VERSION "HNNBNNNYNNNNNNNNNNNNNNNNNNNNNNNNNNNNNNNNNN/4/%%%/4/'%**4NNN///"

NS_ :

BS_:

BU_: Airbag BAP_Tester ICAS1_Gateway ICAS1_KommunikationsServer LE1 LE2 Motor_BEV Schaltbetaetigung

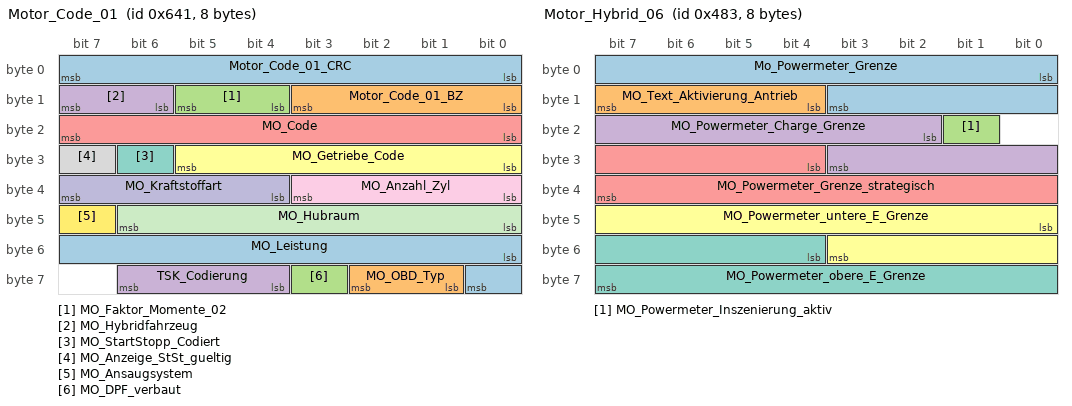
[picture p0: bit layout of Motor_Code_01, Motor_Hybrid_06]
BO_ 1601 Motor_Code_01: 8 Motor_BEV
 SG_ Motor_Code_01_CRC : 0|8@1+ (1,0) [0|255] ""  ICAS1_Gateway
 SG_ Motor_Code_01_BZ : 8|4@1+ (1,0) [0|15] ""  ICAS1_Gateway
 SG_ MO_Faktor_Momente_02 : 12|2@1+ (1,0) [1|3] "Unit_NewtoMeter"  ICAS1_Gateway
 SG_ MO_Hybridfahrzeug : 14|2@1+ (1.0,0.0) [0.0|3] ""  ICAS1_Gateway
 SG_ MO_Code : 16|8@1+ (1,0) [0|255] ""  ICAS1_Gateway
 SG_ MO_Getriebe_Code : 24|6@1+ (1.0,0.0) [0.0|63] ""  ICAS1_Gateway
 SG_ MO_StartStopp_Codiert : 30|1@1+ (1.0,0.0) [0.0|1] ""  ICAS1_Gateway
 SG_ MO_Anzeige_StSt_gueltig : 31|1@1+ (1.0,0.0) [0.0|1] ""  ICAS1_Gateway
 SG_ MO_Anzahl_Zyl : 32|4@1+ (1.0,0.0) [0.0|15] ""  ICAS1_Gateway
 SG_ MO_Kraftstoffart : 36|4@1+ (1.0,0.0) [0.0|15] ""  ICAS1_Gateway,ICAS1_KommunikationsServer
 SG_ MO_Hubraum : 40|7@1+ (0.1,0) [0.0|12.7] "Unit_Liter"  ICAS1_Gateway
 SG_ MO_Ansaugsystem : 47|1@1+ (1.0,0.0) [0.0|1] ""  ICAS1_Gateway
 SG_ MO_Leistung : 48|9@1+ (1,0) [0|511] "Unit_KiloWatt"  ICAS1_Gateway
 SG_ MO_OBD_Typ : 57|2@1+ (1.0,0.0) [0.0|3] ""  ICAS1_Gateway
 SG_ MO_DPF_verbaut : 59|1@1+ (1.0,0.0) [0.0|1] ""  ICAS1_Gateway
 SG_ TSK_Codierung : 60|3@1+ (1.0,0.0) [0.0|7] ""  ICAS1_Gateway

BO_ 1155 Motor_Hybrid_06: 8 Motor_BEV
 SG_ Mo_Powermeter_Grenze : 0|12@1+ (1,0) [0|4092] ""  ICAS1_KommunikationsServer
 SG_ MO_Text_Aktivierung_Antrieb : 12|4@1+ (1.0,0.0) [0.0|15] ""  ICAS1_KommunikationsServer
 SG_ MO_Powermeter_Inszenierung_aktiv : 17|1@1+ (1.0,0.0) [0.0|1] ""  Vector__XXX
 SG_ MO_Powermeter_Charge_Grenze : 18|10@1+ (1,0) [0|1021] "Unit_None"  ICAS1_KommunikationsServer
 SG_ MO_Powermeter_Grenze_strategisch : 28|12@1+ (1,0) [0|4093] "Unit_None"  ICAS1_KommunikationsServer
 SG_ MO_Powermeter_untere_E_Grenze : 40|12@1+ (1,0) [0|4093] "Unit_None"  Vector__XXX
 SG_ MO_Powermeter_obere_E_Grenze : 52|12@1+ (1,0) [0|4093] "Unit_None"  Vector__XXX

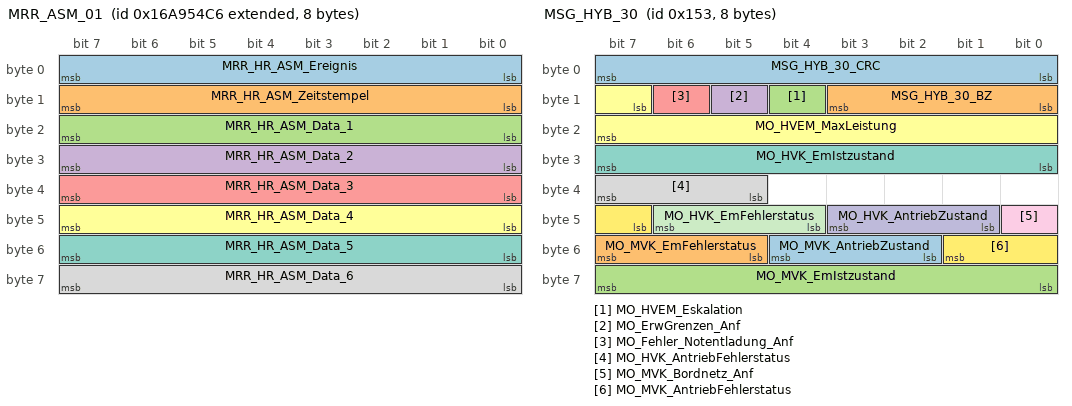
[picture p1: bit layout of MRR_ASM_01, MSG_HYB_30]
BO_ 2527679686 MRR_ASM_01: 8 ICAS1_Gateway
 SG_ MRR_HR_ASM_Ereignis : 0|8@1+ (1,0) [1|254] ""  Airbag
 SG_ MRR_HR_ASM_Zeitstempel : 8|8@1+ (0.08,0) [0.00|20.32] "Unit_Secon"  Airbag
 SG_ MRR_HR_ASM_Data_1 : 16|8@1+ (1,0) [0|255] ""  Airbag
 SG_ MRR_HR_ASM_Data_2 : 24|8@1+ (1,0) [0|255] ""  Airbag
 SG_ MRR_HR_ASM_Data_3 : 32|8@1+ (1,0) [0|255] ""  Airbag
 SG_ MRR_HR_ASM_Data_4 : 40|8@1+ (1,0) [0|255] ""  Airbag
 SG_ MRR_HR_ASM_Data_5 : 48|8@1+ (1,0) [0|255] ""  Airbag
 SG_ MRR_HR_ASM_Data_6 : 56|8@1+ (1,0) [0|255] ""  Airbag

BO_ 22 MSG3_WFS_Anfrage: 8 LE2
 SG_ WFS_MSG3_RND : 0|32@1+ (1.0,0.0) [0.0|4294967295] ""  ICAS1_Gateway
 SG_ WFS_MSG3_CRC : 32|32@1+ (1.0,0.0) [0.0|4294967295] ""  ICAS1_Gateway

BO_ 24 MSG4_WFS_Anfrage: 8 LE1
 SG_ WFS_MSG4_RND : 0|32@1+ (1.0,0.0) [0.0|4294967295] ""  ICAS1_Gateway
 SG_ WFS_MSG4_CRC : 32|32@1+ (1.0,0.0) [0.0|4294967295] ""  ICAS1_Gateway

BO_ 339 MSG_HYB_30: 8 Motor_BEV
 SG_ MSG_HYB_30_CRC : 0|8@1+ (1,0) [0|255] ""  Vector__XXX
 SG_ MSG_HYB_30_BZ : 8|4@1+ (1,0) [0|15] ""  Vector__XXX
 SG_ MO_HVEM_Eskalation : 12|1@1+ (1.0,0.0) [0.0|1] ""  ICAS1_Gateway
 SG_ MO_ErwGrenzen_Anf : 13|1@1+ (1.0,0.0) [0.0|1] ""  LE1,LE2
 SG_ MO_Fehler_Notentladung_Anf : 14|1@1+ (1.0,0.0) [0.0|1] ""  Vector__XXX
 SG_ MO_HVEM_MaxLeistung : 15|9@1+ (50,0) [0|25450] "Unit_Watt"  ICAS1_Gateway
 SG_ MO_HVK_EmIstzustand : 24|8@1+ (1.0,0.0) [0.0|255] ""  Vector__XXX
 SG_ MO_HVK_AntriebFehlerstatus : 37|3@1+ (1.0,0.0) [0.0|7] ""  Vector__XXX
 SG_ MO_MVK_Bordnetz_Anf : 40|1@1+ (1.0,0.0) [0.0|1] ""  Vector__XXX
 SG_ MO_HVK_AntriebZustand : 41|3@1+ (1.0,0.0) [0.0|7] ""  Vector__XXX
 SG_ MO_HVK_EmFehlerstatus : 44|3@1+ (1.0,0.0) [0.0|7] ""  Vector__XXX
 SG_ MO_MVK_AntriebFehlerstatus : 47|3@1+ (1.0,0.0) [0.0|7] ""  Vector__XXX
 SG_ MO_MVK_AntriebZustand : 50|3@1+ (1.0,0.0) [0.0|7] ""  Vector__XXX
 SG_ MO_MVK_EmFehlerstatus : 53|3@1+ (1.0,0.0) [0.0|7] ""  Vector__XXX
 SG_ MO_MVK_EmIstzustand : 56|8@1+ (1.0,0.0) [0.0|255] ""  Vector__XXX

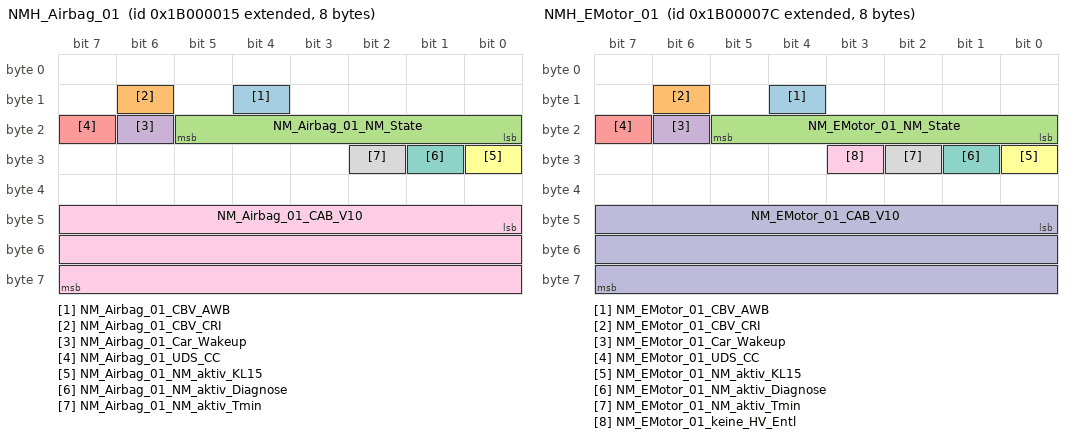
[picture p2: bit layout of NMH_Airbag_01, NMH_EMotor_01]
BO_ 2600468501 NMH_Airbag_01: 8 Airbag
 SG_ NM_Airbag_01_CBV_AWB : 12|1@1+ (1.0,0.0) [0.0|1] ""  ICAS1_Gateway
 SG_ NM_Airbag_01_CBV_CRI : 14|1@1+ (1.0,0.0) [0.0|1] ""  ICAS1_Gateway
 SG_ NM_Airbag_01_NM_State : 16|6@1+ (1.0,0.0) [0.0|63] ""  LE1,LE2,Motor_BEV,Schaltbetaetigung
 SG_ NM_Airbag_01_Car_Wakeup : 22|1@1+ (1.0,0.0) [0.0|1] ""  ICAS1_Gateway
 SG_ NM_Airbag_01_UDS_CC : 23|1@1+ (1.0,0.0) [0.0|1] ""  Vector__XXX
 SG_ NM_Airbag_01_NM_aktiv_KL15 : 24|1@1+ (1.0,0.0) [0.0|1] ""  Vector__XXX
 SG_ NM_Airbag_01_NM_aktiv_Diagnose : 25|1@1+ (1.0,0.0) [0.0|1] ""  Vector__XXX
 SG_ NM_Airbag_01_NM_aktiv_Tmin : 26|1@1+ (1.0,0.0) [0.0|1] ""  Vector__XXX
 SG_ NM_Airbag_01_CAB_V10 : 40|24@1+ (1.0,0.0) [0.0|16777215] ""  ICAS1_Gateway

BO_ 2600468604 NMH_EMotor_01: 8 LE1
 SG_ NM_EMotor_01_CBV_AWB : 12|1@1+ (1.0,0.0) [0.0|1] ""  ICAS1_Gateway
 SG_ NM_EMotor_01_CBV_CRI : 14|1@1+ (1.0,0.0) [0.0|1] ""  ICAS1_Gateway
 SG_ NM_EMotor_01_NM_State : 16|6@1+ (1.0,0.0) [0.0|63] ""  Airbag,LE2,Motor_BEV,Schaltbetaetigung
 SG_ NM_EMotor_01_Car_Wakeup : 22|1@1+ (1.0,0.0) [0.0|1] ""  ICAS1_Gateway
 SG_ NM_EMotor_01_UDS_CC : 23|1@1+ (1.0,0.0) [0.0|1] ""  Vector__XXX
 SG_ NM_EMotor_01_NM_aktiv_KL15 : 24|1@1+ (1.0,0.0) [0.0|1] ""  Vector__XXX
 SG_ NM_EMotor_01_NM_aktiv_Diagnose : 25|1@1+ (1.0,0.0) [0.0|1] ""  Vector__XXX
 SG_ NM_EMotor_01_NM_aktiv_Tmin : 26|1@1+ (1.0,0.0) [0.0|1] ""  Vector__XXX
 SG_ NM_EMotor_01_keine_HV_Entl : 27|1@1+ (1.0,0.0) [0.0|1] ""  Vector__XXX
 SG_ NM_EMotor_01_CAB_V10 : 40|24@1+ (1.0,0.0) [0.0|16777215] ""  ICAS1_Gateway

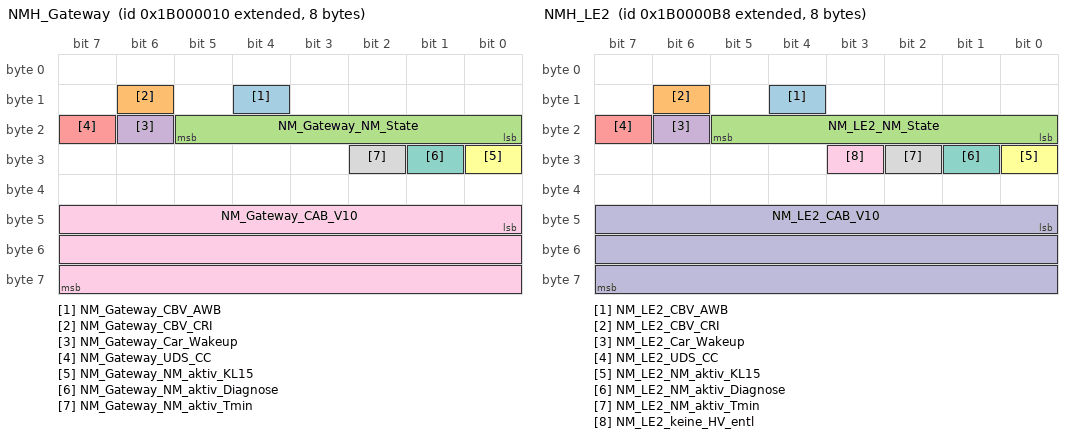
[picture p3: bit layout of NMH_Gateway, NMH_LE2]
BO_ 2600468496 NMH_Gateway: 8 ICAS1_Gateway
 SG_ NM_Gateway_CBV_AWB : 12|1@1+ (1.0,0.0) [0.0|1] ""  Vector__XXX
 SG_ NM_Gateway_CBV_CRI : 14|1@1+ (1.0,0.0) [0.0|1] ""  Vector__XXX
 SG_ NM_Gateway_NM_State : 16|6@1+ (1.0,0.0) [0.0|63] ""  Airbag,LE1,LE2,Motor_BEV,Schaltbetaetigung
 SG_ NM_Gateway_Car_Wakeup : 22|1@1+ (1.0,0.0) [0.0|1] ""  Vector__XXX
 SG_ NM_Gateway_UDS_CC : 23|1@1+ (1.0,0.0) [0.0|1] ""  Vector__XXX
 SG_ NM_Gateway_NM_aktiv_KL15 : 24|1@1+ (1.0,0.0) [0.0|1] ""  Vector__XXX
 SG_ NM_Gateway_NM_aktiv_Diagnose : 25|1@1+ (1.0,0.0) [0.0|1] ""  Vector__XXX
 SG_ NM_Gateway_NM_aktiv_Tmin : 26|1@1+ (1.0,0.0) [0.0|1] ""  Vector__XXX
 SG_ NM_Gateway_CAB_V10 : 40|24@1+ (1.0,0.0) [0.0|16777215] ""  Vector__XXX

BO_ 2600468664 NMH_LE2: 8 LE2
 SG_ NM_LE2_CBV_AWB : 12|1@1+ (1.0,0.0) [0.0|1] ""  ICAS1_Gateway
 SG_ NM_LE2_CBV_CRI : 14|1@1+ (1.0,0.0) [0.0|1] ""  ICAS1_Gateway
 SG_ NM_LE2_NM_State : 16|6@1+ (1.0,0.0) [0.0|63] ""  Airbag,LE1,Motor_BEV,Schaltbetaetigung
 SG_ NM_LE2_Car_Wakeup : 22|1@1+ (1.0,0.0) [0.0|1] ""  ICAS1_Gateway
 SG_ NM_LE2_UDS_CC : 23|1@1+ (1.0,0.0) [0.0|1] ""  Vector__XXX
 SG_ NM_LE2_NM_aktiv_KL15 : 24|1@1+ (1.0,0.0) [0.0|1] ""  Vector__XXX
 SG_ NM_LE2_NM_aktiv_Diagnose : 25|1@1+ (1.0,0.0) [0.0|1] ""  Vector__XXX
 SG_ NM_LE2_NM_aktiv_Tmin : 26|1@1+ (1.0,0.0) [0.0|1] ""  Vector__XXX
 SG_ NM_LE2_keine_HV_entl : 27|1@1+ (1.0,0.0) [0.0|1] ""  Vector__XXX
 SG_ NM_LE2_CAB_V10 : 40|24@1+ (1.0,0.0) [0.0|16777215] ""  ICAS1_Gateway

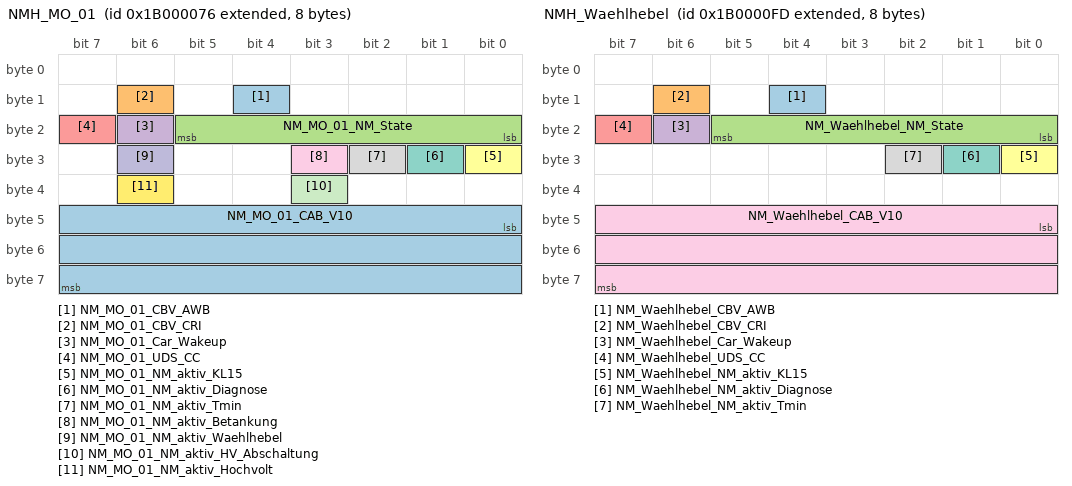
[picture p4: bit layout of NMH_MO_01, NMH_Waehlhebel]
BO_ 2600468598 NMH_MO_01: 8 Motor_BEV
 SG_ NM_MO_01_CBV_AWB : 12|1@1+ (1.0,0.0) [0.0|1] ""  ICAS1_Gateway
 SG_ NM_MO_01_CBV_CRI : 14|1@1+ (1.0,0.0) [0.0|1] ""  ICAS1_Gateway
 SG_ NM_MO_01_NM_State : 16|6@1+ (1.0,0.0) [0.0|63] ""  Airbag,LE1,LE2,Schaltbetaetigung
 SG_ NM_MO_01_Car_Wakeup : 22|1@1+ (1.0,0.0) [0.0|1] ""  ICAS1_Gateway
 SG_ NM_MO_01_UDS_CC : 23|1@1+ (1.0,0.0) [0.0|1] ""  Vector__XXX
 SG_ NM_MO_01_NM_aktiv_KL15 : 24|1@1+ (1.0,0.0) [0.0|1] ""  Vector__XXX
 SG_ NM_MO_01_NM_aktiv_Diagnose : 25|1@1+ (1.0,0.0) [0.0|1] ""  Vector__XXX
 SG_ NM_MO_01_NM_aktiv_Tmin : 26|1@1+ (1.0,0.0) [0.0|1] ""  Vector__XXX
 SG_ NM_MO_01_NM_aktiv_Betankung : 27|1@1+ (1.0,0.0) [0.0|1] ""  Vector__XXX
 SG_ NM_MO_01_NM_aktiv_Waehlhebel : 30|1@1+ (1.0,0.0) [0.0|1] ""  Vector__XXX
 SG_ NM_MO_01_NM_aktiv_HV_Abschaltung : 35|1@1+ (1.0,0.0) [0.0|1] ""  Vector__XXX
 SG_ NM_MO_01_NM_aktiv_Hochvolt : 38|1@1+ (1.0,0.0) [0.0|1] ""  Vector__XXX
 SG_ NM_MO_01_CAB_V10 : 40|24@1+ (1.0,0.0) [0.0|16777215] ""  ICAS1_Gateway

BO_ 2600468733 NMH_Waehlhebel: 8 Schaltbetaetigung
 SG_ NM_Waehlhebel_CBV_AWB : 12|1@1+ (1.0,0.0) [0.0|1] ""  ICAS1_Gateway
 SG_ NM_Waehlhebel_CBV_CRI : 14|1@1+ (1.0,0.0) [0.0|1] ""  ICAS1_Gateway
 SG_ NM_Waehlhebel_NM_State : 16|6@1+ (1.0,0.0) [0.0|63] ""  Airbag,LE1,LE2,Motor_BEV
 SG_ NM_Waehlhebel_Car_Wakeup : 22|1@1+ (1.0,0.0) [0.0|1] ""  ICAS1_Gateway
 SG_ NM_Waehlhebel_UDS_CC : 23|1@1+ (1.0,0.0) [0.0|1] ""  Vector__XXX
 SG_ NM_Waehlhebel_NM_aktiv_KL15 : 24|1@1+ (1.0,0.0) [0.0|1] ""  Vector__XXX
 SG_ NM_Waehlhebel_NM_aktiv_Diagnose : 25|1@1+ (1.0,0.0) [0.0|1] ""  Vector__XXX
 SG_ NM_Waehlhebel_NM_aktiv_Tmin : 26|1@1+ (1.0,0.0) [0.0|1] ""  Vector__XXX
 SG_ NM_Waehlhebel_CAB_V10 : 40|24@1+ (1.0,0.0) [0.0|16777215] ""  ICAS1_Gateway

BO_ 2621440533 OBDC_Airbag_01_Req_FD: 64 ICAS1_Gateway
 SG_ OBDC_Airbag_01_Req_FD_Data : 0|512@1+ (1.0,0.0) [0.0|13407807929942597099574024998205846127479365820592393377723561443721764030073546976801874298166903427690031858186486050853753882811946569946433649006084095] ""  Airbag

BO_ 2621571605 OBDC_Airbag_01_Resp_FD: 64 Airbag
 SG_ OBDC_Airbag_01_Resp_FD_Data : 0|512@1+ (1.0,0.0) [0.0|13407807929942597099574024998205846127479365820592393377723561443721764030073546976801874298166903427690031858186486050853753882811946569946433649006084095] ""  ICAS1_Gateway

BO_ 2621440636 OBDC_EMotor_01_Req_FD: 64 ICAS1_Gateway
 SG_ OBDC_EMotor_01_Req_FD_Data : 0|512@1+ (1.0,0.0) [0.0|13407807929942597099574024998205846127479365820592393377723561443721764030073546976801874298166903427690031858186486050853753882811946569946433649006084095] ""  LE1

BO_ 2621571708 OBDC_EMotor_01_Resp_FD: 64 LE1
 SG_ OBDC_EMotor_01_Resp_FD_Data : 0|512@1+ (1.0,0.0) [0.0|13407807929942597099574024998205846127479365820592393377723561443721764030073546976801874298166903427690031858186486050853753882811946569946433649006084095] ""  ICAS1_Gateway

BO_ 2621440696 OBDC_EMotor_02_Req_FD: 64 ICAS1_Gateway
 SG_ OBDC_EMotor_02_Req_FD_Data : 0|512@1+ (1.0,0.0) [0.0|13407807929942597099574024998205846127479365820592393377723561443721764030073546976801874298166903427690031858186486050853753882811946569946433649006084095] ""  LE2

BO_ 2621571768 OBDC_EMotor_02_Resp_FD: 64 LE2
 SG_ OBDC_EMotor_02_Resp_FD_Data : 0|512@1+ (1.0,0.0) [0.0|13407807929942597099574024998205846127479365820592393377723561443721764030073546976801874298166903427690031858186486050853753882811946569946433649006084095] ""  ICAS1_Gateway

BO_ 2621506048 OBDC_Funktionaler_Req_All_FD: 64 ICAS1_Gateway
 SG_ OBDC_Funktion_Req_All_FD_Data : 0|512@1+ (1.0,0.0) [0.0|13407807929942597099574024998205846127479365820592393377723561443721764030073546976801874298166903427690031858186486050853753882811946569946433649006084095] ""  Airbag,LE1,LE2,Motor_BEV

BO_ 2621440630 OBDC_MO_01_Req_FD: 64 ICAS1_Gateway
 SG_ OBDC_MO_01_Req_FD_Data : 0|512@1+ (1.0,0.0) [0.0|13407807929942597099574024998205846127479365820592393377723561443721764030073546976801874298166903427690031858186486050853753882811946569946433649006084095] ""  Motor_BEV

BO_ 2621571702 OBDC_MO_01_Resp_FD: 64 Motor_BEV
 SG_ OBDC_MO_01_Resp_FD_Data : 0|512@1+ (1.0,0.0) [0.0|13407807929942597099574024998205846127479365820592393377723561443721764030073546976801874298166903427690031858186486050853753882811946569946433649006084095] ""  ICAS1_Gateway

BO_ 2564502513 OBDx_allOBD_Req: 8 ICAS1_Gateway
 SG_ OBDx_allOBD_Req_Data : 0|64@1+ (1.0,0.0) [0.0|18446744073709551615] ""  LE1,LE2,Motor_BEV

BO_ 2564425457 OBDx_LE1_Req: 8 ICAS1_Gateway
 SG_ OBDx_LE1_Req_Data : 0|64@1+ (1.0,0.0) [0.0|18446744073709551615] ""  LE1

BO_ 2564485382 OBDx_LE1_Resp: 8 LE1
 SG_ OBDx_LE1_Resp_Data : 0|64@1+ (1.0,0.0) [0.0|18446744073709551615] ""  ICAS1_Gateway

BO_ 2564425713 OBDx_LE2_Req: 8 ICAS1_Gateway
 SG_ OBDx_LE2_Req_Data : 0|64@1+ (1.0,0.0) [0.0|18446744073709551615] ""  LE2

BO_ 2564485383 OBDx_LE2_Resp: 8 LE2
 SG_ OBDx_LE2_Resp_Data : 0|64@1+ (1.0,0.0) [0.0|18446744073709551615] ""  ICAS1_Gateway

BO_ 2564424177 OBDx_MO_01_Req: 8 ICAS1_Gateway
 SG_ OBDx_MO_01_Req_Data : 0|64@1+ (1.0,0.0) [0.0|18446744073709551615] ""  Motor_BEV

BO_ 2564485377 OBDx_MO_01_Resp: 8 Motor_BEV
 SG_ OBDx_MO_01_Resp_Data : 0|64@1+ (1.0,0.0) [0.0|18446744073709551615] ""  ICAS1_Gateway

BO_ 627 OCC_01: 24 ICAS1_Gateway
 SG_ OCC_01_CRC : 0|8@1+ (1,0) [0|255] ""  Vector__XXX
 SG_ OCC_01_BZ : 8|4@1+ (1,0) [0|15] ""  Vector__XXX
 SG_ OCC_Stecker_Status : 12|2@1+ (1.0,0.0) [0.0|3] ""  Vector__XXX
 SG_ OCC_Status_Spgfreiheit : 14|2@1+ (1.0,0.0) [0.0|3] ""  Motor_BEV
 SG_ OCC_DC_IstStrom : 16|11@1+ (0.1,0) [0.0|204.5] "Unit_Amper"  Vector__XXX
 SG_ OCC_CC_Latchstatus_DC_GBT : 27|3@1+ (1.0,0.0) [0.0|7] ""  Vector__XXX
 SG_ OCC_Status_EoHVL : 30|2@1+ (1.0,0.0) [0.0|3] ""  Motor_BEV
 SG_ OCC_I_istAC_Netz_L1 : 32|9@1+ (0.1,0) [0.0|50.8] "Unit_Amper"  Vector__XXX
 SG_ OCC_PP_Latchstatus_A : 41|3@1+ (1.0,0.0) [0.0|7] ""  Vector__XXX
 SG_ OCC_PP_Latchstatus_B : 44|3@1+ (1.0,0.0) [0.0|7] ""  Vector__XXX
 SG_ OCC_I_istAC_Netz_L2 : 47|9@1+ (0.1,0) [0.0|50.8] "Unit_Amper"  Vector__XXX
 SG_ OCC_I_istAC_Netz_L3 : 56|9@1+ (0.1,0) [0.0|50.8] "Unit_Amper"  Vector__XXX
 SG_ OCC_IstModus : 65|3@1+ (1.0,0.0) [0.0|7] ""  Motor_BEV
 SG_ OCC_CP_Status_A : 68|2@1+ (1.0,0.0) [0.0|3] ""  Vector__XXX
 SG_ OCC_CP_Status_B : 70|2@1+ (1.0,0.0) [0.0|3] ""  Vector__XXX
 SG_ OCC_IstSpannung_HV : 72|10@1+ (1,0) [0|1021] "Unit_Volt"  Vector__XXX
 SG_ OCC_PP_Status_A : 82|2@1+ (1.0,0.0) [0.0|3] ""  Vector__XXX
 SG_ OCC_PP_Status_B : 84|2@1+ (1.0,0.0) [0.0|3] ""  Vector__XXX
 SG_ OCC_CC_Status_DC_GBT : 86|2@1+ (1.0,0.0) [0.0|3] ""  Vector__XXX
 SG_ OCC_CC_Fehlerstatus_DC_GBT : 88|4@1+ (1.0,0.0) [0.0|15] ""  Vector__XXX
 SG_ OCC_Temp_Sensor_Fehlerstatus_DC : 92|4@1+ (1.0,0.0) [0.0|15] ""  Vector__XXX
 SG_ OCC_Temp_Sensor_Fehlerstatus_AC : 96|3@1+ (1.0,0.0) [0.0|7] ""  Vector__XXX
 SG_ OCC_Temp_Sensor_Status : 99|3@1+ (1.0,0.0) [0.0|7] ""  Vector__XXX

BO_ 2463978709 OCC_02: 32 ICAS1_Gateway
 SG_ OCC_CP_Tastgrad_A : 12|10@1+ (0.1,0) [0.0|100.0] "Unit_PerCent"  Vector__XXX
 SG_ OCC_CP_Tastgrad_B : 22|10@1+ (0.1,0) [0.0|100.0] "Unit_PerCent"  Vector__XXX
 SG_ OCC_CP_Frequenz_A : 32|8@1+ (1,880) [880|1132] "Unit_Hertz"  Vector__XXX
 SG_ OCC_CP_Frequenz_B : 40|8@1+ (1,880) [880|1132] "Unit_Hertz"  Vector__XXX
 SG_ OCC_CP_Spannung_A : 48|9@1+ (0.1,-25) [-25.0|25.9] "Unit_Volt"  Vector__XXX
 SG_ OCC_CP_Spannung_B : 57|9@1+ (0.1,-25) [-25.0|25.9] "Unit_Volt"  Vector__XXX
 SG_ OCC_CP_Fehlerstatus_A : 66|3@1+ (1.0,0.0) [0.0|7] ""  Vector__XXX
 SG_ OCC_CP_Fehlerstatus_B : 69|3@1+ (1.0,0.0) [0.0|7] ""  Vector__XXX
 SG_ OCC_Temp_Ladedose_A_AC : 72|8@1+ (1,-40) [-40|213] "Unit_DegreCelsi"  Vector__XXX
 SG_ OCC_Temp_Ladedose_A_DC_minus : 80|8@1+ (1,-40) [-40|213] "Unit_DegreCelsi"  Vector__XXX
 SG_ OCC_Temp_Ladedose_A_DC_plus : 88|8@1+ (1,-40) [-40|213] "Unit_DegreCelsi"  Vector__XXX
 SG_ OCC_U_istAC_Netz_L1 : 96|9@1+ (1,0) [0|509] "Unit_Volt"  Vector__XXX
 SG_ OCC_U_istAC_Netz_L2 : 105|9@1+ (1,0) [0|509] "Unit_Volt"  Vector__XXX
 SG_ OCC_U_istAC_Netz_L3 : 114|9@1+ (1,0) [0|508] "Unit_Volt"  Vector__XXX
 SG_ OCC_StatusVerEntriegelungAktor_A : 123|3@1+ (1.0,0.0) [0.0|7] ""  Vector__XXX
 SG_ OCC_SteckerEntriegelung_Verbot_A : 126|2@1+ (1.0,0.0) [0.0|3] ""  Vector__XXX
 SG_ OCC_StatusVerEntriegelungAktor_B : 128|3@1+ (1.0,0.0) [0.0|7] ""  Vector__XXX
 SG_ OCC_SteckerEntriegelung_Verbot_B : 131|2@1+ (1.0,0.0) [0.0|3] ""  Vector__XXX
 SG_ OCC_Verriegelung_Status_A : 133|3@1+ (1.0,0.0) [0.0|7] ""  Vector__XXX
 SG_ OCC_Verriegelung_Status_B : 136|3@1+ (1.0,0.0) [0.0|7] ""  Vector__XXX
 SG_ OCC_RtmWarnLadeKommunikation : 139|3@1+ (1.0,0.0) [0.0|7] ""  Vector__XXX
 SG_ OCC_Ist_Wirkungsgrad : 145|7@1+ (1,0) [0|100] "Unit_PerCent"  Vector__XXX
 SG_ OCC_PP_Max_Strom_A : 152|4@1+ (1.0,0.0) [0.0|15] ""  Vector__XXX
 SG_ OCC_PP_Max_Strom_B : 156|4@1+ (1.0,0.0) [0.0|15] ""  Vector__XXX
 SG_ OCC_DC_MaxStrom : 160|11@1+ (0.1,0) [0.0|204.5] "Unit_Amper"  Vector__XXX
 SG_ OCC_Derating_Temperatur : 171|1@1+ (1.0,0.0) [0.0|1] ""  Vector__XXX
 SG_ OCC_Fehlerzustand : 172|1@1+ (1.0,0.0) [0.0|1] ""  Vector__XXX
 SG_ OCC_Ladest_Entriegelungs_Verbot : 173|3@1+ (1.0,0.0) [0.0|7] ""  Vector__XXX
 SG_ OCC_Netzfrequenz_EVU : 176|9@1+ (0.1,40) [40.0|80.0] "Unit_Hertz"  Vector__XXX
 SG_ OCC_Warnzustand : 185|1@1+ (1.0,0.0) [0.0|1] ""  Vector__XXX
 SG_ OCC_Kuehltemperatur : 192|8@1+ (1,-40) [-40|213] "Unit_DegreCelsi"  Motor_BEV
 SG_ OCC_PP_Fehlerstatus_A : 200|4@1+ (1.0,0.0) [0.0|15] ""  Vector__XXX
 SG_ OCC_PP_Fehlerstatus_B : 204|4@1+ (1.0,0.0) [0.0|15] ""  Vector__XXX

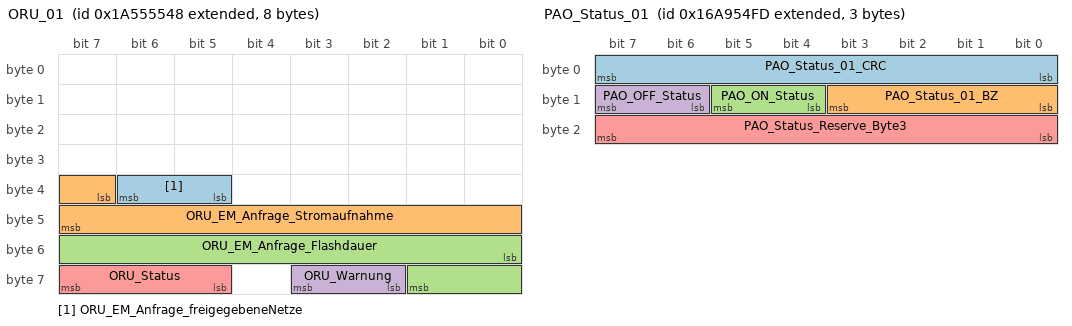
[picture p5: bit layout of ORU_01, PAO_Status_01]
BO_ 2589283656 ORU_01: 8 ICAS1_Gateway
 SG_ ORU_EM_Anfrage_freigegebeneNetze : 37|2@1+ (1.0,0.0) [0.0|3] ""  Vector__XXX
 SG_ ORU_EM_Anfrage_Stromaufnahme : 39|9@1+ (0.1,0) [0.0|51.1] "Unit_Amper"  Vector__XXX
 SG_ ORU_EM_Anfrage_Flashdauer : 48|10@1+ (10,0) [0|10230] "Unit_Secon"  Vector__XXX
 SG_ ORU_Warnung : 58|2@1+ (1.0,0.0) [0.0|3] ""  Vector__XXX
 SG_ ORU_Status : 61|3@1+ (1.0,0.0) [0.0|7] ""  Airbag,LE1,LE2,Motor_BEV

BO_ 2527679741 PAO_Status_01: 3 ICAS1_Gateway
 SG_ PAO_Status_01_CRC : 0|8@1+ (1,0) [0|255] ""  Airbag
 SG_ PAO_Status_01_BZ : 8|4@1+ (1,0) [0|15] ""  Airbag
 SG_ PAO_ON_Status : 12|2@1+ (1.0,0.0) [0.0|3] ""  Airbag
 SG_ PAO_OFF_Status : 14|2@1+ (1.0,0.0) [0.0|3] ""  Airbag
 SG_ PAO_Status_Reserve_Byte3 : 16|8@1+ (1.0,0.0) [0.0|255] ""  Vector__XXX

BO_ 518 Parken_01: 24 ICAS1_Gateway
 SG_ Parken_BKD_Anf : 12|4@1+ (0.1,0) [0.0|1.3] "Unit_Secon"  Vector__XXX
 SG_ Parken_Verz_Anf : 16|7@1+ (0.1,-12.6) [-12.6|-0.1] "Unit_MeterPerSeconSquar"  Vector__XXX
 SG_ Parken_Prefill_Anf : 23|1@1+ (1.0,0.0) [0.0|1] ""  Vector__XXX
 SG_ Parken_Warnruck_Anf : 24|2@1+ (1.0,0.0) [0.0|3] ""  Vector__XXX
 SG_ Parken_Verz_Anf_ASIL : 26|2@1+ (1.0,0.0) [0.0|3] ""  Vector__XXX
 SG_ Parken_Warnruckeln_Anf : 28|2@1+ (1.0,0.0) [0.0|3] ""  Vector__XXX
 SG_ Parken_beibehalten : 30|2@1+ (1.0,0.0) [0.0|3] ""  Vector__XXX
 SG_ Parken_Anforderung_HMS : 32|3@1+ (1.0,0.0) [0.0|7] ""  Vector__XXX
 SG_ Parken_Notstopp_Anf : 40|2@1+ (1.0,0.0) [0.0|3] ""  Vector__XXX
 SG_ Parken_Anhalteweg_Anf : 42|10@1+ (0.01,0) [0.00|10.21] "Unit_Meter"  Vector__XXX
 SG_ Parken_aktives_System : 52|4@1+ (1.0,0.0) [0.0|15] ""  Motor_BEV
 SG_ Parken_max_Beschleunigung : 56|7@1+ (0.1,-6) [-5.9|6.1] "Unit_MeterPerSeconSquar"  Motor_BEV
 SG_ Parken_Blinker_li_Anf : 63|1@1+ (1.0,0.0) [0.0|1] ""  Vector__XXX
 SG_ Parken_QFK_KruemmSoll : 64|15@1+ (0.0000067,0) [0E-7|0.2195389] "Unit_MeterInver"  Vector__XXX
 SG_ Parken_QFK_KruemmSoll_VZ : 79|1@1+ (1.0,0.0) [0.0|1] ""  Vector__XXX
 SG_ Parken_QFK_Spuerb : 80|8@1+ (0.4,0) [0.0|100.0] "Unit_PerCent"  Vector__XXX
 SG_ Parken_QFK_AnfStat : 88|4@1+ (1.0,0.0) [0.0|15] ""  Vector__XXX
 SG_ Parken_QFK_Signal1 : 92|10@1+ (1,0) [0|1023] ""  Vector__XXX
 SG_ Parken_QFK_Art1 : 102|3@1+ (1,0) [0|7] ""  Vector__XXX
 SG_ Parken_QFK_Art2 : 105|3@1+ (1,0) [0|7] ""  Vector__XXX
 SG_ Parken_QFK_Signal2 : 108|10@1+ (1,0) [0|1023] ""  Vector__XXX
 SG_ Parken_Sollbeschleunigung : 118|9@1+ (0.01,-4.11) [-4.10|1.00] "Unit_MeterPerSeconSquar"  Motor_BEV
 SG_ Parken_Blinker_re_Anf : 127|1@1+ (1.0,0.0) [0.0|1] ""  Vector__XXX
 SG_ Parken_Status_IPA_TSK : 128|4@1+ (1.0,0.0) [0.0|15] ""  Motor_BEV
 SG_ Parken_erhoehtes_Moment : 132|4@1+ (1.0,0.0) [0.0|15] ""  Motor_BEV
 SG_ Parken_max_Geschwindigkeit : 136|8@1+ (0.1,0) [0.1|25.0] "Unit_KiloMeterPerHour"  Motor_BEV
 SG_ Parken_Soll_Anhalteweg_Anf : 144|10@1+ (0.01,0) [0.00|10.21] "Unit_Meter"  Vector__XXX
 SG_ Parken_Fahrstufenwunsch : 154|3@1+ (1.0,0.0) [0.0|7] ""  Motor_BEV
 SG_ IPA_TPA_Remote : 157|2@1+ (1.0,0.0) [0.0|3] ""  Vector__XXX
 SG_ IPA_TPA_Remote_Anf : 159|1@1+ (1.0,0.0) [0.0|1] ""  Vector__XXX
 SG_ IPA_TPA_Fehler : 160|4@1+ (1.0,0.0) [0.0|15] ""  Vector__XXX
 SG_ IPA_TPA_Abbruch : 164|4@1+ (1.0,0.0) [0.0|15] ""  Vector__XXX
 SG_ IPA_TPA_Status : 168|4@1+ (1.0,0.0) [0.0|15] ""  Vector__XXX

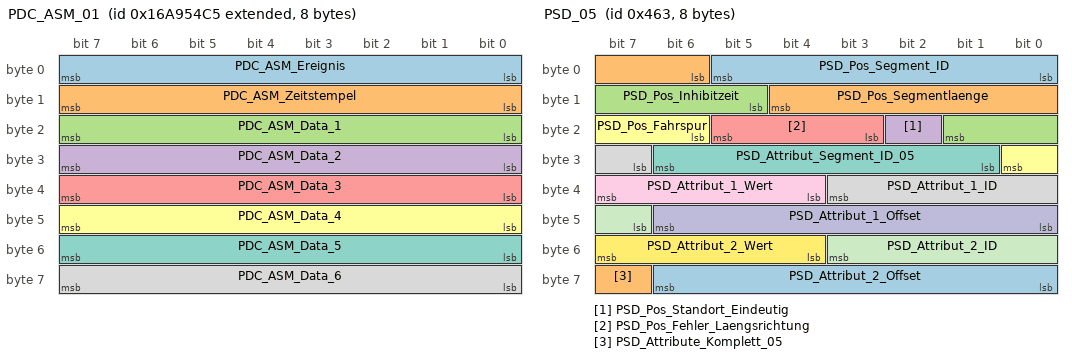
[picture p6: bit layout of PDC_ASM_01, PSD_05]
BO_ 2527679685 PDC_ASM_01: 8 ICAS1_Gateway
 SG_ PDC_ASM_Ereignis : 0|8@1+ (1,0) [1|254] ""  Airbag
 SG_ PDC_ASM_Zeitstempel : 8|8@1+ (0.08,0) [0.00|20.32] "Unit_Secon"  Airbag
 SG_ PDC_ASM_Data_1 : 16|8@1+ (1,0) [0|255] ""  Airbag
 SG_ PDC_ASM_Data_2 : 24|8@1+ (1,0) [0|255] ""  Airbag
 SG_ PDC_ASM_Data_3 : 32|8@1+ (1,0) [0|255] ""  Airbag
 SG_ PDC_ASM_Data_4 : 40|8@1+ (1,0) [0|255] ""  Airbag
 SG_ PDC_ASM_Data_5 : 48|8@1+ (1,0) [0|255] ""  Airbag
 SG_ PDC_ASM_Data_6 : 56|8@1+ (1,0) [0|255] ""  Airbag

BO_ 319 PreCrash_02: 8 Airbag
 SG_ PreCrash_Charisma_FahrPr : 12|4@1+ (1.0,0.0) [0.0|15] ""  ICAS1_Gateway
 SG_ PreCrash_Charisma_Status : 16|2@1+ (1.0,0.0) [0.0|3] ""  ICAS1_Gateway
 SG_ PreCrash_Schiebedach_schliessen : 18|1@1+ (1.0,0.0) [0.0|1] ""  ICAS1_Gateway
 SG_ PreCrash_Fenster_schliessen : 19|1@1+ (1.0,0.0) [0.0|1] ""  ICAS1_Gateway
 SG_ PreCrash_Blinken : 20|3@1+ (1.0,0.0) [0.0|7] ""  ICAS1_Gateway
 SG_ SC_PreSense_FCWP : 23|1@1+ (1.0,0.0) [0.0|1] ""  ICAS1_Gateway
 SG_ PreCrash_Tueren_Verriegeln : 24|1@1+ (1.0,0.0) [0.0|1] ""  ICAS1_Gateway
 SG_ PreCrash_FS_Laengsverstellung : 25|1@1+ (1.0,0.0) [0.0|1] ""  ICAS1_Gateway
 SG_ PreCrash_Anforderung_AFR : 26|3@1+ (1.0,0.0) [0.0|7] ""  ICAS1_Gateway
 SG_ SC_PreCrash_LED : 29|2@1+ (1.0,0.0) [0.0|3] ""  ICAS1_Gateway
 SG_ PreCrash_FS_Pneumatik_ansteuern : 31|1@1+ (1.0,0.0) [0.0|1] ""  ICAS1_Gateway
 SG_ PreCrash_BFS_Pneumatik_ansteuern : 32|1@1+ (1.0,0.0) [0.0|1] ""  ICAS1_Gateway
 SG_ PreCrash_Fo_Pneumatik_ansteuern : 33|1@1+ (1.0,0.0) [0.0|1] ""  ICAS1_Gateway
 SG_ PreCrash_FS_Sitzlehne_verfahren : 34|3@1+ (1.0,0.0) [0.0|7] ""  ICAS1_Gateway
 SG_ PreCrash_BFS_Sitzlehne_verfahren : 37|3@1+ (1.0,0.0) [0.0|7] ""  ICAS1_Gateway
 SG_ PreCrash_Fo_Sitzlehne_verfahren : 40|3@1+ (1.0,0.0) [0.0|7] ""  ICAS1_Gateway
 SG_ PreCrash_FS_KSV_verfahren : 43|4@1+ (1.0,0.0) [0.0|15] ""  ICAS1_Gateway
 SG_ PreCrash_BFS_KSV_verfahren : 47|4@1+ (1.0,0.0) [0.0|15] ""  ICAS1_Gateway
 SG_ PreCrash_Fo_KSV_verfahren : 51|4@1+ (1.0,0.0) [0.0|15] ""  ICAS1_Gateway
 SG_ PreCrash_BFS_Laengsverstellung : 55|1@1+ (1.0,0.0) [0.0|1] ""  ICAS1_Gateway
 SG_ SC_PreCrash_Warnung : 56|4@1+ (1.0,0.0) [0.0|15] ""  ICAS1_Gateway,ICAS1_KommunikationsServer
 SG_ SC_PreCrash_Texte : 60|4@1+ (1.0,0.0) [0.0|15] ""  ICAS1_Gateway,ICAS1_KommunikationsServer

BO_ 1122 PSD_04: 8 ICAS1_Gateway
 SG_ PSD_Segment_ID : 0|6@1+ (1,0) [2|63] ""  Motor_BEV
 SG_ PSD_Vorgaenger_Segment_ID : 6|6@1+ (1,0) [2|63] ""  Motor_BEV
 SG_ PSD_Segmentlaenge : 12|7@1+ (2,0) [0|254] "Unit_Meter"  Motor_BEV
 SG_ PSD_Strassenkategorie : 19|3@1+ (1.0,0.0) [0.0|7] ""  Motor_BEV
 SG_ PSD_Endkruemmung : 22|8@1+ (1,0) [0|254] "Unit_None"  Motor_BEV
 SG_ PSD_Endkruemmung_Vorz : 30|1@1+ (1.0,0.0) [0.0|1] ""  Motor_BEV
 SG_ PSD_Idenditaets_ID : 31|6@1+ (1,0) [2|63] ""  Vector__XXX
 SG_ PSD_ADAS_Qualitaet : 37|1@1+ (1.0,0.0) [0.0|1] ""  Motor_BEV
 SG_ PSD_wahrscheinlichster_Pfad : 38|1@1+ (1.0,0.0) [0.0|1] ""  Motor_BEV
 SG_ PSD_Geradester_Pfad : 39|1@1+ (1.0,0.0) [0.0|1] ""  Motor_BEV
 SG_ PSD_Fahrspuren_Anzahl : 40|3@1+ (1.0,0.0) [0.0|7] ""  Motor_BEV
 SG_ PSD_Bebauung : 43|1@1+ (1.0,0.0) [0.0|1] ""  Motor_BEV
 SG_ PSD_Segment_Komplett : 44|1@1+ (1.0,0.0) [0.0|1] ""  Motor_BEV
 SG_ PSD_Rampe : 45|2@1+ (1.0,0.0) [0.0|3] ""  Motor_BEV
 SG_ PSD_Anfangskruemmung : 47|8@1+ (1,0) [0|254] ""  Motor_BEV
 SG_ PSD_Anfangskruemmung_Vorz : 55|1@1+ (1.0,0.0) [0.0|1] ""  Motor_BEV
 SG_ PSD_Abzweigerichtung : 56|1@1+ (1.0,0.0) [0.0|1] ""  Motor_BEV
 SG_ PSD_Abzweigewinkel : 57|7@1+ (1.417323,0) [0.000000|180.000021] ""  Motor_BEV

BO_ 1123 PSD_05: 8 ICAS1_Gateway
 SG_ PSD_Pos_Segment_ID : 0|6@1+ (1,0) [2|63] ""  Motor_BEV
 SG_ PSD_Pos_Segmentlaenge : 6|7@1+ (2,0) [0|254] "Unit_Meter"  Motor_BEV
 SG_ PSD_Pos_Inhibitzeit : 13|5@1+ (10,0) [0|310] "Unit_MilliSecon"  Motor_BEV
 SG_ PSD_Pos_Standort_Eindeutig : 18|1@1+ (1.0,0.0) [0.0|1] ""  Motor_BEV
 SG_ PSD_Pos_Fehler_Laengsrichtung : 19|3@1+ (1.0,0.0) [0.0|7] ""  Motor_BEV
 SG_ PSD_Pos_Fahrspur : 22|3@1+ (1.0,0.0) [0.0|7] ""  Motor_BEV
 SG_ PSD_Attribut_Segment_ID_05 : 25|6@1+ (1,0) [2|63] ""  Motor_BEV
 SG_ PSD_Attribut_1_ID : 31|5@1+ (1,0) [1|31] ""  Motor_BEV
 SG_ PSD_Attribut_1_Wert : 36|4@1+ (1.0,0.0) [0.0|15] ""  Motor_BEV
 SG_ PSD_Attribut_1_Offset : 40|7@1+ (2,0) [0|254] "Unit_Meter"  Motor_BEV
 SG_ PSD_Attribut_2_ID : 47|5@1+ (1,0) [1|31] ""  Motor_BEV
 SG_ PSD_Attribut_2_Wert : 52|4@1+ (1.0,0.0) [0.0|15] ""  Motor_BEV
 SG_ PSD_Attribut_2_Offset : 56|7@1+ (2,0) [0|254] "Unit_Meter"  Motor_BEV
 SG_ PSD_Attribute_Komplett_05 : 63|1@1+ (1.0,0.0) [0.0|1] ""  Motor_BEV

BO_ 1124 PSD_06: 8 ICAS1_Gateway
 SG_ PSD_06_Mux M  : 0|3@1+ (1.0,0.0) [0.0|7] ""  Motor_BEV
 SG_ PSD_Sys_Segment_ID m0  : 3|6@1+ (1,0) [2|63] ""  Motor_BEV
 SG_ PSD_Attribut_Segment_ID m1  : 3|6@1+ (1,0) [2|63] ""  Motor_BEV
 SG_ PSD_Ges_Segment_ID m2  : 3|6@1+ (1,0) [2|63] ""  Motor_BEV
 SG_ PSD_Baum_Laenge_VZ m3  : 3|1@1+ (1.0,0.0) [0.0|1] ""  Motor_BEV
 SG_ PSD_Steigung_1_Segment_ID m4  : 3|6@1+ (1,0) [2|63] ""  Motor_BEV
 SG_ PSD_Baum_Laenge m3  : 4|25@1+ (0.00001,0) [0.00000|180.00000] "Unit_DegreOfArc"  Motor_BEV
 SG_ PSD_Sys_Laendercode m0  : 9|8@1+ (1.0,0.0) [0.0|255] ""  Motor_BEV
 SG_ PSD_Attribut_3_ID m1  : 9|5@1+ (1,0) [1|31] ""  Motor_BEV
 SG_ PSD_Ges_Offset m2  : 9|7@1+ (2,0) [0|254] "Unit_Meter"  Motor_BEV
 SG_ PSD_Steigung_1_A_Steigung m4  : 9|7@1+ (0.12,0) [0.00|15.00] "Unit_PerCent"  Motor_BEV
 SG_ PSD_Attribut_3_Offset m1  : 14|7@1+ (2,0) [0|254] "Unit_Meter"  Motor_BEV
 SG_ PSD_Ges_Geschwindigkeit m2  : 16|5@1+ (1.0,0.0) [0.0|31] ""  Motor_BEV
 SG_ PSD_Steigung_1_A_Vorz m4  : 16|1@1+ (1.0,0.0) [0.0|1] ""  Motor_BEV
 SG_ PSD_Sys_Geschwindigkeit_Einheit m0  : 17|1@1+ (1.0,0.0) [0.0|1] ""  Motor_BEV
 SG_ PSD_Steigung_1_A_Offset m4  : 17|7@1+ (2,0) [0|254] "Unit_Meter"  Motor_BEV
 SG_ PSD_Sys_Verkehrsrichtung m0  : 18|1@1+ (1.0,0.0) [0.0|1] ""  Motor_BEV
 SG_ PSD_Sys_Geometrieguete m0  : 19|2@1+ (1.0,0.0) [0.0|3] ""  Motor_BEV
 SG_ PSD_Sys_Mapmatchingguete m0  : 21|2@1+ (1.0,0.0) [0.0|3] ""  Motor_BEV
 SG_ PSD_Attribut_3_Wert m1  : 21|4@1+ (1.0,0.0) [0.0|15] ""  Motor_BEV
 SG_ PSD_Ges_Typ m2  : 21|2@1+ (1.0,0.0) [0.0|3] ""  Motor_BEV
 SG_ PSD_Sys_Alter_Karte m0  : 23|3@1+ (1.0,0.0) [0.0|7] ""  Motor_BEV
 SG_ PSD_Ges_Spur_Geschw_Begrenzung m2  : 23|6@1+ (1.0,0.0) [0.0|63] ""  Motor_BEV
 SG_ PSD_Steigung_1_B_Steigung m4  : 24|7@1+ (0.12,0) [0.00|15.00] "Unit_PerCent"  Motor_BEV
 SG_ PSD_Attribut_4_ID m1  : 25|5@1+ (1,0) [1|31] ""  Motor_BEV
 SG_ PSD_Sys_Zielfuehrung m0  : 26|1@1+ (1.0,0.0) [0.0|1] ""  Motor_BEV
 SG_ PSD_Sys_US_State m0  : 27|6@1+ (1.0,0.0) [0.0|63] ""  Motor_BEV
 SG_ PSD_Ges_Geschwindigkeit_Gespann m2  : 29|2@1+ (1.0,0.0) [0.0|3] ""  Motor_BEV
 SG_ PSD_Baum_Breite_VZ m3  : 29|1@1+ (1.0,0.0) [0.0|1] ""  Motor_BEV
 SG_ PSD_Attribut_4_Wert m1  : 30|4@1+ (1,0) [0|15] ""  Motor_BEV
 SG_ PSD_Baum_Breite m3  : 30|24@1+ (0.00001,0) [0.00000|90.00000] "Unit_DegreOfArc"  Motor_BEV
 SG_ PSD_Ges_Geschwindigkeit_Witter m2  : 31|2@1+ (1.0,0.0) [0.0|3] ""  Motor_BEV
 SG_ PSD_Steigung_1_B_Vorz m4  : 31|1@1+ (1.0,0.0) [0.0|1] ""  Motor_BEV
 SG_ PSD_Steigung_1_B_Offset m4  : 32|7@1+ (2,0) [0|254] "Unit_Meter"  Motor_BEV
 SG_ PSD_Sys_Quali_Geometrien m0  : 33|3@1+ (1,0) [0|7] "Unit_None"  Vector__XXX
 SG_ PSD_Ges_Geschwindigkeit_Tag_Anf m2  : 33|3@1+ (1.0,0.0) [0.0|7] ""  Motor_BEV
 SG_ PSD_Attribut_4_Offset m1  : 34|7@1+ (2,0) [0|254] "Unit_Meter"  Motor_BEV
 SG_ PSD_Sys_Quali_Ortsinfo m0  : 36|2@1+ (1,0) [0|3] "Unit_None"  Vector__XXX
 SG_ PSD_Ges_Geschwindigkeit_Tag_Ende m2  : 36|3@1+ (1.0,0.0) [0.0|7] ""  Motor_BEV
 SG_ PSD_Sys_Quali_verfuegbar m0  : 38|1@1+ (1.0,0.0) [0.0|1] ""  Vector__XXX
 SG_ PSD_Sys_Zielfuehrung_geaendert m0  : 39|1@1+ (1.0,0.0) [0.0|1] ""  Motor_BEV
 SG_ PSD_Ges_Geschwindigkeit_Std_Anf m2  : 39|5@1+ (1,0) [0|24] "Unit_Hours"  Motor_BEV
 SG_ PSD_Steigung_1_Attribute_kompl m4  : 39|1@1+ (1.0,0.0) [0.0|1] ""  Motor_BEV
 SG_ PSD_Sys_Geometrieguete_erweitert m0  : 40|8@1+ (1.0,0.0) [0.0|255] ""  Vector__XXX
 SG_ PSD_Steigung_2_Segment_ID m4  : 40|6@1+ (1,0) [2|63] ""  Motor_BEV
 SG_ PSD_Attribut_5_ID m1  : 41|5@1+ (1,0) [1|31] ""  Motor_BEV
 SG_ PSD_Ges_Geschwindigkeit_Std_Ende m2  : 44|5@1+ (1,0) [0|24] "Unit_Hours"  Motor_BEV
 SG_ PSD_Attribut_5_Offset m1  : 46|7@1+ (2,0) [0|254] "Unit_Meter"  Motor_BEV
 SG_ PSD_Steigung_2_Steigung m4  : 46|7@1+ (0.12,0) [0.00|15.00] "Unit_PerCent"  Motor_BEV
 SG_ PSD_Sys_Quali_sonstige_Attribute m0  : 48|3@1+ (1,0) [0|7] "Unit_None"  Vector__XXX
 SG_ PSD_Ges_Ueberholverbot m2  : 49|2@1+ (1.0,0.0) [0.0|3] ""  Vector__XXX
 SG_ PSD_Sys_Quali_Steigungen m0  : 51|3@1+ (1,0) [0|7] ""  Vector__XXX
 SG_ PSD_Ges_Wechselverkehrszeichen m2  : 51|3@1+ (1.0,0.0) [0.0|7] ""  Vector__XXX
 SG_ PSD_Attribut_5_Wert m1  : 53|4@1+ (1,0) [0|15] ""  Motor_BEV
 SG_ PSD_Steigung_2_Vorz m4  : 53|1@1+ (1.0,0.0) [0.0|1] ""  Motor_BEV
 SG_ PSD_Sys_Quali_Strassenkennz m0  : 54|3@1+ (1,0) [0|7] "Unit_None"  Vector__XXX
 SG_ PSD_Wechselverkehrszeichen_Typ m2  : 54|2@1+ (1.0,0.0) [0.0|3] ""  Vector__XXX
 SG_ PSD_Baum_Ausrichtung m3  : 54|10@1+ (0.3515625,0) [0E-7|359.6484375] "Unit_DegreOfArc"  Vector__XXX
 SG_ PSD_Steigung_2_Offset m4  : 54|7@1+ (2,0) [0|254] "Unit_Meter"  Motor_BEV
 SG_ PSD_Ges_Gesetzlich_Kategorie m2  : 56|3@1+ (1.0,0.0) [0.0|7] ""  Motor_BEV
 SG_ PSD_Sys_Quali_Tempolimits m0  : 57|3@1+ (1,0) [0|7] "Unit_None"  Vector__XXX
 SG_ PSD_Attribute_Komplett_06 m1  : 57|1@1+ (1.0,0.0) [0.0|1] ""  Motor_BEV
 SG_ PSD_Ges_Gesetzlich_Zusatz m2  : 59|2@1+ (1.0,0.0) [0.0|3] ""  Motor_BEV
 SG_ PSD_Sys_Quali_Vorfahrtsregelung m0  : 60|3@1+ (1,0) [0|7] "Unit_None"  Vector__XXX
 SG_ PSD_Ges_Verkehrszeichen_Quelle m2  : 61|2@1+ (1.0,0.0) [0.0|3] ""  Motor_BEV
 SG_ PSD_Steigung_2_Attribute_kompl m4  : 61|1@1+ (1.0,0.0) [0.0|1] ""  Motor_BEV
 SG_ PSD_Ges_Attribute_Komplett m2  : 63|1@1+ (1.0,0.0) [0.0|1] ""  Motor_BEV

BO_ 591 RDR1_Objekte_02: 64 ICAS1_Gateway
 SG_ RDR1_relevanter_Fehler : 12|1@1+ (1.0,0.0) [0.0|1] ""  Motor_BEV
 SG_ RDR1_Blindheit_erkannt : 13|1@1+ (1.0,0.0) [0.0|1] ""  Motor_BEV
 SG_ RDR1_relev_Nichtverfuegbarkeit : 14|1@1+ (1.0,0.0) [0.0|1] ""  Motor_BEV
 SG_ RDR1_Obj_01_Nummer : 16|6@1+ (1,0) [0|63] ""  Vector__XXX
 SG_ RDR1_Obj_02_Nummer : 22|6@1+ (1,0) [0|63] ""  Vector__XXX
 SG_ RDR1_Obj_03_Nummer : 28|6@1+ (1,0) [0|63] ""  Vector__XXX
 SG_ RDR1_Obj_04_Nummer : 34|6@1+ (1,0) [0|63] ""  Vector__XXX
 SG_ RDR1_Obj_05_Nummer : 40|6@1+ (1,0) [0|63] ""  Vector__XXX
 SG_ RDR1_Obj_06_Nummer : 46|6@1+ (1,0) [0|63] ""  Vector__XXX
 SG_ RDR1_Verkehrssinn : 52|2@1+ (1.0,0.0) [0.0|3] ""  Vector__XXX
 SG_ RDR1_Objekte_02_Datenalter : 54|10@1+ (0.0009765625,0) [0E-10|0.9980468750] "Unit_Secon"  Vector__XXX
 SG_ RDR1_Obj_01_dx_v : 64|12@1+ (0.0625,0) [0.0000|255.9375] "Unit_Meter"  Motor_BEV
 SG_ RDR1_Obj_01_dy_v : 76|10@1+ (0.0625,-32) [-32.0000|31.9375] "Unit_Meter"  Motor_BEV
 SG_ RDR1_Obj_01_vx_v : 86|10@1+ (0.25,-128) [-128.00|127.75] "Unit_MeterPerSecon"  Motor_BEV
 SG_ RDR1_Obj_02_dx_v : 96|12@1+ (0.0625,0) [0.0000|255.9375] "Unit_Meter"  Vector__XXX
 SG_ RDR1_Obj_02_dy_v : 108|10@1+ (0.0625,-32) [-32.0000|31.9375] "Unit_Meter"  Vector__XXX
 SG_ RDR1_Obj_02_vx_v : 118|10@1+ (0.25,-128) [-128.00|127.75] "Unit_MeterPerSecon"  Vector__XXX
 SG_ RDR1_Obj_03_dx_v : 128|12@1+ (0.0625,0) [0.0000|255.9375] "Unit_Meter"  Vector__XXX
 SG_ RDR1_Obj_03_dy_v : 140|10@1+ (0.0625,-32) [-32.0000|31.9375] "Unit_Meter"  Vector__XXX
 SG_ RDR1_Obj_03_vx_v : 150|10@1+ (0.25,-128) [-128.00|127.75] "Unit_MeterPerSecon"  Vector__XXX
 SG_ RDR1_Obj_04_dx_v : 160|12@1+ (0.0625,0) [0.0000|255.9375] "Unit_Meter"  Motor_BEV
 SG_ RDR1_Obj_04_dy_v : 172|10@1+ (0.0625,-32) [-32.0000|31.9375] "Unit_Meter"  Vector__XXX
 SG_ RDR1_Obj_04_vx_v : 182|10@1+ (0.25,-128) [-128.00|127.75] "Unit_MeterPerSecon"  Motor_BEV
 SG_ RDR1_Obj_05_dx_v : 192|12@1+ (0.0625,0) [0.0000|255.9375] "Unit_Meter"  Vector__XXX
 SG_ RDR1_Obj_05_dy_v : 204|10@1+ (0.0625,-32) [-32.0000|31.9375] "Unit_Meter"  Vector__XXX
 SG_ RDR1_Obj_05_vx_v : 214|10@1+ (0.25,-128) [-128.00|127.75] "Unit_MeterPerSecon"  Vector__XXX
 SG_ RDR1_Obj_06_dx_v : 224|12@1+ (0.0625,0) [0.0000|255.9375] "Unit_Meter"  Vector__XXX
 SG_ RDR1_Obj_06_dy_v : 236|10@1+ (0.0625,-32) [-32.0000|31.9375] "Unit_Meter"  Vector__XXX
 SG_ RDR1_Obj_06_vx_v : 246|10@1+ (0.25,-128) [-128.00|127.75] "Unit_MeterPerSecon"  Vector__XXX
 SG_ RDR1_Obj_01_ax_v : 256|8@1+ (0.125,-16) [-16.000|15.750] "Unit_MeterPerSeconSquar"  Motor_BEV
 SG_ RDR1_Obj_01_ax_StdA : 264|6@1+ (0.125,0) [0.000|7.750] "Unit_MeterPerSeconSquar"  Motor_BEV
 SG_ RDR1_Obj_01_vx_StdA : 270|7@1+ (0.03125,0) [0.00000|3.93750] "Unit_MeterPerSecon"  Motor_BEV
 SG_ RDR1_Obj_01_dx_StdA : 277|7@1+ (0.05,0) [0.00|6.30] "Unit_Meter"  Motor_BEV
 SG_ RDR1_Obj_01_dy_StdA : 284|7@1+ (0.0625,0) [0.0000|7.8750] "Unit_Meter"  Motor_BEV

BO_ 2033 Request_Airbag_Deployment: 8 ICAS1_Gateway
 SG_ Request_Airbag_Deployment : 0|64@1+ (1.0,0.0) [0.0|18446744073709551615] ""  Airbag

BO_ 2041 Response_Airbag_Deployment: 8 Airbag
 SG_ Response_Airbag_Deployment : 0|64@1+ (1.0,0.0) [0.0|18446744073709551615] ""  ICAS1_Gateway

CM_ BO_ 1601 "ab MQB mit CRC-8";
CM_ BO_ 339 "CAN-Botschaft";
CM_ BO_ 2621506048 "VDC funktionaler Request auf CANFD";

CM_ SG_ 1601 MO_Ansaugsystem "Art des Ansaugsystems des Verbrennungsmotors";
CM_ SG_ 1601 MO_Anzahl_Zyl "Zylinderzahl des Verbrennungsmotors";
CM_ SG_ 1601 MO_Anzeige_StSt_gueltig "Zeigt die Gültigkeit der neuen StSt-Anzeigesignale an, MO_Anzeige_StSt_Text und  MO_Anzeige_Symbol. Mo_Text_Motorstart 1..5 sind zu ignorieren.";
CM_ SG_ 1601 MO_Code "Motorcodierinformation Version 13 (Details siehe Anhang)";
CM_ SG_ 1601 MO_DPF_verbaut "Verbauinformation Diesel-Partikel-Filter
";
CM_ SG_ 1601 MO_Faktor_Momente_02 "Dieses Signal schaltet den Wertebereich aller Momente vom Motor, Getriebe, TSK, Bremse ... um! Die Momente besitzen somit einen variablen Wertebereich, weil sich durch den Faktor die Momente sowohl in Auflösung als auch Maximalwerten ändert.

0x0 nicht ";
CM_ SG_ 1601 MO_Getriebe_Code "Getriebecodierung des Motors";
CM_ SG_ 1601 MO_Hubraum "Hubraum des Verbrennungsmotors";
CM_ SG_ 1601 MO_Hybridfahrzeug "Anhand dieses Signals plausibilisiert die Lenkhilfe das Bit Fahrbereitschaft.

Im Projekt Cayenne PHEV (und ggf. auch VW526 PHEV) ist aus Gründen der Abwärtskompatibilität der Wert '2' zu senden.";
CM_ SG_ 1601 MO_Kraftstoffart "Primärkraftstoff zum Antrieb des Fahrzeugs";
CM_ SG_ 1601 MO_Leistung "Nennleistung des Verbrennungsmotors";
CM_ SG_ 1601 MO_OBD_Typ "Abgastyp OBD";
CM_ SG_ 1601 MO_StartStopp_Codiert "Funktion StartStopp im aktuellen Klemmenzyklus verbaut";
CM_ SG_ 1601 Motor_Code_01_CRC "Für MLB:
'Berechnung siehe Lastenheft 'Kommunikationsabsicherung für FlexRay und CAN''

Ab MQB und MLBevo:
'Berechnung siehe Lastenheft 'End-to-End Kommunikationsabsicherung''

Endwerte siehe Begleitdokument 'S-PDU Kennungsfolgen'";
CM_ SG_ 1601 TSK_Codierung "Information über den plausibilisierten Codierungszustand des Triebstrangskoordinators auf ACC oder GRA.";

CM_ SG_ 1155 MO_Powermeter_Charge_Grenze "Zeigt eine Einschränkung der Rekuperationsleistung an
";
CM_ SG_ 1155 Mo_Powermeter_Grenze "Anzeige des verfügbaren Powermeterstands im Kombi. Bei EV Unterscheidung zwischen Boost- und Dauerbereich, bei HEV für die Zustartgrenze nutzber";
CM_ SG_ 1155 MO_Powermeter_Grenze_strategisch "Zeigt eine strategische Leistungsbeschränkung des Antriebs, 
zum Beispiel kein Boost im Efficiency Modus";
CM_ SG_ 1155 MO_Powermeter_Inszenierung_aktiv "Mit Hilfe des Signals kann eine Dynamikabfahrt für den Kunden inszeniert werden. Die Inszenierung wird im Powermeter des Kombi-Instruments verortet.";
CM_ SG_ 1155 MO_Powermeter_obere_E_Grenze "Zeigt die obere Grenze für das elektrische Fahren an";
CM_ SG_ 1155 MO_Powermeter_untere_E_Grenze "Zeigt die untere Grenze für das elektrische Fahren an";
CM_ SG_ 1155 MO_Text_Aktivierung_Antrieb "Fahrerinformation zur Antriebsstrangaktivierung.";

CM_ SG_ 2527679686 MRR_HR_ASM_Data_1 "Dieses Signal wird von MRR_HR befüllt und an den Assistenzsystemmonitor ASM (Host SG: Safety Computer) gesendet.";
CM_ SG_ 2527679686 MRR_HR_ASM_Data_2 "Dieses Signal wird von MRR_HR befüllt und an den Assistenzsystemmonitor ASM (Host SG: Safety Computer) gesendet.";
CM_ SG_ 2527679686 MRR_HR_ASM_Data_3 "Dieses Signal wird von MRR_HR befüllt und an den Assistenzsystemmonitor ASM (Host SG: Safety Computer) gesendet.";
CM_ SG_ 2527679686 MRR_HR_ASM_Data_4 "Dieses Signal wird von MRR_HR befüllt und an den Assistenzsystemmonitor ASM (Host SG: Safety Computer) gesendet.";
CM_ SG_ 2527679686 MRR_HR_ASM_Data_5 "Dieses Signal wird von MRR_HR befüllt und an den Assistenzsystemmonitor ASM (Host SG: Safety Computer) gesendet.";
CM_ SG_ 2527679686 MRR_HR_ASM_Data_6 "Dieses Signal wird von MRR_HR befüllt und an den Assistenzsystemmonitor ASM (Host SG: Safety Computer) gesendet.";
CM_ SG_ 2527679686 MRR_HR_ASM_Ereignis "Dieses Signal definiert, welche Funktion und welche Art von Aktivität das Senden der Botschaft an den Assistenzsystemmonitor ASM veranlasst hat.";
CM_ SG_ 2527679686 MRR_HR_ASM_Zeitstempel "Dieses Signal ermöglicht die zeitliche Zuordnung der von mehreren Funktionen auf dem MRR an den Assistenzsystemmonitor ASM gesendeten Statusbot-schaften.";

CM_ SG_ 339 MO_ErwGrenzen_Anf "temporäre Anforderung erweiterter Leistungsgrenzen
0 = normaler Betrieb angefordert
1 = erweiterte Leistungsgrenzen angefordert
BMS und EMS liefern ggf. erweiterte Leistungsgrenzen, um VKM-Start auch unter schwierigen Bedingungen gewährleisten zu könne";
CM_ SG_ 339 MO_Fehler_Notentladung_Anf "Aufforderung zur schnellstmöglichen Entladeung des HV-Zwischenkreises aufgrund Crash-Erkennung / Abriss Pilotlinie";
CM_ SG_ 339 MO_HVEM_Eskalation "Eskalationsbit, mit diesem zusammen darf MO_HVEM_MaxLeistung < der minimal angeforderten Leistung sein und ist durch das HVEM durch Ergreifung aller Eskalationsmaßnahmen umzusetzen (Bei neg. Ladebilanz z.B. im Leerlauf nötig, um die HVBatt vor Entladung e";
CM_ SG_ 339 MO_HVEM_MaxLeistung "Maximal zulässige Leistung, die das HVEM einzustellen hat. 
Ohne Eskalationsbit ist diese Anforderung >= der Minimal benötigten Leistung des HVEM

Hinweis: Ehemaliger Fehlerwert 0x1FF wird senderseitig nicht unterstützt. Diesen Wert aus Kompatibilitäts";
CM_ SG_ 339 MO_HVK_AntriebFehlerstatus "aktueller Fehlerstatus des Antriebs
0: Komponente IO (keine HVK relevanter Fehler)
1 - 5: reserve
6: Keine Komponentenfunktion (Aus)
7: Init";
CM_ SG_ 339 MO_HVK_AntriebZustand "Aktueller Zustand des Antriebs:
0 : Antrieb_AUS               
1 : Antrieb_Startphase        
2 : E-Fahren                  
3 : Hybrid-Fahren             
4 : reserve                   
5 : reserve                   
6 : Keine_Komponentenfunktion ";
CM_ SG_ 339 MO_HVK_EmFehlerstatus "aktueller Fehlerstatus des elektrischen Antriebes (E-Maschine und PWR)

0: Komponente IO (keine HVK relevanter Fehler)
1: Eingeschränkter Betrieb wg. Teilbetrieb
2: reserve
3: Eingeschr_KompFkt_Interlock
4 - 5: reserve
6: Keine Komponentenfunktion ";
CM_ SG_ 339 MO_HVK_EmIstzustand "Aktueller Istzustand der Elm_State
0 : HvOff              
1 : HvStbyReq          
2 : HvStbyOk         
3 : HvBattOnReq        
4 : HvBattOnOk       
10 : HvOnIdle          
18 : HvOnDrvReq        
19 : HvOnDrvOk       
20 : HvOnDrvRdy          ";
CM_ SG_ 339 MO_MVK_AntriebFehlerstatus "aktueller Fehlerstatus des Antriebs
0: Komponente IO (keine MVK relevanter Fehler)
1 - 5: reserve
6: Keine Komponentenfunktion (Aus)
7: Init";
CM_ SG_ 339 MO_MVK_AntriebZustand "Aktueller Zustand des Antriebs:
0 : Antrieb_AUS               
1 : Antrieb_Startphase        
2 : FreilaufMotorAus                  
3 : reserve             
4 : reserve                   
5 : reserve                   
6 : Keine_Komponentenfunktio";
CM_ SG_ 339 MO_MVK_Bordnetz_Anf "Explizite Anforderung des Motors zur Aktivierung bzw. Aufrechterhaltung des Mittelvolt-Bordnetzes für die Ausführung von Motorfunktionen";
CM_ SG_ 339 MO_MVK_EmFehlerstatus "aktueller Fehlerstatus der elektrischen Maschine (RSG)

0: Komponente IO (keine MVK relevanter Fehler)
1: Eingeschränkter Betrieb wg. Teilbetrieb
2: reserve
3 - 5: reserve
6: Keine Komponentenfunktion (Aus)
7: Init";
CM_ SG_ 339 MO_MVK_EmIstzustand "Aktueller Istzustand der Elm_State
0 : MvOff              
1 : MvStbyReq          
2 : MvStbyOk         
3 : MvBattOnReq        
4 : MvBattOnOk       
10 : MvOnIdle          
18 : MvOnDrvReq        
19 : MvOnDrvOk       
20 : MvOnDrv           
";
CM_ SG_ 339 MSG_HYB_30_BZ "BZ für die Botschaft MSG_HYB_30";
CM_ SG_ 339 MSG_HYB_30_CRC "CRC für die Botschaft MSG_HYB_30";

CM_ SG_ 2600468501 NM_Airbag_01_CAB_V10 "CAB = Clusteraktivbits (V10)";
CM_ SG_ 2600468501 NM_Airbag_01_Car_Wakeup "Car Wakeup (Gateway wertet aus)
MQB: Klemme 15 ist unplausibel (Kl.-15 HW ist ein, Kl.-15 SW aus) und muss dem Fahrer angezeigt werden (dauerhaft)";
CM_ SG_ 2600468501 NM_Airbag_01_CBV_AWB "Das Signal ist zu setzen, wenn das SG aktiv den Bus geweckt hat";
CM_ SG_ 2600468501 NM_Airbag_01_CBV_CRI "Das Signal ist dauerhaft gesetzt, wenn das NM-Layout dem neuen NM-Layout für Teilnetzbetrieb entspricht";
CM_ SG_ 2600468501 NM_Airbag_01_NM_aktiv_Diagnose "Diagnose befindet sich nach VW80124 in einer NonDefaultDiagnostic-Session, z.B. ExtendedDiagnostic-Session";
CM_ SG_ 2600468501 NM_Airbag_01_NM_aktiv_KL15 "Steuergerät hat KL15-EIN erkannt";
CM_ SG_ 2600468501 NM_Airbag_01_NM_aktiv_Tmin "Mindestaktivzeit ist noch nicht abgelaufen (bei jedem Weckereignis wird die Mindestaktivzeit neu gestartet)";
CM_ SG_ 2600468501 NM_Airbag_01_NM_State "1 = Zustand Repeat Message (<-- Bus-Sleep Mode)
2 = Zustand Repeat Message (<-- Prepare Bus-Sleep Mode)
4 = Zustand Normal Operation (<-- Repeat Message)
8 = Zustand Normal Operation (<-- Ready Sleep)";
CM_ SG_ 2600468501 NM_Airbag_01_UDS_CC "Funktionseinschränkung aufgrund aktivem UDS-Communication Control; siehe VW80124";

CM_ SG_ 2600468604 NM_EMotor_01_CAB_V10 "CAB = Clusteraktivbits (V10)";
CM_ SG_ 2600468604 NM_EMotor_01_Car_Wakeup "Car Wakeup (Gateway wertet aus)
";
CM_ SG_ 2600468604 NM_EMotor_01_CBV_AWB "Das Signal ist zu setzen, wenn das SG aktiv den Bus geweckt hat";
CM_ SG_ 2600468604 NM_EMotor_01_CBV_CRI "Das Signal ist dauerhaft gesetzt, wenn das NM-Layout dem neuen NM-Layout für Teilnetzbetrieb entspricht";
CM_ SG_ 2600468604 NM_EMotor_01_keine_HV_Entl "Dieser Bus wird wachgehalten, weil keine HV-Entladung möglich";
CM_ SG_ 2600468604 NM_EMotor_01_NM_aktiv_Diagnose "Diagnose befindet sich nach VW80124 in einer NonDefaultDiagnostic-Session, z.B. ExtendedDiagnostic-Session";
CM_ SG_ 2600468604 NM_EMotor_01_NM_aktiv_KL15 "Steuergerät hat KL15-EIN erkannt";
CM_ SG_ 2600468604 NM_EMotor_01_NM_aktiv_Tmin "Mindestaktivzeit ist noch nicht abgelaufen (bei jedem Weckereignis wird die Mindestaktivzeit neu gestartet)";
CM_ SG_ 2600468604 NM_EMotor_01_NM_State "1 = Zustand Repeat Message (<-- Bus-Sleep Mode)
2 = Zustand Repeat Message (<-- Prepare Bus-Sleep Mode)
4 = Zustand Normal Operation (<-- Repeat Message)
8 = Zustand Normal Operation (<-- Ready Sleep)";
CM_ SG_ 2600468604 NM_EMotor_01_UDS_CC "Funktionseinschränkung aufgrund aktivem UDS-Communication Control; siehe VW80124";

CM_ SG_ 2600468496 NM_Gateway_CAB_V10 "CAB = Clusteraktivbits (V10)";
CM_ SG_ 2600468496 NM_Gateway_Car_Wakeup "Car Wakeup (Subbusmaster wertet aus)

MQB: 
-Diagnose- oder Komponentenschutzmaster-Funktion weckt den schlafenden Subbus (z.B. MOST)

MEB:
- Diagnose aktiv -aktive Diagnosekommunikation am OBD-Stecker";
CM_ SG_ 2600468496 NM_Gateway_CBV_AWB "Das Signal ist zu setzen, wenn das SG aktiv den Bus geweckt hat";
CM_ SG_ 2600468496 NM_Gateway_CBV_CRI "Das Signal ist dauerhaft gesetzt, wenn das NM-Layout dem neuen NM-Layout für Teilnetzbetrieb entspricht";
CM_ SG_ 2600468496 NM_Gateway_NM_aktiv_Diagnose "Diagnose befindet sich nach VW80124 in einer NonDefaultDiagnostic-Session, z.B. ExtendedDiagnostic-Session";
CM_ SG_ 2600468496 NM_Gateway_NM_aktiv_KL15 "Steuergerät hat KL15-EIN erkannt";
CM_ SG_ 2600468496 NM_Gateway_NM_aktiv_Tmin "Mindestaktivzeit ist noch nicht abgelaufen (bei jedem Weckereignis wird die Mindestaktivzeit neu gestartet)";
CM_ SG_ 2600468496 NM_Gateway_NM_State "1 = Zustand Repeat Message (<-- Bus-Sleep Mode)
2 = Zustand Repeat Message (<-- Prepare Bus-Sleep Mode)
4 = Zustand Normal Operation (<-- Repeat Message)
8 = Zustand Normal Operation (<-- Ready Sleep)
16 = Zustand Repeat Message (<-- Ready Sleep)
32 ";
CM_ SG_ 2600468496 NM_Gateway_UDS_CC "Funktionseinschränkung aufgrund aktivem UDS-Communication Control; siehe VW80124";

CM_ SG_ 2600468664 NM_LE2_CAB_V10 "CAB = Clusteraktivbits (V10)";
CM_ SG_ 2600468664 NM_LE2_Car_Wakeup "Car Wakeup (Gateway wertet aus)";
CM_ SG_ 2600468664 NM_LE2_CBV_AWB "Das Signal ist zu setzen, wenn das SG aktiv den Bus geweckt hat";
CM_ SG_ 2600468664 NM_LE2_CBV_CRI "Das Signal ist dauerhaft gesetzt, wenn das NM-Layout dem neuen NM-Layout für Teilnetzbetrieb entspricht";
CM_ SG_ 2600468664 NM_LE2_keine_HV_entl "Dieser Bus wird wachgehalten, weil keine HV-Entladung möglich";
CM_ SG_ 2600468664 NM_LE2_NM_aktiv_Diagnose "Diagnose befindet sich nach VW80124 in einer NonDefaultDiagnostic-Session, z.B. ExtendedDiagnostic-Session";
CM_ SG_ 2600468664 NM_LE2_NM_aktiv_KL15 "Steuergerät hat KL15-EIN erkannt";
CM_ SG_ 2600468664 NM_LE2_NM_aktiv_Tmin "Mindestaktivzeit ist noch nicht abgelaufen (bei jedem Weckereignis wird die Mindestaktivzeit neu gestartet)";
CM_ SG_ 2600468664 NM_LE2_NM_State "1 = Zustand Repeat Message (<-- Bus-Sleep Mode)
2 = Zustand Repeat Message (<-- Prepare Bus-Sleep Mode)
4 = Zustand Normal Operation (<-- Repeat Message)
8 = Zustand Normal Operation (<-- Ready Sleep)
16 = Zustand Repeat Message (<-- Ready Sleep)
32 ";
CM_ SG_ 2600468664 NM_LE2_UDS_CC "Funktionseinschränkung aufgrund aktivem UDS-Communication Control; siehe VW80124";

CM_ SG_ 2600468598 NM_MO_01_CAB_V10 "CAB = Clusteraktivbits (V10)";
CM_ SG_ 2600468598 NM_MO_01_Car_Wakeup "Car Wakeup (Gateway wertet aus)
MQB:
- Betanken (Drucktank): gesetzt nur zum busübergreifenden Wachhalten (des BCM für Hybrid)
- Standklimatisierung (Vorhalt)
- Hybrid-Manager deaktiviert alle Hochvolt-Verbraucher für stromloses Öffnen der Batteriesch";
CM_ SG_ 2600468598 NM_MO_01_CBV_AWB "Das Signal ist zu setzen, wenn das SG aktiv den Bus geweckt hat";
CM_ SG_ 2600468598 NM_MO_01_CBV_CRI "Das Signal ist dauerhaft gesetzt, wenn das NM-Layout dem neuen NM-Layout für Teilnetzbetrieb entspricht";
CM_ SG_ 2600468598 NM_MO_01_NM_aktiv_Betankung "Betankung Drucktank";
CM_ SG_ 2600468598 NM_MO_01_NM_aktiv_Diagnose "Diagnose befindet sich nach VW80124 in einer NonDefaultDiagnostic-Session, z.B. ExtendedDiagnostic-Session";
CM_ SG_ 2600468598 NM_MO_01_NM_aktiv_Hochvolt "Hochvolt aktiv";
CM_ SG_ 2600468598 NM_MO_01_NM_aktiv_HV_Abschaltung "Hybrid-Manager deaktiviert alle Hochvolt-Verbraucher für stromloses Öffnen der Batterieschütze";
CM_ SG_ 2600468598 NM_MO_01_NM_aktiv_KL15 "Steuergerät hat KL15-EIN erkannt";
CM_ SG_ 2600468598 NM_MO_01_NM_aktiv_Tmin "Mindestaktivzeit ist noch nicht abgelaufen (bei jedem Weckereignis wird die Mindestaktivzeit neu gestartet)";
CM_ SG_ 2600468598 NM_MO_01_NM_aktiv_Waehlhebel "Der Waehlhebel MQB setzt wegen Forderung der Funktion 'Verlassenswarnung' NM-High um. Beim E-Fzg. ist der Master des Waehlhebels das Motor-SG.
Daher ist ein neuer Nachlaufgrund des Motors erforderlich, wenn die Wählhebelposition gefordert wird.";
CM_ SG_ 2600468598 NM_MO_01_NM_State "1 = Zustand Repeat Message (<-- Bus-Sleep Mode)
2 = Zustand Repeat Message (<-- Prepare Bus-Sleep Mode)
4 = Zustand Normal Operation (<-- Repeat Message)
8 = Zustand Normal Operation (<-- Ready Sleep)
16 = Zustand Repeat Message (<-- Ready Sleep)
32 ";
CM_ SG_ 2600468598 NM_MO_01_UDS_CC "Funktionseinschränkung aufgrund aktivem UDS-Communication Control; siehe VW80124";

CM_ SG_ 2600468733 NM_Waehlhebel_CAB_V10 "CAB = Clusteraktivbits (V10)";
CM_ SG_ 2600468733 NM_Waehlhebel_Car_Wakeup "Car Wakeup (Gateway wertet aus)

MLBevo: Fahrerwunsch_P";
CM_ SG_ 2600468733 NM_Waehlhebel_CBV_AWB "Das Signal ist zu setzen, wenn das SG aktiv den Bus geweckt hat";
CM_ SG_ 2600468733 NM_Waehlhebel_CBV_CRI "Das Signal ist dauerhaft gesetzt, wenn das NM-Layout dem neuen NM-Layout für Teilnetzbetrieb entspricht";
CM_ SG_ 2600468733 NM_Waehlhebel_NM_aktiv_Diagnose "Diagnose befindet sich nach VW80124 in einer NonDefaultDiagnostic-Session, z.B. ExtendedDiagnostic-Session";
CM_ SG_ 2600468733 NM_Waehlhebel_NM_aktiv_KL15 "Steuergerät hat KL15-EIN erkannt";
CM_ SG_ 2600468733 NM_Waehlhebel_NM_aktiv_Tmin "Mindestaktivzeit ist noch nicht abgelaufen (bei jedem Weckereignis wird die Mindestaktivzeit neu gestartet)";
CM_ SG_ 2600468733 NM_Waehlhebel_NM_State "1 = Zustand Repeat Message (<-- Bus-Sleep Mode)
2 = Zustand Repeat Message (<-- Prepare Bus-Sleep Mode)
4 = Zustand Normal Operation (<-- Repeat Message)
8 = Zustand Normal Operation (<-- Ready Sleep)";
CM_ SG_ 2600468733 NM_Waehlhebel_UDS_CC "Funktionseinschränkung aufgrund aktivem UDS-Communication Control; siehe VW80124";

CM_ SG_ 2621440533 OBDC_Airbag_01_Req_FD_Data "TP-Kanal für den Onboard Datensammler";

CM_ SG_ 2621571605 OBDC_Airbag_01_Resp_FD_Data "TP-Kanal für den Onboard Datensammler";

CM_ SG_ 2621506048 OBDC_Funktion_Req_All_FD_Data "VDC funktionaler Request auf CANFD";

CM_ SG_ 2564502513 OBDx_allOBD_Req_Data "29bit OBD";

CM_ SG_ 2564425457 OBDx_LE1_Req_Data "29bit OBD";

CM_ SG_ 2564485382 OBDx_LE1_Resp_Data "29bit OBD";

CM_ SG_ 2564425713 OBDx_LE2_Req_Data "29bit OBD";

CM_ SG_ 2564485383 OBDx_LE2_Resp_Data "29bit OBD";

CM_ SG_ 2564424177 OBDx_MO_01_Req_Data "29bit OBD Diagnose";

CM_ SG_ 2564485377 OBDx_MO_01_Resp_Data "29bit OBD Diagnose";

CM_ SG_ 627 OCC_01_BZ "4bit Botschaftszähler, wird mit jeder Sendebotschaft inkrementiert";
CM_ SG_ 627 OCC_01_CRC "Für MLB:
Berechnung siehe Lastenheft 'Kommunikationsabsicherung für FlexRay und CAN'
Ab MQB und MLBevo:
Berechnung siehe Lastenheft 'End-to-End Kommunikationsabsicherung'

Endwerte siehe Begleitdokument 'S-PDU Kennungsfolgen'";
CM_ SG_ 627 OCC_CC_Fehlerstatus_DC_GBT "Gibt den Fehlerstatus des DC-Steckers für China aus";
CM_ SG_ 627 OCC_CC_Latchstatus_DC_GBT "Gibt den Latchstatus des DC-Steckers für China aus";
CM_ SG_ 627 OCC_CC_Status_DC_GBT "Gibt den Status des DC-Steckers für China aus";
CM_ SG_ 627 OCC_CP_Status_A "Status A des Control Pilots";
CM_ SG_ 627 OCC_CP_Status_B "Status B des Control Pilots";
CM_ SG_ 627 OCC_DC_IstStrom "aktueller Iststrom des OCC";
CM_ SG_ 627 OCC_I_istAC_Netz_L1 "aktueller AC-Iststrom am Eingangskreis Phase 1 des OCC";
CM_ SG_ 627 OCC_I_istAC_Netz_L2 "aktueller AC-Iststrom am Eingangskreis Phase 2 des OCC";
CM_ SG_ 627 OCC_I_istAC_Netz_L3 "aktueller AC-Iststrom am Eingangskreis Phase 3 des OCC";
CM_ SG_ 627 OCC_IstModus "aktueller Funktionszustand des OCC";
CM_ SG_ 627 OCC_IstSpannung_HV "aktuelle DC-Ausgangsspannung des OCC";
CM_ SG_ 627 OCC_PP_Latchstatus_A "Latchstatus Plug Present A";
CM_ SG_ 627 OCC_PP_Latchstatus_B "Latchstatus Plug Present B";
CM_ SG_ 627 OCC_PP_Status_A "Status Plug Present A";
CM_ SG_ 627 OCC_PP_Status_B "Status Plug Present B";
CM_ SG_ 627 OCC_Status_EoHVL "Erkennung einer offenen HV-Leitung (EoHVL), bewertet anhand einer Spannungsgrenze";
CM_ SG_ 627 OCC_Status_Spgfreiheit "Status der Spannungsfreiheit für den Onboard Charge Client";
CM_ SG_ 627 OCC_Stecker_Status "Stellt den Status des Ladesteckers hinsichtlich Präsenz zur Verfügung";
CM_ SG_ 627 OCC_Temp_Sensor_Fehlerstatus_AC "Fehlerstatus Temperatursensor Ladedose beim AC-Laden";
CM_ SG_ 627 OCC_Temp_Sensor_Fehlerstatus_DC "Fehlerstatus Temperatursensor Ladedose beim DC-Laden";
CM_ SG_ 627 OCC_Temp_Sensor_Status "Temperatur an den Temp-Sensoren Ladedose für das DC-Laden.";

CM_ SG_ 2463978709 OCC_CP_Fehlerstatus_A "Fehlerstatus Control Pilot A";
CM_ SG_ 2463978709 OCC_CP_Fehlerstatus_B "Fehlerstatus Control Pilot B";
CM_ SG_ 2463978709 OCC_CP_Frequenz_A "Frequenz Control Pilot A";
CM_ SG_ 2463978709 OCC_CP_Frequenz_B "Frequenz Control Pilot B";
CM_ SG_ 2463978709 OCC_CP_Spannung_A "Spannung Control Pilot A";
CM_ SG_ 2463978709 OCC_CP_Spannung_B "Spannung Control Pilot B";
CM_ SG_ 2463978709 OCC_CP_Tastgrad_A "Tastgrad Control Pilot A";
CM_ SG_ 2463978709 OCC_CP_Tastgrad_B "Tastgrad Control Pilot B";
CM_ SG_ 2463978709 OCC_DC_MaxStrom "maximaler Strom den das OCC bei der aktuellen Spannungslage und des vorgegebenen AC-Aufnahmenstrom stellen kann";
CM_ SG_ 2463978709 OCC_Derating_Temperatur "Derating-Status aufgrund von Temperaturbegrenzungen des OCC";
CM_ SG_ 2463978709 OCC_Fehlerzustand "zeigt an, ob im OCC ein Fehler anliegt";
CM_ SG_ 2463978709 OCC_Ist_Wirkungsgrad "aktueller Wirkungsgrad des OCC";
CM_ SG_ 2463978709 OCC_Kuehltemperatur "Istwert der OCC-Kühlkanaltemperatur";
CM_ SG_ 2463978709 OCC_Ladest_Entriegelungs_Verbot "Verbot zur Ladestecker Entriegelung";
CM_ SG_ 2463978709 OCC_Netzfrequenz_EVU "aktuelle AC-Netzfrequenz im Eingangskreis des OCC";
CM_ SG_ 2463978709 OCC_PP_Fehlerstatus_A "Fehlerstatus Plug Present A";
CM_ SG_ 2463978709 OCC_PP_Fehlerstatus_B "Fehlerstatus Plug Present B";
CM_ SG_ 2463978709 OCC_PP_Max_Strom_A "Gibt die maximale Belastbarkeit des angeschlossenen Ladekabels an";
CM_ SG_ 2463978709 OCC_PP_Max_Strom_B "Gibt die maximale Belastbarkeit des angeschlossenen Ladekabels an";
CM_ SG_ 2463978709 OCC_RtmWarnLadeKommunikation "RTM Warning of charging communction fault";
CM_ SG_ 2463978709 OCC_StatusVerEntriegelungAktor_A "gibt den Status der Ansteuerung des Verriegelungsaktors im Fahrzeug an";
CM_ SG_ 2463978709 OCC_StatusVerEntriegelungAktor_B "gibt den Status der Ansteuerung des Verriegelungsaktors im Fahrzeug an";
CM_ SG_ 2463978709 OCC_SteckerEntriegelung_Verbot_A "Verbot zur Ladesteckerentriegelung";
CM_ SG_ 2463978709 OCC_SteckerEntriegelung_Verbot_B "Verbot zur Ladesteckerentriegelung";
CM_ SG_ 2463978709 OCC_Temp_Ladedose_A_AC "aktuelle Temperatur der AC-Ladedose";
CM_ SG_ 2463978709 OCC_Temp_Ladedose_A_DC_minus "aktuelle Temperatur des Pins DC (-) der Ladedose A";
CM_ SG_ 2463978709 OCC_Temp_Ladedose_A_DC_plus "aktuelle Temperatur des Pins DC (+) der Ladedose A";
CM_ SG_ 2463978709 OCC_U_istAC_Netz_L1 "aktuelle AC-Istspannung am Eingangskreis Phase 1 des OCC";
CM_ SG_ 2463978709 OCC_U_istAC_Netz_L2 "aktuelle AC-Istspannung am Eingangskreis Phase 2 des OCC";
CM_ SG_ 2463978709 OCC_U_istAC_Netz_L3 "aktuelle AC-Istspannung am Eingangskreis Phase 3 des OCC";
CM_ SG_ 2463978709 OCC_Verriegelung_Status_A "Zeigt den Status des Verriegelungsaktors der Ladedose A an";
CM_ SG_ 2463978709 OCC_Verriegelung_Status_B "Zeigt den Status des Verriegelungsaktors der Ladedose  an B";
CM_ SG_ 2463978709 OCC_Warnzustand "Sammelwarnung OCC";

CM_ SG_ 2589283656 ORU_EM_Anfrage_Flashdauer "Anfrage an das Energiemanagement, ob ein konkretes Online Remote Update durchgeführt werden kann - Flashdauer in 10s.";
CM_ SG_ 2589283656 ORU_EM_Anfrage_freigegebeneNetze "Meldung der während eines konkreten Online Remote Updates freigegebenen Netze (12V, 48V, HV)";
CM_ SG_ 2589283656 ORU_EM_Anfrage_Stromaufnahme "Meldung der voraussichtlichen durchschnittlichen Stromaufnahme eines konkreten Online Remote Updates an das NVEM";
CM_ SG_ 2589283656 ORU_Status "Broadcast des Status der Konzernfunktion Online Remote Update";
CM_ SG_ 2589283656 ORU_Warnung "Wenn durch Störungen der Funktion Online Remote Update nicht sichergestellt ist, dass vor Kunde keine Funktionseinschränkungen auftreten, muss der Benutzer des Fahrzeugs entsprechend gewarnt werden.";

CM_ SG_ 2527679741 PAO_OFF_Status "Istwert für LED 'OFF' in Anzeige Passenger Airbag On/Off";
CM_ SG_ 2527679741 PAO_ON_Status "Istwert für LED 'ON' in Anzeige Passenger Airbag On/Off";
CM_ SG_ 2527679741 PAO_Status_01_BZ "4bit Botschaftszähler, wird mit jeder Sendebotschaft inkrementiert";
CM_ SG_ 2527679741 PAO_Status_01_CRC "Für MLB:
Berechnung siehe Lastenheft 'Kommunikationsabsicherung für FlexRay und CAN'
Ab MQB und MLBevo:
Berechnung siehe Lastenheft 'End-to-End Kommunikationsabsicherung'

Endwerte siehe Begleitdokument 'S-PDU Kennungsfolgen'";
CM_ SG_ 2527679741 PAO_Status_Reserve_Byte3 "Zweck: Befüllen der reservierten Bitpositionen mit 0 (wg. LIN-Teilnehmer)";

CM_ SG_ 518 IPA_TPA_Abbruch "Signalisierung eines durch IPA erkannten Abbruchs mit Angabe des Grundes";
CM_ SG_ 518 IPA_TPA_Fehler "Signalisierung eines durch IPA erkannten Fehlers mit Angabe der Fehlerart";
CM_ SG_ 518 IPA_TPA_Remote "Status hinsichtlich Umschaltung auf fernbedienten Parkvorgang";
CM_ SG_ 518 IPA_TPA_Remote_Anf "Anforderung für fernbedienten Parkvorgang";
CM_ SG_ 518 IPA_TPA_Status "Status der Funktion IPA gegenüber der Funktion TPA";
CM_ SG_ 518 Parken_aktives_System "Das Signal zeigt an, welches der Parksysteme auf dem zFAS gerade aktiv ist.";
CM_ SG_ 518 Parken_Anforderung_HMS "Anforderung der Dienste des HMS durch die Parkplattform";
CM_ SG_ 518 Parken_Anhalteweg_Anf "Zeigt eine Anhalteweg Anforderung an";
CM_ SG_ 518 Parken_beibehalten "Fordert das Parken beim HMS an";
CM_ SG_ 518 Parken_BKD_Anf "Anforderung der Systemtotzeitoptimierung ans VZM";
CM_ SG_ 518 Parken_Blinker_li_Anf "Anforderung seitens Parkens für 'Links blinken'";
CM_ SG_ 518 Parken_Blinker_re_Anf "Anforderung seitens Parken für 'Rechts blinken'";
CM_ SG_ 518 Parken_erhoehtes_Moment "Anforderung einer spezifizierten Motormomenten-Rampe seitens IPA/PiloPa für das Überfahren einer Schwelle oder eines Bordsteins.";
CM_ SG_ 518 Parken_Fahrstufenwunsch "Fahrstufenwunsch von IPAe/RPAe an das Getriebe";
CM_ SG_ 518 Parken_max_Beschleunigung "Maximale zulässige Beschleunigung der Parkfunktion";
CM_ SG_ 518 Parken_max_Geschwindigkeit "Maximale zulässige Geschwindigkeit der Parkfunktion";
CM_ SG_ 518 Parken_Notstopp_Anf "Anforderung Notstopp der Parkplattform";
CM_ SG_ 518 Parken_Prefill_Anf "Anforderung Prefill am VZM";
CM_ SG_ 518 Parken_QFK_AnfStat "Statusinformationen des Anforderers";
CM_ SG_ 518 Parken_QFK_Art1 "Auswahlsignal für Parken_QFK_Signal1";
CM_ SG_ 518 Parken_QFK_Art2 "Auswahlsignal für Parken_QFK_Signal2";
CM_ SG_ 518 Parken_QFK_KruemmSoll "Krümmungsanforderung";
CM_ SG_ 518 Parken_QFK_KruemmSoll_VZ "Vorzeichen für die Krümmungsanforderung";
CM_ SG_ 518 Parken_QFK_Signal1 "Inhalt PLA_QFK_Signal1 wird durch das Signal PLA_QFK_Art1 gesteuert.
Nähere Informationen im LAH Querführungskoordinator.";
CM_ SG_ 518 Parken_QFK_Signal2 "Inhalt Parken_QFK_Signal2 wird durch das Signal Parken_QFK_Art2 gesteuert.
Nähere Informationen im LAH Querführungskoordinator.";
CM_ SG_ 518 Parken_QFK_Spuerb "Spürbarkeitsanforderung. Legt fest, mit welchem Handmoment die angeforderte Krümmung überlenkt werden muss.";
CM_ SG_ 518 Parken_Soll_Anhalteweg_Anf "Anforderung des Soll Anhalteweges der PPF beim VZM";
CM_ SG_ 518 Parken_Sollbeschleunigung "Anforderung einer Parkenfunktion an den TSK, das Fahrzeug zu beschleunigen.";
CM_ SG_ 518 Parken_Status_IPA_TSK "Statusinformation vom IPA für Handshakemechanismus mit TSK";
CM_ SG_ 518 Parken_Verz_Anf "Zeigt die die angeforderte Verzögerung an";
CM_ SG_ 518 Parken_Verz_Anf_ASIL "Angabe des ASIL Levels der aktuell aktiven Funtkion auf der Parkplattform";
CM_ SG_ 518 Parken_Warnruck_Anf "Signal zur Anforderung Warnruck beim VZM";
CM_ SG_ 518 Parken_Warnruckeln_Anf "Anforderung Warnruckeln beim VZM";

CM_ SG_ 2527679685 PDC_ASM_Data_1 "Dieses Signal wird vom PDC SG befüllt und an den Assistenzsystemmonitor ASM gesendet.";
CM_ SG_ 2527679685 PDC_ASM_Data_2 "Dieses Signal wird vom PDC SG befüllt und an den Assistenzsystemmonitor ASM gesendet.";
CM_ SG_ 2527679685 PDC_ASM_Data_3 "Dieses Signal wird vom PDC SG befüllt und an den Assistenzsystemmonitor ASM gesendet.";
CM_ SG_ 2527679685 PDC_ASM_Data_4 "Dieses Signal wird vom PDC SG befüllt und an den Assistenzsystemmonitor ASM gesendet.";
CM_ SG_ 2527679685 PDC_ASM_Data_5 "Dieses Signal wird vom PDC SG befüllt und an den Assistenzsystemmonitor ASM gesendet.";
CM_ SG_ 2527679685 PDC_ASM_Data_6 "Dieses Signal wird vom PDC SG befüllt und an den Assistenzsystemmonitor ASM gesendet.";
CM_ SG_ 2527679685 PDC_ASM_Ereignis "Dieses Signal definiert, welche Funktion und welche Art von Aktivität das Senden der Botschaft an den Assistenzsystemmonitor ASM veranlasst hat.";
CM_ SG_ 2527679685 PDC_ASM_Zeitstempel "Dieses Signal ermöglicht die zeitliche Zuordnung der von PDC an den Assistenzsystemmonitor ASM gesendeten Statusbotschaften.";

CM_ SG_ 319 PreCrash_Anforderung_AFR "Anforderungen der Funktion PrecrashSeite an Fahrwerksregelung";
CM_ SG_ 319 PreCrash_BFS_KSV_verfahren "Ansteuerung der Kopfstuetze Beifahrerseite durch die Funktion PreCrash

Signalwert 0x09 für vereinfachte Ansteuerung mit Logik im Sitz-SG (MQB37W)";
CM_ SG_ 319 PreCrash_BFS_Laengsverstellung "Ansteuerung der Laengsverstellung des Beifahrersitzes durch die PreCrash-Funktionen";
CM_ SG_ 319 PreCrash_BFS_Pneumatik_ansteuern "Ansteuerung des Beifahrersitzes durch die PreCrash-Funktionen";
CM_ SG_ 319 PreCrash_BFS_Sitzlehne_verfahren "Ansteuerung des Beifahrersitzes durch die PreCrash-Funktionen

Wert 0x06 und 0x07 für vereinfachte Ansteuerung Sitzlehne";
CM_ SG_ 319 PreCrash_Blinken "Safety Computer übermittelt Blinkverhalten bei einer PreCrash-Auslösung an den BCM2";
CM_ SG_ 319 PreCrash_Charisma_FahrPr "Aktuell eingestelltes Fahrprogramm der Funktion PreCrash";
CM_ SG_ 319 PreCrash_Charisma_Status "Verfügbarkeit der Funktion PreCrash für die Ansteuerung durch den Charisma_Koordinator";
CM_ SG_ 319 PreCrash_Fenster_schliessen "Anforderung Seitenscheiben schließen durch die Funktion PreCrash";
CM_ SG_ 319 PreCrash_Fo_KSV_verfahren "Ansteuerung der Kopfstuetzen im Fond durch die PreCrash-Funktionen";
CM_ SG_ 319 PreCrash_Fo_Pneumatik_ansteuern "Ansteuerung der Fondsitze durch die PreCrash-Funktionen";
CM_ SG_ 319 PreCrash_Fo_Sitzlehne_verfahren "Ansteuerung des Fondsitzes durch die PreCrash-Funktionen";
CM_ SG_ 319 PreCrash_FS_KSV_verfahren "Ansteuerung der Kopfstuetze Fahrerseite durch die PreCrash-Funktionen

Signalwert 0x09 für vereinfachte Ansteuerung mit Logik im Sitz-SG (MQB37W)";
CM_ SG_ 319 PreCrash_FS_Laengsverstellung "Ansteuerung der Laengsverstellung des Fahrersitzes durch die PreCrash-Funktionen";
CM_ SG_ 319 PreCrash_FS_Pneumatik_ansteuern "Ansteuerung des Fahrersitzes durch die PreCrash-Funktionen";
CM_ SG_ 319 PreCrash_FS_Sitzlehne_verfahren "Ansteuerung des Fahrersitzes durch die PreCrash-Funktionen

Wert 0x06 und 0x07 für vereinfachte Ansteuerung Sitzlehne";
CM_ SG_ 319 PreCrash_Schiebedach_schliessen "Anforderung Schiebedach schließen durch die Funktion PreCrash";
CM_ SG_ 319 PreCrash_Tueren_Verriegeln "Anforderung Türen Verriegeln durch die Funktion PreCrash";
CM_ SG_ 319 SC_PreCrash_LED "Ansteuerung LED-Leiste im Kombi durch SC";
CM_ SG_ 319 SC_PreCrash_Texte "Safety Computer übermittelt Systemstatus der PreCrash Funktionen an Kombi";
CM_ SG_ 319 SC_PreCrash_Warnung "Safety Computer übermittelt Warnung der PreCrash Funktionen an Kombi";
CM_ SG_ 319 SC_PreSense_FCWP "Mitteilung an das NightVision, auf welche Art von Objekt eine Warnung angefordert wird";

CM_ SG_ 1122 PSD_Abzweigerichtung "Richtung, in der die Abzweigung von der Hauptroute abzweigt
";
CM_ SG_ 1122 PSD_Abzweigewinkel "Winkel, unter dem die Abzweigung von der Hauptroute abzweigt.
";
CM_ SG_ 1122 PSD_ADAS_Qualitaet "ADAS Qualtität des Streckensegments.";
CM_ SG_ 1122 PSD_Anfangskruemmung "Startkrümmung der Klothoide des übermittelten abzweigenden Streckensegments. 
1/(1+0.155 * x^2) {1/m}'
";
CM_ SG_ 1122 PSD_Anfangskruemmung_Vorz "Vorzeichen für die Startkrümmung bei Abzweigungen
";
CM_ SG_ 1122 PSD_Bebauung "Segement befindet sich innerhalb bebauten Gebietes";
CM_ SG_ 1122 PSD_Endkruemmung "'Endkrümmung der Klotoide des übermittelten Streckensegments. Die Anfangskrümmung des folgenden Streckensegments entspricht der Endkrümmung dieses Segments. Krümmung = 1/(1+0.155 * x²) [1/m]

";
CM_ SG_ 1122 PSD_Fahrspuren_Anzahl "Anzahl der Fahrspuren in Fahrtrichtung
";
CM_ SG_ 1122 PSD_Geradester_Pfad "Segment ist Teil des geradesten Pfades";
CM_ SG_ 1122 PSD_Idenditaets_ID "Identifier auf ein Streckensegment, dass mit dem aktuell übertragenen geometrisch identisch ist.";
CM_ SG_ 1122 PSD_Segment_ID "Identifier des prädiktiven Streckensegments
";
CM_ SG_ 1122 PSD_Segment_Komplett "Zeigt, ob alle Attribute für das Segment übertragen worden sind
";
CM_ SG_ 1122 PSD_Segmentlaenge "Gesamtlänge des prädiktiven Streckensegments";
CM_ SG_ 1122 PSD_Strassenkategorie "Klassifizierung der Straße des beschriebenen Segments
";
CM_ SG_ 1122 PSD_Vorgaenger_Segment_ID "An dem Streckensegment mit diesem Identifier schließt sich das neue Segment mit der ID 'PSD_01_Segment_ID' an.
";
CM_ SG_ 1122 PSD_wahrscheinlichster_Pfad "Identifiziert den vom Navigationssystem berechneten wahrscheinlichsten Pfad des Fahrzeuges. ";

CM_ SG_ 1123 PSD_Attribut_1_ID "Identifier des ersten Attributes";
CM_ SG_ 1123 PSD_Attribut_1_Offset "Positionsoffset im Segment für die Position des Attributs";
CM_ SG_ 1123 PSD_Attribut_1_Wert "Wert des ersten Attributes";
CM_ SG_ 1123 PSD_Attribut_2_ID "Identifier des zweiten Attributes";
CM_ SG_ 1123 PSD_Attribut_2_Offset "Positionsoffset im Segment für die Position des Attributs";
CM_ SG_ 1123 PSD_Attribut_2_Wert "Wert des zweiten Attributes";
CM_ SG_ 1123 PSD_Attribut_Segment_ID_05 "Identifier des Streckensegments, für das die weiteren Attribute in der Botschaft gültig sind";
CM_ SG_ 1123 PSD_Attribute_Komplett_05 "Zeigt, ob alle Attribute für das Segment übertragen worden sind";
CM_ SG_ 1123 PSD_Pos_Fahrspur "Spur, auf der sich das Fahrzeug aktuell befindet";
CM_ SG_ 1123 PSD_Pos_Fehler_Laengsrichtung "Laengsfehler der Positionierung";
CM_ SG_ 1123 PSD_Pos_Inhibitzeit "Zeitspanne zwischen Generierung der PSD Daten im Navigationssystem und Versand der Daten auf den Most
";
CM_ SG_ 1123 PSD_Pos_Segment_ID "Identifier des Streckensegments, auf dem sich das Fahrzeug aktuell befindet
";
CM_ SG_ 1123 PSD_Pos_Segmentlaenge "Verbleibende Länge des Streckensegments, auf dem sich das Fahrzeug aktuell befindet
";
CM_ SG_ 1123 PSD_Pos_Standort_Eindeutig "Ist die Position des Fahrzeugs eindeutig dem aktuelle Segment zugeordnet, oder gibt es fahrbare alternative Segmente, die bei akteller GPS-Position ebenfalls als aktuelles Segment möglich wären.";

CM_ SG_ 1124 PSD_06_Mux "Multiplex Zähler für die PSD_06-Botschaft.
Die unterschiedlichen Muxe folgen keiner festen Reihenfolge. Je nach Inhalt des PSD-Protokolls an der aktuellen Position werden jeweils die notwendigen PSD6-Botschaften gesendet.";
CM_ SG_ 1124 PSD_Attribut_3_ID "Identifier des dritten Attributes";
CM_ SG_ 1124 PSD_Attribut_3_Offset "Positionsoffset im Segment für die Position des Attributs";
CM_ SG_ 1124 PSD_Attribut_3_Wert "Wert des dritten Attributes";
CM_ SG_ 1124 PSD_Attribut_4_ID "Typ von Attribut 4";
CM_ SG_ 1124 PSD_Attribut_4_Offset "Offset von Attribut 4";
CM_ SG_ 1124 PSD_Attribut_4_Wert "Wert von Attribut 4";
CM_ SG_ 1124 PSD_Attribut_5_ID "Typ von Attribut 5";
CM_ SG_ 1124 PSD_Attribut_5_Offset "Offset von Attribut 5";
CM_ SG_ 1124 PSD_Attribut_5_Wert "Wert von Attribut 5";
CM_ SG_ 1124 PSD_Attribut_Segment_ID "Identifier des Streckensegments,für das die weiteren Attribute in der Botschaft gültig sind";
CM_ SG_ 1124 PSD_Attribute_Komplett_06 "Zeigt, ob alle Attribute für das Segment übertragen worden sind
";
CM_ SG_ 1124 PSD_Baum_Ausrichtung "Ausrichtung des Fahrzeugsegments zu Nord";
CM_ SG_ 1124 PSD_Baum_Breite "WGS84 Breite des Fahrzeugsegments";
CM_ SG_ 1124 PSD_Baum_Breite_VZ "Vorzeichen WGS84 Breite des Fahrzeugsegments";
CM_ SG_ 1124 PSD_Baum_Laenge "WGS84 Laenge des Fahrzeugsegments";
CM_ SG_ 1124 PSD_Baum_Laenge_VZ "Vorzeichen WGS84 Laenge des Fahrzeugsegments";
CM_ SG_ 1124 PSD_Ges_Attribute_Komplett "Zeigt, ob alle Attribute für das Segment übertragen worden sind";
CM_ SG_ 1124 PSD_Ges_Geschwindigkeit_Gespann "Gilt diese Einschränkung der Geschwindigkeit für alle Fahrzeuge oder ausschließlich für PKW mit Gespann oder für LKW, Buss, etc.";
CM_ SG_ 1124 PSD_Ges_Geschwindigkeit_Std_Anf "Stunde, zu der die stündliche Geschwindigkeitsbegrenzung beginnt
0h.. 24h";
CM_ SG_ 1124 PSD_Ges_Geschwindigkeit_Std_Ende "Stunde, an der die stündliche Geschwindigkeitsbegrenzung endet
0h.. 24h";
CM_ SG_ 1124 PSD_Ges_Geschwindigkeit_Tag_Anf "Wochentag, an dem die tägliche Geschwindigkeitsbegrenzung beginnt";
CM_ SG_ 1124 PSD_Ges_Geschwindigkeit_Tag_Ende "Wochentag, an dem die tägliche Geschwindigkeitsbegrenzung endet";
CM_ SG_ 1124 PSD_Ges_Geschwindigkeit_Witter "Witterungsabhängigkeit der Geschwindigkeitsbegrenzung";
CM_ SG_ 1124 PSD_Ges_Gesetzlich_Kategorie "Kategorie für das legale Gebot";
CM_ SG_ 1124 PSD_Ges_Gesetzlich_Zusatz "Zusatz für das legale Gebot";
CM_ SG_ 1124 PSD_Ges_Offset "Positionsoffset im Segment für die Position des Attributs";
CM_ SG_ 1124 PSD_Ges_Segment_ID "Identifier des prädiktiven Streckensegments ab dem die Geschwindigkeitsbegrenzungen und mögliche Einschränkungen gelten.
";
CM_ SG_ 1124 PSD_Ges_Spur_Geschw_Begrenzung "Definition der Spuren, für die das übertragene Gebot gilt";
CM_ SG_ 1124 PSD_Ges_Typ "Typ der Geschwindigkeitsbegrenzung
";
CM_ SG_ 1124 PSD_Ges_Verkehrszeichen_Quelle "Quelle der Verkehrszeicheninformation";
CM_ SG_ 1124 PSD_Ges_Wechselverkehrszeichen "Am Beginn des Segments ist ein Wechselverkehrszeichen angebracht.";
CM_ SG_ 1124 PSD_Steigung_1_A_Offset "Positionsoffset im Segment für die Position der Steigung 1 A";
CM_ SG_ 1124 PSD_Steigung_1_A_Steigung "Steigung des Segments ab Offset 1A";
CM_ SG_ 1124 PSD_Steigung_1_A_Vorz "Vorzeichen für Steigung 1 A";
CM_ SG_ 1124 PSD_Steigung_1_Attribute_kompl "Alle Steigungsdaten für dieses Segment gesendet";
CM_ SG_ 1124 PSD_Steigung_1_B_Offset "Positionsoffset im Segment für die Position der Steigung 1 B";
CM_ SG_ 1124 PSD_Steigung_1_B_Steigung "Steigung des Segments ab Offset 1B";
CM_ SG_ 1124 PSD_Steigung_1_B_Vorz "Vorzeichen für Steigung 1 B";
CM_ SG_ 1124 PSD_Steigung_1_Segment_ID "Identifier des prädiktiven Streckensegments, zu dem die  ersten beiden Steigungswerte dieser Botschaft gehören";
CM_ SG_ 1124 PSD_Steigung_2_Attribute_kompl "Alle Steigungsdaten für dieses Segment gesendet";
CM_ SG_ 1124 PSD_Steigung_2_Offset "Positionsoffset im Segment für die Position der Steigung 2";
CM_ SG_ 1124 PSD_Steigung_2_Segment_ID "Identifier des prädiktiven Streckensegments, zu dem der dritte Steigungswert dieser Botschaft gehört";
CM_ SG_ 1124 PSD_Steigung_2_Steigung "Steigung des Segments ab Offset 2";
CM_ SG_ 1124 PSD_Steigung_2_Vorz "Vorzeichen für Steigung 2";
CM_ SG_ 1124 PSD_Sys_Alter_Karte "Alter der Karte";
CM_ SG_ 1124 PSD_Sys_Geometrieguete "Maß für die Güte der Klothoidengeometrie.";
CM_ SG_ 1124 PSD_Sys_Geometrieguete_erweitert "Güte der Kurvenrepräsentation der Klothoiden";
CM_ SG_ 1124 PSD_Sys_Geschwindigkeit_Einheit "Unterscheidung zwischen km/h und miles/h";
CM_ SG_ 1124 PSD_Sys_Laendercode "Ländercode
";
CM_ SG_ 1124 PSD_Sys_Mapmatchingguete "Güte des Mapmatchings";
CM_ SG_ 1124 PSD_Sys_Quali_Geometrien "Qualität der Geometrien in dieser Region";
CM_ SG_ 1124 PSD_Sys_Quali_Ortsinfo "Qualität Ortsinformationen (Bebauung, Ortsschild) dieser Region";
CM_ SG_ 1124 PSD_Sys_Quali_sonstige_Attribute "Qualität sonstiger Attribute dieser Region";
CM_ SG_ 1124 PSD_Sys_Quali_Steigungen "Qualität der Steigungen dieser Region";
CM_ SG_ 1124 PSD_Sys_Quali_Strassenkennz "Qualität Straßenkennzeichnungen dieser Region";
CM_ SG_ 1124 PSD_Sys_Quali_Tempolimits "Qualität Tempolimits dieser Region";
CM_ SG_ 1124 PSD_Sys_Quali_verfuegbar "Karte enthält gültige Qualitätskriterien";
CM_ SG_ 1124 PSD_Sys_Quali_Vorfahrtsregelung "Qualität Vorfahrtsregelungen dieser Region";
CM_ SG_ 1124 PSD_Sys_Segment_ID "Identifier des prädiktiven Streckensegments ab dem die Systeminformationen gültig sind.
";
CM_ SG_ 1124 PSD_Sys_US_State "Name des USA-State";
CM_ SG_ 1124 PSD_Sys_Verkehrsrichtung "Unterscheidung zwischen Linksverkehr und Rechtsverkehr";
CM_ SG_ 1124 PSD_Sys_Zielfuehrung "Zielfuehrung im Navigationssystem. Damit lässt sich der wahrscheinlichste Pfad des Fahrzeuges zuverlässig angeben.";
CM_ SG_ 1124 PSD_Sys_Zielfuehrung_geaendert "Die Zielführung (Route) hat sich geändert hat ohne dass der Fahrer eine neue Zielführung gestartet hat";
CM_ SG_ 1124 PSD_Wechselverkehrszeichen_Typ "Typ des Wechselverkehrszeichen";

CM_ SG_ 591 RDR1_Blindheit_erkannt "Blindheitserkennung";
CM_ SG_ 591 RDR1_Obj_01_ax_StdA "Standardabweichung der Relativbeschleunigung in x-Richtung des bezüglich des Ego-Fzg. Momentankurses detektierten Objektes";
CM_ SG_ 591 RDR1_Obj_01_ax_v "Relativbeschleunigung in x-Richtung des bezüglich des Ego-Fzg. Momentankurses detektierten Objektes";
CM_ SG_ 591 RDR1_Obj_01_dx_StdA "Standardabweichung des x-Abstands des bezüglich des Ego-Fzg.-Momentankurses detektierten Objektdatenblocks";
CM_ SG_ 591 RDR1_Obj_01_dx_v "x-Abstand des bezüglich des Ego-Fzg.-Momentankurses detektierten Objektdatenblocks";
CM_ SG_ 591 RDR1_Obj_01_dy_StdA "Standardabweichung des y-Abstands des bezüglich des Ego-Fzg.-Momentankurses detektierten Objektdatenblocks";
CM_ SG_ 591 RDR1_Obj_01_dy_v "y-Abstand des bezüglich des Ego-Fzg.-Momentankurses detektierten Objektdatenblocks";
CM_ SG_ 591 RDR1_Obj_01_Nummer "Interne Objektnummer (Track)";
CM_ SG_ 591 RDR1_Obj_01_vx_StdA "Standardabweichung der Relativgeschwindigkeit in x-Richtung des bezüglich des Ego-Fzg. Momentankurses detektierten Objektes";
CM_ SG_ 591 RDR1_Obj_01_vx_v "Relativgeschwindigkeit in x-Richtung des bezüglich des Ego-Fzg. Momentankurses detektierten Objektes";
CM_ SG_ 591 RDR1_Obj_02_dx_v "x-Abstand des bezüglich des Ego-Fzg.-Momentankurses detektierten Objektdatenblocks";
CM_ SG_ 591 RDR1_Obj_02_dy_v "y-Abstand des bezüglich des Ego-Fzg.-Momentankurses detektierten Objektdatenblocks";
CM_ SG_ 591 RDR1_Obj_02_Nummer "Interne Objektnummer (Track)";
CM_ SG_ 591 RDR1_Obj_02_vx_v "Relativgeschwindigkeit in x-Richtung des bezüglich des Ego-Fzg. Momentankurses detektierten Objektes";
CM_ SG_ 591 RDR1_Obj_03_dx_v "x-Abstand des bezüglich des Ego-Fzg.-Momentankurses detektierten Objektdatenblocks";
CM_ SG_ 591 RDR1_Obj_03_dy_v "y-Abstand des bezüglich des Ego-Fzg.-Momentankurses detektierten Objektdatenblocks";
CM_ SG_ 591 RDR1_Obj_03_Nummer "Interne Objektnummer (Track)";
CM_ SG_ 591 RDR1_Obj_03_vx_v "Relativgeschwindigkeit in x-Richtung des bezüglich des Ego-Fzg. Momentankurses detektierten Objektes";
CM_ SG_ 591 RDR1_Obj_04_dx_v "x-Abstand des bezüglich des Ego-Fzg.-Momentankurses detektierten Objektdatenblocks";
CM_ SG_ 591 RDR1_Obj_04_dy_v "y-Abstand des bezüglich des Ego-Fzg.-Momentankurses detektierten Objektdatenblocks";
CM_ SG_ 591 RDR1_Obj_04_Nummer "Interne Objektnummer (Track)";
CM_ SG_ 591 RDR1_Obj_04_vx_v "Relativgeschwindigkeit in x-Richtung des bezüglich des Ego-Fzg. Momentankurses detektierten Objektes";
CM_ SG_ 591 RDR1_Obj_05_dx_v "x-Abstand des bezüglich des Ego-Fzg.-Momentankurses detektierten Objektdatenblocks";
CM_ SG_ 591 RDR1_Obj_05_dy_v "y-Abstand des bezüglich des Ego-Fzg.-Momentankurses detektierten Objektdatenblocks";
CM_ SG_ 591 RDR1_Obj_05_Nummer "Interne Objektnummer (Track)";
CM_ SG_ 591 RDR1_Obj_05_vx_v "Relativgeschwindigkeit in x-Richtung des bezüglich des Ego-Fzg. Momentankurses detektierten Objektes";
CM_ SG_ 591 RDR1_Obj_06_dx_v "x-Abstand des bezüglich des Ego-Fzg.-Momentankurses detektierten Objektdatenblocks";
CM_ SG_ 591 RDR1_Obj_06_dy_v "y-Abstand des bezüglich des Ego-Fzg.-Momentankurses detektierten Objektdatenblocks";
CM_ SG_ 591 RDR1_Obj_06_Nummer "Interne Objektnummer (Track)";
CM_ SG_ 591 RDR1_Obj_06_vx_v "Relativgeschwindigkeit in x-Richtung des bezüglich des Ego-Fzg. Momentankurses detektierten Objektes";
CM_ SG_ 591 RDR1_Objekte_02_Datenalter "Datenalter der Objekte aus Botschaft RDR1_Objekte_02";
CM_ SG_ 591 RDR1_relev_Nichtverfuegbarkeit "RDR1-SG erkennt eine temporäre Nichtverfügbarkeit, ohne FSP-Eintrag";
CM_ SG_ 591 RDR1_relevanter_Fehler "RDR1-SG erkennt einen Fehler, mit FSP-Eintrag.";
CM_ SG_ 591 RDR1_Verkehrssinn "vom Radar erkannter Verkehrssinn";

CM_ SG_ 2033 Request_Airbag_Deployment "Request für die Disposal Diagnose (ISO26021)";

CM_ SG_ 2041 Response_Airbag_Deployment "Response für die Disposal Diagnose (ISO26021)";
BA_DEF_REL_ BU_SG_REL_  "GenSigTimeoutTime" INT 0 65535;
BA_DEF_ BO_  "DiagRequest" ENUM "No", "Yes";
BA_DEF_ BO_  "DiagResponse" ENUM "No", "Yes";
BA_DEF_ BO_  "DiagState" ENUM "No", "Yes";
BA_DEF_ BO_  "GenMsgChkConstant" HEX 0 4095;
BA_DEF_ BO_  "GenMsgCycleTime" INT 0 65535;
BA_DEF_ BO_  "GenMsgCycleTimeFast" INT 0 65535;
BA_DEF_ BO_  "GenMsgDelayTime" INT 0 100000;
BA_DEF_ BO_  "GenMsgILSupport" ENUM "No", "Yes";
BA_DEF_ BO_  "GenMsgNrOfRepetition" INT 0 100;
BA_DEF_ BO_  "GenMsgPDUConstants" STRING;
BA_DEF_ BO_  "GenMsgSendType" ENUM "Cyclic", "not_used", "not_used", "not_used", "not_used", "not_used", "not_used", "IfActive", "NoMsgSendType";
BA_DEF_ BO_  "GenMsgStartDelayTime" INT 0 100000;
BA_DEF_ BO_  "NmMessage" ENUM "No", "Yes";
BA_DEF_ BO_  "NmhMessage" ENUM "No", "Yes";
BA_DEF_ BO_  "MsgType" ENUM "Application", "NM ", "NMH", "TP2.0", "ISO-TP ", "BAP", "EID", "KS";
BA_DEF_ BO_  "VAGTP20_API" HEX 0 255;
BA_DEF_ BO_  "VAGTP20_DynConnection" ENUM "No", "Yes";
BA_DEF_ BO_  "VAGTP20_DynSetup" ENUM "No", "Yes";
BA_DEF_ BO_  "VAGTP20_StatConnection" ENUM "No", "Yes";
BA_DEF_ BO_  "CANFD_BRS" ENUM "0", "1";
BA_DEF_ BO_  "VFrameFormat" ENUM "StandardCAN", "ExtendedCAN", "reserved", "reserved", "reserved", "reserved", "reserved", "reserved", "reserved", "reserved", "reserved", "reserved", "reserved", "reserved", "StandardCAN_FD", "ExtendedCAN_FD";
BA_DEF_ SG_  "GenSigActiveRepetitions" INT -2147483648 2147483647;
BA_DEF_ SG_  "GenSigInactiveValue" INT -2147483648 2147483647;
BA_DEF_ SG_  "GenSigSendType" ENUM "Cyclic", "OnWrite", "OnWriteWithRepetition", "OnChange", "OnChangeWithRepetition", "IfActive", "IfActiveWithRepetition", "NoSigSendType", "OnChangeAndIfActive", "OnChangeAndIfActiveWithRepetition";
BA_DEF_ SG_  "GenSigStartValue" INT -2147483648 2147483647;
BA_DEF_ SG_  "NWM-WakeupAllowed" ENUM "No", "Yes";
BA_DEF_ SG_  "GenSigFuncType" ENUM "NoFunction", "MsgCounter", "CRC-8", "XOR", "XOR-2", "DatedBit", "SW-Kl15", "CHK", "Constant", "Protocol", "CRC-8-SAE_J1850";
BA_DEF_ SG_  "GenSigSwitchedByIgnition" ENUM "No", "Yes";
BA_DEF_ SG_  "Fehlerwert" HEX 0 2147483647;
BA_DEF_ SG_  "GenSigMissingSourceValue" HEX 0 2147483647;
BA_DEF_DEF_REL_  "GenSigTimeoutTime" 0;
BA_DEF_DEF_  "DiagRequest" "No";
BA_DEF_DEF_  "DiagResponse" "No";
BA_DEF_DEF_  "DiagState" "No";
BA_DEF_DEF_  "GenMsgChkConstant" 0;
BA_DEF_DEF_  "GenMsgCycleTime" 0;
BA_DEF_DEF_  "GenMsgCycleTimeFast" 0;
BA_DEF_DEF_  "GenMsgDelayTime" 0;
BA_DEF_DEF_  "GenMsgILSupport" "No";
BA_DEF_DEF_  "GenMsgNrOfRepetition" 0;
BA_DEF_DEF_  "GenMsgPDUConstants" "";
BA_DEF_DEF_  "GenMsgSendType" "NoMsgSendType";
BA_DEF_DEF_  "GenMsgStartDelayTime" 0;
BA_DEF_DEF_  "NmMessage" "No";
BA_DEF_DEF_  "NmhMessage" "No";
BA_DEF_DEF_  "MsgType" "Application";
BA_DEF_DEF_  "VAGTP20_API" 0;
BA_DEF_DEF_  "VAGTP20_DynConnection" "No";
BA_DEF_DEF_  "VAGTP20_DynSetup" "No";
BA_DEF_DEF_  "VAGTP20_StatConnection" "No";
BA_DEF_DEF_  "CANFD_BRS" "1";
BA_DEF_DEF_  "VFrameFormat" "StandardCAN";
BA_DEF_DEF_  "GenSigActiveRepetitions" 0;
BA_DEF_DEF_  "GenSigInactiveValue" 0;
BA_DEF_DEF_  "GenSigSendType" "NoSigSendType";
BA_DEF_DEF_  "GenSigStartValue" 0;
BA_DEF_DEF_  "NWM-WakeupAllowed" "No";
BA_DEF_DEF_  "GenSigFuncType" "NoFunction";
BA_DEF_DEF_  "GenSigSwitchedByIgnition" "Yes";
BA_DEF_DEF_  "Fehlerwert" 0;
BA_DEF_DEF_  "GenSigMissingSourceValue" 0;
BA_ "GenMsgChkConstant" BO_ 1601 71;
BA_ "GenMsgCycleTime" BO_ 1601 1000;
BA_ "GenMsgILSupport" BO_ 1601 1;
BA_ "GenMsgPDUConstants" BO_ 1601 "0x47,0x47,0x47,0x47,0x47,0x47,0x47,0x47,0x47,0x47,0x47,0x47,0x47,0x47,0x47,0x47";
BA_ "GenMsgSendType" BO_ 1601 0;
BA_ "VFrameFormat" BO_ 1601 14;
BA_ "GenMsgCycleTime" BO_ 1155 500;
BA_ "GenMsgDelayTime" BO_ 1155 50;
BA_ "GenMsgILSupport" BO_ 1155 1;
BA_ "GenMsgSendType" BO_ 1155 0;
BA_ "VFrameFormat" BO_ 1155 14;
BA_ "GenMsgCycleTime" BO_ 2527679686 2000;
BA_ "GenMsgDelayTime" BO_ 2527679686 100;
BA_ "GenMsgILSupport" BO_ 2527679686 1;
BA_ "GenMsgSendType" BO_ 2527679686 0;
BA_ "VFrameFormat" BO_ 2527679686 15;
BA_ "GenMsgILSupport" BO_ 22 1;
BA_ "VFrameFormat" BO_ 22 14;
BA_ "GenMsgILSupport" BO_ 24 1;
BA_ "VFrameFormat" BO_ 24 14;
BA_ "GenMsgCycleTime" BO_ 339 200;
BA_ "GenMsgDelayTime" BO_ 339 10;
BA_ "GenMsgILSupport" BO_ 339 1;
BA_ "GenMsgPDUConstants" BO_ 339 "0x03,0x13,0x23,0x7a,0x40,0x51,0x68,0xba,0xa8,0xbe,0x55,0x02,0x11,0x31,0x76,0xec";
BA_ "GenMsgSendType" BO_ 339 0;
BA_ "VFrameFormat" BO_ 339 14;
BA_ "GenMsgCycleTime" BO_ 2600468501 200;
BA_ "GenMsgCycleTimeFast" BO_ 2600468501 10;
BA_ "NmhMessage" BO_ 2600468501 1;
BA_ "MsgType" BO_ 2600468501 2;
BA_ "CANFD_BRS" BO_ 2600468501 0;
BA_ "VFrameFormat" BO_ 2600468501 1;
BA_ "GenMsgCycleTime" BO_ 2600468604 200;
BA_ "GenMsgCycleTimeFast" BO_ 2600468604 10;
BA_ "NmhMessage" BO_ 2600468604 1;
BA_ "MsgType" BO_ 2600468604 2;
BA_ "CANFD_BRS" BO_ 2600468604 0;
BA_ "VFrameFormat" BO_ 2600468604 1;
BA_ "GenMsgCycleTime" BO_ 2600468496 200;
BA_ "GenMsgCycleTimeFast" BO_ 2600468496 10;
BA_ "NmhMessage" BO_ 2600468496 1;
BA_ "MsgType" BO_ 2600468496 2;
BA_ "CANFD_BRS" BO_ 2600468496 0;
BA_ "VFrameFormat" BO_ 2600468496 1;
BA_ "GenMsgCycleTime" BO_ 2600468664 200;
BA_ "GenMsgCycleTimeFast" BO_ 2600468664 10;
BA_ "NmhMessage" BO_ 2600468664 1;
BA_ "MsgType" BO_ 2600468664 2;
BA_ "CANFD_BRS" BO_ 2600468664 0;
BA_ "VFrameFormat" BO_ 2600468664 1;
BA_ "GenMsgCycleTime" BO_ 2600468598 200;
BA_ "GenMsgCycleTimeFast" BO_ 2600468598 10;
BA_ "NmhMessage" BO_ 2600468598 1;
BA_ "MsgType" BO_ 2600468598 2;
BA_ "CANFD_BRS" BO_ 2600468598 0;
BA_ "VFrameFormat" BO_ 2600468598 1;
BA_ "GenMsgCycleTime" BO_ 2600468733 200;
BA_ "GenMsgCycleTimeFast" BO_ 2600468733 10;
BA_ "NmhMessage" BO_ 2600468733 1;
BA_ "MsgType" BO_ 2600468733 2;
BA_ "CANFD_BRS" BO_ 2600468733 0;
BA_ "VFrameFormat" BO_ 2600468733 1;
BA_ "DiagRequest" BO_ 2621440533 1;
BA_ "MsgType" BO_ 2621440533 4;
BA_ "VFrameFormat" BO_ 2621440533 15;
BA_ "DiagResponse" BO_ 2621571605 1;
BA_ "MsgType" BO_ 2621571605 4;
BA_ "VFrameFormat" BO_ 2621571605 15;
BA_ "DiagRequest" BO_ 2621440636 1;
BA_ "MsgType" BO_ 2621440636 4;
BA_ "VFrameFormat" BO_ 2621440636 15;
BA_ "DiagResponse" BO_ 2621571708 1;
BA_ "MsgType" BO_ 2621571708 4;
BA_ "VFrameFormat" BO_ 2621571708 15;
BA_ "DiagRequest" BO_ 2621440696 1;
BA_ "MsgType" BO_ 2621440696 4;
BA_ "VFrameFormat" BO_ 2621440696 15;
BA_ "DiagResponse" BO_ 2621571768 1;
BA_ "MsgType" BO_ 2621571768 4;
BA_ "VFrameFormat" BO_ 2621571768 15;
BA_ "DiagState" BO_ 2621506048 1;
BA_ "MsgType" BO_ 2621506048 4;
BA_ "VFrameFormat" BO_ 2621506048 15;
BA_ "DiagRequest" BO_ 2621440630 1;
BA_ "MsgType" BO_ 2621440630 4;
BA_ "VFrameFormat" BO_ 2621440630 15;
BA_ "DiagResponse" BO_ 2621571702 1;
BA_ "MsgType" BO_ 2621571702 4;
BA_ "VFrameFormat" BO_ 2621571702 15;
BA_ "DiagState" BO_ 2564502513 1;
BA_ "MsgType" BO_ 2564502513 4;
BA_ "VFrameFormat" BO_ 2564502513 15;
BA_ "DiagRequest" BO_ 2564425457 1;
BA_ "MsgType" BO_ 2564425457 4;
BA_ "VFrameFormat" BO_ 2564425457 15;
BA_ "DiagResponse" BO_ 2564485382 1;
BA_ "MsgType" BO_ 2564485382 4;
BA_ "VFrameFormat" BO_ 2564485382 15;
BA_ "DiagRequest" BO_ 2564425713 1;
BA_ "MsgType" BO_ 2564425713 4;
BA_ "VFrameFormat" BO_ 2564425713 15;
BA_ "DiagResponse" BO_ 2564485383 1;
BA_ "MsgType" BO_ 2564485383 4;
BA_ "VFrameFormat" BO_ 2564485383 15;
BA_ "DiagRequest" BO_ 2564424177 1;
BA_ "MsgType" BO_ 2564424177 4;
BA_ "VFrameFormat" BO_ 2564424177 15;
BA_ "DiagResponse" BO_ 2564485377 1;
BA_ "MsgType" BO_ 2564485377 4;
BA_ "VFrameFormat" BO_ 2564485377 15;
BA_ "GenMsgCycleTime" BO_ 627 100;
BA_ "GenMsgDelayTime" BO_ 627 10;
BA_ "GenMsgILSupport" BO_ 627 1;
BA_ "GenMsgPDUConstants" BO_ 627 "0xc6,0x40,0x32,0xbe,0xc7,0x76,0x16,0x17,0x05,0xd8,0xab,0x52,0x45,0x35,0xf1,0x1d";
BA_ "GenMsgSendType" BO_ 627 0;
BA_ "VFrameFormat" BO_ 627 14;
BA_ "GenMsgCycleTime" BO_ 2463978709 500;
BA_ "GenMsgDelayTime" BO_ 2463978709 50;
BA_ "GenMsgILSupport" BO_ 2463978709 1;
BA_ "GenMsgSendType" BO_ 2463978709 0;
BA_ "VFrameFormat" BO_ 2463978709 15;
BA_ "GenMsgCycleTime" BO_ 2589283656 500;
BA_ "GenMsgDelayTime" BO_ 2589283656 100;
BA_ "GenMsgILSupport" BO_ 2589283656 1;
BA_ "GenMsgSendType" BO_ 2589283656 0;
BA_ "VFrameFormat" BO_ 2589283656 15;
BA_ "GenMsgCycleTime" BO_ 2527679741 240;
BA_ "GenMsgILSupport" BO_ 2527679741 1;
BA_ "GenMsgPDUConstants" BO_ 2527679741 "0x9d,0xe8,0x36,0xa1,0xca,0x3b,0x1d,0x33,0xe0,0xd5,0xbb,0x5f,0xae,0x3c,0x31,0x9f";
BA_ "GenMsgSendType" BO_ 2527679741 0;
BA_ "VFrameFormat" BO_ 2527679741 15;
BA_ "GenMsgCycleTime" BO_ 518 20;
BA_ "GenMsgILSupport" BO_ 518 1;
BA_ "GenMsgSendType" BO_ 518 0;
BA_ "VFrameFormat" BO_ 518 14;
BA_ "GenMsgCycleTime" BO_ 2527679685 2000;
BA_ "GenMsgDelayTime" BO_ 2527679685 100;
BA_ "GenMsgILSupport" BO_ 2527679685 1;
BA_ "GenMsgSendType" BO_ 2527679685 0;
BA_ "VFrameFormat" BO_ 2527679685 15;
BA_ "GenMsgCycleTime" BO_ 319 200;
BA_ "GenMsgDelayTime" BO_ 319 20;
BA_ "GenMsgILSupport" BO_ 319 1;
BA_ "GenMsgSendType" BO_ 319 0;
BA_ "CANFD_BRS" BO_ 319 0;
BA_ "GenMsgCycleTime" BO_ 1122 150;
BA_ "GenMsgILSupport" BO_ 1122 1;
BA_ "GenMsgSendType" BO_ 1122 0;
BA_ "VFrameFormat" BO_ 1122 14;
BA_ "GenMsgCycleTime" BO_ 1123 150;
BA_ "GenMsgILSupport" BO_ 1123 1;
BA_ "GenMsgSendType" BO_ 1123 0;
BA_ "VFrameFormat" BO_ 1123 14;
BA_ "GenMsgCycleTime" BO_ 1124 150;
BA_ "GenMsgILSupport" BO_ 1124 1;
BA_ "GenMsgSendType" BO_ 1124 0;
BA_ "VFrameFormat" BO_ 1124 14;
BA_ "GenMsgCycleTime" BO_ 591 40;
BA_ "GenMsgILSupport" BO_ 591 1;
BA_ "GenMsgSendType" BO_ 591 0;
BA_ "VFrameFormat" BO_ 591 14;
BA_ "DiagRequest" BO_ 2033 1;
BA_ "MsgType" BO_ 2033 4;
BA_ "CANFD_BRS" BO_ 2033 0;
BA_ "DiagResponse" BO_ 2041 1;
BA_ "MsgType" BO_ 2041 4;
BA_ "CANFD_BRS" BO_ 2041 0;
BA_ "GenSigSendType" SG_ 1601 MO_Ansaugsystem 0;
BA_ "GenSigFuncType" SG_ 1601 MO_Ansaugsystem 8;
BA_ "GenSigSwitchedByIgnition" SG_ 1601 MO_Ansaugsystem 0;
BA_ "GenSigSendType" SG_ 1601 MO_Anzahl_Zyl 0;
BA_ "GenSigFuncType" SG_ 1601 MO_Anzahl_Zyl 8;
BA_ "GenSigSwitchedByIgnition" SG_ 1601 MO_Anzahl_Zyl 0;
BA_ "GenSigSendType" SG_ 1601 MO_Anzeige_StSt_gueltig 0;
BA_ "GenSigSwitchedByIgnition" SG_ 1601 MO_Anzeige_StSt_gueltig 0;
BA_ "GenSigSendType" SG_ 1601 MO_Code 0;
BA_ "GenSigSwitchedByIgnition" SG_ 1601 MO_Code 0;
BA_ "GenSigSendType" SG_ 1601 MO_DPF_verbaut 0;
BA_ "GenSigFuncType" SG_ 1601 MO_DPF_verbaut 8;
BA_ "GenSigSwitchedByIgnition" SG_ 1601 MO_DPF_verbaut 0;
BA_ "GenSigSendType" SG_ 1601 MO_Faktor_Momente_02 0;
BA_ "GenSigFuncType" SG_ 1601 MO_Faktor_Momente_02 8;
BA_ "GenSigSwitchedByIgnition" SG_ 1601 MO_Faktor_Momente_02 0;
BA_ "GenSigSendType" SG_ 1601 MO_Getriebe_Code 0;
BA_ "GenSigSwitchedByIgnition" SG_ 1601 MO_Getriebe_Code 0;
BA_ "GenSigSendType" SG_ 1601 MO_Hubraum 0;
BA_ "GenSigFuncType" SG_ 1601 MO_Hubraum 8;
BA_ "GenSigSwitchedByIgnition" SG_ 1601 MO_Hubraum 0;
BA_ "GenSigSendType" SG_ 1601 MO_Hybridfahrzeug 0;
BA_ "GenSigFuncType" SG_ 1601 MO_Hybridfahrzeug 8;
BA_ "GenSigSwitchedByIgnition" SG_ 1601 MO_Hybridfahrzeug 0;
BA_ "GenSigSendType" SG_ 1601 MO_Kraftstoffart 0;
BA_ "GenSigFuncType" SG_ 1601 MO_Kraftstoffart 8;
BA_ "GenSigSwitchedByIgnition" SG_ 1601 MO_Kraftstoffart 0;
BA_ "GenSigSendType" SG_ 1601 MO_Leistung 0;
BA_ "GenSigFuncType" SG_ 1601 MO_Leistung 8;
BA_ "GenSigSwitchedByIgnition" SG_ 1601 MO_Leistung 0;
BA_ "GenSigSendType" SG_ 1601 MO_OBD_Typ 0;
BA_ "GenSigFuncType" SG_ 1601 MO_OBD_Typ 8;
BA_ "GenSigSwitchedByIgnition" SG_ 1601 MO_OBD_Typ 0;
BA_ "GenSigSendType" SG_ 1601 MO_StartStopp_Codiert 0;
BA_ "GenSigFuncType" SG_ 1601 MO_StartStopp_Codiert 8;
BA_ "GenSigSwitchedByIgnition" SG_ 1601 MO_StartStopp_Codiert 0;
BA_ "GenSigSendType" SG_ 1601 Motor_Code_01_BZ 0;
BA_ "GenSigFuncType" SG_ 1601 Motor_Code_01_BZ 1;
BA_ "GenSigSwitchedByIgnition" SG_ 1601 Motor_Code_01_BZ 0;
BA_ "GenSigSendType" SG_ 1601 Motor_Code_01_CRC 0;
BA_ "GenSigFuncType" SG_ 1601 Motor_Code_01_CRC 2;
BA_ "GenSigSwitchedByIgnition" SG_ 1601 Motor_Code_01_CRC 0;
BA_ "GenSigSendType" SG_ 1601 TSK_Codierung 0;
BA_ "GenSigStartValue" SG_ 1601 TSK_Codierung 7;
BA_ "GenSigSwitchedByIgnition" SG_ 1601 TSK_Codierung 0;
BA_ "GenSigSendType" SG_ 1155 MO_Powermeter_Charge_Grenze 3;
BA_ "GenSigStartValue" SG_ 1155 MO_Powermeter_Charge_Grenze 1022;
BA_ "GenSigSwitchedByIgnition" SG_ 1155 MO_Powermeter_Charge_Grenze 0;
BA_ "Fehlerwert" SG_ 1155 MO_Powermeter_Charge_Grenze 1023;
BA_ "GenSigSendType" SG_ 1155 Mo_Powermeter_Grenze 3;
BA_ "GenSigStartValue" SG_ 1155 Mo_Powermeter_Grenze 4093;
BA_ "GenSigSwitchedByIgnition" SG_ 1155 Mo_Powermeter_Grenze 0;
BA_ "GenSigSendType" SG_ 1155 MO_Powermeter_Grenze_strategisch 3;
BA_ "GenSigStartValue" SG_ 1155 MO_Powermeter_Grenze_strategisch 4094;
BA_ "GenSigSwitchedByIgnition" SG_ 1155 MO_Powermeter_Grenze_strategisch 0;
BA_ "Fehlerwert" SG_ 1155 MO_Powermeter_Grenze_strategisch 4095;
BA_ "GenSigSendType" SG_ 1155 MO_Powermeter_Inszenierung_aktiv 3;
BA_ "GenSigSwitchedByIgnition" SG_ 1155 MO_Powermeter_Inszenierung_aktiv 0;
BA_ "GenSigSendType" SG_ 1155 MO_Powermeter_obere_E_Grenze 3;
BA_ "GenSigStartValue" SG_ 1155 MO_Powermeter_obere_E_Grenze 4094;
BA_ "GenSigSwitchedByIgnition" SG_ 1155 MO_Powermeter_obere_E_Grenze 0;
BA_ "Fehlerwert" SG_ 1155 MO_Powermeter_obere_E_Grenze 4095;
BA_ "GenSigSendType" SG_ 1155 MO_Powermeter_untere_E_Grenze 3;
BA_ "GenSigStartValue" SG_ 1155 MO_Powermeter_untere_E_Grenze 4094;
BA_ "GenSigSwitchedByIgnition" SG_ 1155 MO_Powermeter_untere_E_Grenze 0;
BA_ "Fehlerwert" SG_ 1155 MO_Powermeter_untere_E_Grenze 4095;
BA_ "GenSigSendType" SG_ 1155 MO_Text_Aktivierung_Antrieb 3;
BA_ "GenSigStartValue" SG_ 1155 MO_Text_Aktivierung_Antrieb 15;
BA_ "GenSigSwitchedByIgnition" SG_ 1155 MO_Text_Aktivierung_Antrieb 0;
BA_ "GenSigSendType" SG_ 2527679686 MRR_HR_ASM_Data_1 0;
BA_ "GenSigSendType" SG_ 2527679686 MRR_HR_ASM_Data_2 0;
BA_ "GenSigSendType" SG_ 2527679686 MRR_HR_ASM_Data_3 0;
BA_ "GenSigSendType" SG_ 2527679686 MRR_HR_ASM_Data_4 0;
BA_ "GenSigSendType" SG_ 2527679686 MRR_HR_ASM_Data_5 0;
BA_ "GenSigSendType" SG_ 2527679686 MRR_HR_ASM_Data_6 0;
BA_ "GenSigSendType" SG_ 2527679686 MRR_HR_ASM_Ereignis 3;
BA_ "GenSigSendType" SG_ 2527679686 MRR_HR_ASM_Zeitstempel 3;
BA_ "GenSigStartValue" SG_ 2527679686 MRR_HR_ASM_Zeitstempel 255;
BA_ "GenSigSwitchedByIgnition" SG_ 22 WFS_MSG3_CRC 0;
BA_ "GenSigSendType" SG_ 22 WFS_MSG3_RND 1;
BA_ "GenSigSwitchedByIgnition" SG_ 22 WFS_MSG3_RND 0;
BA_ "GenSigSwitchedByIgnition" SG_ 24 WFS_MSG4_CRC 0;
BA_ "GenSigSendType" SG_ 24 WFS_MSG4_RND 1;
BA_ "GenSigSwitchedByIgnition" SG_ 24 WFS_MSG4_RND 0;
BA_ "GenSigSendType" SG_ 339 MO_ErwGrenzen_Anf 3;
BA_ "GenSigSwitchedByIgnition" SG_ 339 MO_ErwGrenzen_Anf 0;
BA_ "GenSigSendType" SG_ 339 MO_Fehler_Notentladung_Anf 3;
BA_ "GenSigSwitchedByIgnition" SG_ 339 MO_Fehler_Notentladung_Anf 0;
BA_ "GenSigSendType" SG_ 339 MO_HVEM_Eskalation 3;
BA_ "GenSigSwitchedByIgnition" SG_ 339 MO_HVEM_Eskalation 0;
BA_ "GenSigSendType" SG_ 339 MO_HVEM_MaxLeistung 0;
BA_ "GenSigStartValue" SG_ 339 MO_HVEM_MaxLeistung 510;
BA_ "GenSigSwitchedByIgnition" SG_ 339 MO_HVEM_MaxLeistung 0;
BA_ "GenSigSendType" SG_ 339 MO_HVK_AntriebFehlerstatus 3;
BA_ "GenSigStartValue" SG_ 339 MO_HVK_AntriebFehlerstatus 7;
BA_ "GenSigSwitchedByIgnition" SG_ 339 MO_HVK_AntriebFehlerstatus 0;
BA_ "GenSigSendType" SG_ 339 MO_HVK_AntriebZustand 3;
BA_ "GenSigStartValue" SG_ 339 MO_HVK_AntriebZustand 7;
BA_ "GenSigSwitchedByIgnition" SG_ 339 MO_HVK_AntriebZustand 0;
BA_ "GenSigSendType" SG_ 339 MO_HVK_EmFehlerstatus 3;
BA_ "GenSigStartValue" SG_ 339 MO_HVK_EmFehlerstatus 7;
BA_ "GenSigSwitchedByIgnition" SG_ 339 MO_HVK_EmFehlerstatus 0;
BA_ "GenSigSendType" SG_ 339 MO_HVK_EmIstzustand 3;
BA_ "GenSigStartValue" SG_ 339 MO_HVK_EmIstzustand 255;
BA_ "GenSigSwitchedByIgnition" SG_ 339 MO_HVK_EmIstzustand 0;
BA_ "GenSigSendType" SG_ 339 MO_MVK_AntriebFehlerstatus 3;
BA_ "GenSigStartValue" SG_ 339 MO_MVK_AntriebFehlerstatus 7;
BA_ "GenSigSwitchedByIgnition" SG_ 339 MO_MVK_AntriebFehlerstatus 0;
BA_ "GenSigSendType" SG_ 339 MO_MVK_AntriebZustand 3;
BA_ "GenSigStartValue" SG_ 339 MO_MVK_AntriebZustand 7;
BA_ "GenSigSwitchedByIgnition" SG_ 339 MO_MVK_AntriebZustand 0;
BA_ "GenSigSendType" SG_ 339 MO_MVK_Bordnetz_Anf 3;
BA_ "GenSigSwitchedByIgnition" SG_ 339 MO_MVK_Bordnetz_Anf 0;
BA_ "GenSigSendType" SG_ 339 MO_MVK_EmFehlerstatus 3;
BA_ "GenSigStartValue" SG_ 339 MO_MVK_EmFehlerstatus 7;
BA_ "GenSigSwitchedByIgnition" SG_ 339 MO_MVK_EmFehlerstatus 0;
BA_ "GenSigSendType" SG_ 339 MO_MVK_EmIstzustand 3;
BA_ "GenSigStartValue" SG_ 339 MO_MVK_EmIstzustand 255;
BA_ "GenSigSwitchedByIgnition" SG_ 339 MO_MVK_EmIstzustand 0;
BA_ "GenSigSendType" SG_ 339 MSG_HYB_30_BZ 0;
BA_ "GenSigFuncType" SG_ 339 MSG_HYB_30_BZ 1;
BA_ "GenSigSwitchedByIgnition" SG_ 339 MSG_HYB_30_BZ 0;
BA_ "GenSigSendType" SG_ 339 MSG_HYB_30_CRC 0;
BA_ "GenSigFuncType" SG_ 339 MSG_HYB_30_CRC 2;
BA_ "GenSigSwitchedByIgnition" SG_ 339 MSG_HYB_30_CRC 0;
BA_ "GenSigSwitchedByIgnition" SG_ 2600468501 NM_Airbag_01_CAB_V10 0;
BA_ "GenSigSwitchedByIgnition" SG_ 2600468501 NM_Airbag_01_Car_Wakeup 0;
BA_ "GenSigSwitchedByIgnition" SG_ 2600468501 NM_Airbag_01_CBV_AWB 0;
BA_ "GenSigSwitchedByIgnition" SG_ 2600468501 NM_Airbag_01_CBV_CRI 0;
BA_ "GenSigSwitchedByIgnition" SG_ 2600468501 NM_Airbag_01_NM_aktiv_Diagnose 0;
BA_ "GenSigSwitchedByIgnition" SG_ 2600468501 NM_Airbag_01_NM_aktiv_KL15 0;
BA_ "GenSigSwitchedByIgnition" SG_ 2600468501 NM_Airbag_01_NM_aktiv_Tmin 0;
BA_ "GenSigSwitchedByIgnition" SG_ 2600468501 NM_Airbag_01_NM_State 0;
BA_ "GenSigSwitchedByIgnition" SG_ 2600468501 NM_Airbag_01_UDS_CC 0;
BA_ "GenSigSwitchedByIgnition" SG_ 2600468604 NM_EMotor_01_CAB_V10 0;
BA_ "GenSigSwitchedByIgnition" SG_ 2600468604 NM_EMotor_01_Car_Wakeup 0;
BA_ "GenSigSwitchedByIgnition" SG_ 2600468604 NM_EMotor_01_CBV_AWB 0;
BA_ "GenSigSwitchedByIgnition" SG_ 2600468604 NM_EMotor_01_CBV_CRI 0;
BA_ "GenSigSwitchedByIgnition" SG_ 2600468604 NM_EMotor_01_keine_HV_Entl 0;
BA_ "GenSigSwitchedByIgnition" SG_ 2600468604 NM_EMotor_01_NM_aktiv_Diagnose 0;
BA_ "GenSigSwitchedByIgnition" SG_ 2600468604 NM_EMotor_01_NM_aktiv_KL15 0;
BA_ "GenSigSwitchedByIgnition" SG_ 2600468604 NM_EMotor_01_NM_aktiv_Tmin 0;
BA_ "GenSigSwitchedByIgnition" SG_ 2600468604 NM_EMotor_01_NM_State 0;
BA_ "GenSigSwitchedByIgnition" SG_ 2600468604 NM_EMotor_01_UDS_CC 0;
BA_ "GenSigSwitchedByIgnition" SG_ 2600468496 NM_Gateway_CAB_V10 0;
BA_ "GenSigSwitchedByIgnition" SG_ 2600468496 NM_Gateway_Car_Wakeup 0;
BA_ "GenSigSwitchedByIgnition" SG_ 2600468496 NM_Gateway_CBV_AWB 0;
BA_ "GenSigFuncType" SG_ 2600468496 NM_Gateway_CBV_CRI 8;
BA_ "GenSigSwitchedByIgnition" SG_ 2600468496 NM_Gateway_CBV_CRI 0;
BA_ "GenSigSwitchedByIgnition" SG_ 2600468496 NM_Gateway_NM_aktiv_Diagnose 0;
BA_ "GenSigSwitchedByIgnition" SG_ 2600468496 NM_Gateway_NM_aktiv_KL15 0;
BA_ "GenSigSwitchedByIgnition" SG_ 2600468496 NM_Gateway_NM_aktiv_Tmin 0;
BA_ "GenSigSwitchedByIgnition" SG_ 2600468496 NM_Gateway_NM_State 0;
BA_ "GenSigSwitchedByIgnition" SG_ 2600468496 NM_Gateway_UDS_CC 0;
BA_ "GenSigSwitchedByIgnition" SG_ 2600468664 NM_LE2_CAB_V10 0;
BA_ "GenSigSwitchedByIgnition" SG_ 2600468664 NM_LE2_Car_Wakeup 0;
BA_ "GenSigSwitchedByIgnition" SG_ 2600468664 NM_LE2_CBV_AWB 0;
BA_ "GenSigFuncType" SG_ 2600468664 NM_LE2_CBV_CRI 8;
BA_ "GenSigSwitchedByIgnition" SG_ 2600468664 NM_LE2_CBV_CRI 0;
BA_ "GenSigSwitchedByIgnition" SG_ 2600468664 NM_LE2_keine_HV_entl 0;
BA_ "GenSigSwitchedByIgnition" SG_ 2600468664 NM_LE2_NM_aktiv_Diagnose 0;
BA_ "GenSigSwitchedByIgnition" SG_ 2600468664 NM_LE2_NM_aktiv_KL15 0;
BA_ "GenSigSwitchedByIgnition" SG_ 2600468664 NM_LE2_NM_aktiv_Tmin 0;
BA_ "GenSigSwitchedByIgnition" SG_ 2600468664 NM_LE2_NM_State 0;
BA_ "GenSigSwitchedByIgnition" SG_ 2600468664 NM_LE2_UDS_CC 0;
BA_ "GenSigSwitchedByIgnition" SG_ 2600468598 NM_MO_01_CAB_V10 0;
BA_ "GenSigSwitchedByIgnition" SG_ 2600468598 NM_MO_01_Car_Wakeup 0;
BA_ "GenSigSwitchedByIgnition" SG_ 2600468598 NM_MO_01_CBV_AWB 0;
BA_ "GenSigFuncType" SG_ 2600468598 NM_MO_01_CBV_CRI 8;
BA_ "GenSigSwitchedByIgnition" SG_ 2600468598 NM_MO_01_CBV_CRI 0;
BA_ "GenSigSwitchedByIgnition" SG_ 2600468598 NM_MO_01_NM_aktiv_Betankung 0;
BA_ "GenSigSwitchedByIgnition" SG_ 2600468598 NM_MO_01_NM_aktiv_Diagnose 0;
BA_ "GenSigSwitchedByIgnition" SG_ 2600468598 NM_MO_01_NM_aktiv_Hochvolt 0;
BA_ "GenSigSwitchedByIgnition" SG_ 2600468598 NM_MO_01_NM_aktiv_HV_Abschaltung 0;
BA_ "GenSigSwitchedByIgnition" SG_ 2600468598 NM_MO_01_NM_aktiv_KL15 0;
BA_ "GenSigSwitchedByIgnition" SG_ 2600468598 NM_MO_01_NM_aktiv_Tmin 0;
BA_ "GenSigSwitchedByIgnition" SG_ 2600468598 NM_MO_01_NM_aktiv_Waehlhebel 0;
BA_ "GenSigSwitchedByIgnition" SG_ 2600468598 NM_MO_01_NM_State 0;
BA_ "GenSigSwitchedByIgnition" SG_ 2600468598 NM_MO_01_UDS_CC 0;
BA_ "GenSigSwitchedByIgnition" SG_ 2600468733 NM_Waehlhebel_CAB_V10 0;
BA_ "GenSigSwitchedByIgnition" SG_ 2600468733 NM_Waehlhebel_Car_Wakeup 0;
BA_ "GenSigSwitchedByIgnition" SG_ 2600468733 NM_Waehlhebel_CBV_AWB 0;
BA_ "GenSigFuncType" SG_ 2600468733 NM_Waehlhebel_CBV_CRI 8;
BA_ "GenSigSwitchedByIgnition" SG_ 2600468733 NM_Waehlhebel_CBV_CRI 0;
BA_ "GenSigSwitchedByIgnition" SG_ 2600468733 NM_Waehlhebel_NM_aktiv_Diagnose 0;
BA_ "GenSigSwitchedByIgnition" SG_ 2600468733 NM_Waehlhebel_NM_aktiv_KL15 0;
BA_ "GenSigSwitchedByIgnition" SG_ 2600468733 NM_Waehlhebel_NM_aktiv_Tmin 0;
BA_ "GenSigSwitchedByIgnition" SG_ 2600468733 NM_Waehlhebel_NM_State 0;
BA_ "GenSigSwitchedByIgnition" SG_ 2600468733 NM_Waehlhebel_UDS_CC 0;
BA_ "GenSigSendType" SG_ 2621440533 OBDC_Airbag_01_Req_FD_Data 3;
BA_ "GenSigSwitchedByIgnition" SG_ 2621440533 OBDC_Airbag_01_Req_FD_Data 0;
BA_ "GenSigSendType" SG_ 2621571605 OBDC_Airbag_01_Resp_FD_Data 3;
BA_ "GenSigSwitchedByIgnition" SG_ 2621571605 OBDC_Airbag_01_Resp_FD_Data 0;
BA_ "GenSigSendType" SG_ 2621440636 OBDC_EMotor_01_Req_FD_Data 3;
BA_ "GenSigFuncType" SG_ 2621440636 OBDC_EMotor_01_Req_FD_Data 9;
BA_ "GenSigSwitchedByIgnition" SG_ 2621440636 OBDC_EMotor_01_Req_FD_Data 0;
BA_ "GenSigSendType" SG_ 2621571708 OBDC_EMotor_01_Resp_FD_Data 3;
BA_ "GenSigFuncType" SG_ 2621571708 OBDC_EMotor_01_Resp_FD_Data 9;
BA_ "GenSigSwitchedByIgnition" SG_ 2621571708 OBDC_EMotor_01_Resp_FD_Data 0;
BA_ "GenSigSendType" SG_ 2621440696 OBDC_EMotor_02_Req_FD_Data 3;
BA_ "GenSigFuncType" SG_ 2621440696 OBDC_EMotor_02_Req_FD_Data 9;
BA_ "GenSigSwitchedByIgnition" SG_ 2621440696 OBDC_EMotor_02_Req_FD_Data 0;
BA_ "GenSigSendType" SG_ 2621571768 OBDC_EMotor_02_Resp_FD_Data 3;
BA_ "GenSigFuncType" SG_ 2621571768 OBDC_EMotor_02_Resp_FD_Data 9;
BA_ "GenSigSwitchedByIgnition" SG_ 2621571768 OBDC_EMotor_02_Resp_FD_Data 0;
BA_ "GenSigSendType" SG_ 2621506048 OBDC_Funktion_Req_All_FD_Data 3;
BA_ "GenSigFuncType" SG_ 2621506048 OBDC_Funktion_Req_All_FD_Data 9;
BA_ "GenSigSwitchedByIgnition" SG_ 2621506048 OBDC_Funktion_Req_All_FD_Data 0;
BA_ "GenSigSendType" SG_ 2621440630 OBDC_MO_01_Req_FD_Data 3;
BA_ "GenSigFuncType" SG_ 2621440630 OBDC_MO_01_Req_FD_Data 9;
BA_ "GenSigSwitchedByIgnition" SG_ 2621440630 OBDC_MO_01_Req_FD_Data 0;
BA_ "GenSigSendType" SG_ 2621571702 OBDC_MO_01_Resp_FD_Data 3;
BA_ "GenSigFuncType" SG_ 2621571702 OBDC_MO_01_Resp_FD_Data 9;
BA_ "GenSigSwitchedByIgnition" SG_ 2621571702 OBDC_MO_01_Resp_FD_Data 0;
BA_ "GenSigSendType" SG_ 2564502513 OBDx_allOBD_Req_Data 3;
BA_ "GenSigFuncType" SG_ 2564502513 OBDx_allOBD_Req_Data 9;
BA_ "GenSigSwitchedByIgnition" SG_ 2564502513 OBDx_allOBD_Req_Data 0;
BA_ "GenSigSendType" SG_ 2564425457 OBDx_LE1_Req_Data 3;
BA_ "GenSigFuncType" SG_ 2564425457 OBDx_LE1_Req_Data 9;
BA_ "GenSigSwitchedByIgnition" SG_ 2564425457 OBDx_LE1_Req_Data 0;
BA_ "GenSigSendType" SG_ 2564485382 OBDx_LE1_Resp_Data 3;
BA_ "GenSigFuncType" SG_ 2564485382 OBDx_LE1_Resp_Data 9;
BA_ "GenSigSwitchedByIgnition" SG_ 2564485382 OBDx_LE1_Resp_Data 0;
BA_ "GenSigSendType" SG_ 2564425713 OBDx_LE2_Req_Data 3;
BA_ "GenSigFuncType" SG_ 2564425713 OBDx_LE2_Req_Data 9;
BA_ "GenSigSwitchedByIgnition" SG_ 2564425713 OBDx_LE2_Req_Data 0;
BA_ "GenSigSendType" SG_ 2564485383 OBDx_LE2_Resp_Data 3;
BA_ "GenSigFuncType" SG_ 2564485383 OBDx_LE2_Resp_Data 9;
BA_ "GenSigSwitchedByIgnition" SG_ 2564485383 OBDx_LE2_Resp_Data 0;
BA_ "GenSigSendType" SG_ 2564424177 OBDx_MO_01_Req_Data 3;
BA_ "GenSigSwitchedByIgnition" SG_ 2564424177 OBDx_MO_01_Req_Data 0;
BA_ "GenSigSendType" SG_ 2564485377 OBDx_MO_01_Resp_Data 3;
BA_ "GenSigSwitchedByIgnition" SG_ 2564485377 OBDx_MO_01_Resp_Data 0;
BA_ "GenSigSendType" SG_ 627 OCC_01_BZ 0;
BA_ "GenSigFuncType" SG_ 627 OCC_01_BZ 1;
BA_ "GenSigSwitchedByIgnition" SG_ 627 OCC_01_BZ 0;
BA_ "GenSigSendType" SG_ 627 OCC_01_CRC 0;
BA_ "GenSigFuncType" SG_ 627 OCC_01_CRC 2;
BA_ "GenSigSwitchedByIgnition" SG_ 627 OCC_01_CRC 0;
BA_ "GenSigSendType" SG_ 627 OCC_CC_Fehlerstatus_DC_GBT 0;
BA_ "GenSigSwitchedByIgnition" SG_ 627 OCC_CC_Fehlerstatus_DC_GBT 0;
BA_ "GenSigSendType" SG_ 627 OCC_CC_Latchstatus_DC_GBT 3;
BA_ "GenSigStartValue" SG_ 627 OCC_CC_Latchstatus_DC_GBT 6;
BA_ "GenSigSwitchedByIgnition" SG_ 627 OCC_CC_Latchstatus_DC_GBT 0;
BA_ "Fehlerwert" SG_ 627 OCC_CC_Latchstatus_DC_GBT 7;
BA_ "GenSigSendType" SG_ 627 OCC_CC_Status_DC_GBT 3;
BA_ "GenSigStartValue" SG_ 627 OCC_CC_Status_DC_GBT 2;
BA_ "GenSigSwitchedByIgnition" SG_ 627 OCC_CC_Status_DC_GBT 0;
BA_ "Fehlerwert" SG_ 627 OCC_CC_Status_DC_GBT 3;
BA_ "GenSigSendType" SG_ 627 OCC_CP_Status_A 3;
BA_ "GenSigStartValue" SG_ 627 OCC_CP_Status_A 2;
BA_ "GenSigSwitchedByIgnition" SG_ 627 OCC_CP_Status_A 0;
BA_ "Fehlerwert" SG_ 627 OCC_CP_Status_A 3;
BA_ "GenSigSendType" SG_ 627 OCC_CP_Status_B 3;
BA_ "GenSigStartValue" SG_ 627 OCC_CP_Status_B 2;
BA_ "GenSigSwitchedByIgnition" SG_ 627 OCC_CP_Status_B 0;
BA_ "Fehlerwert" SG_ 627 OCC_CP_Status_B 3;
BA_ "GenSigSendType" SG_ 627 OCC_DC_IstStrom 0;
BA_ "GenSigStartValue" SG_ 627 OCC_DC_IstStrom 2046;
BA_ "GenSigSwitchedByIgnition" SG_ 627 OCC_DC_IstStrom 0;
BA_ "Fehlerwert" SG_ 627 OCC_DC_IstStrom 2047;
BA_ "GenSigSendType" SG_ 627 OCC_I_istAC_Netz_L1 0;
BA_ "GenSigStartValue" SG_ 627 OCC_I_istAC_Netz_L1 510;
BA_ "GenSigSwitchedByIgnition" SG_ 627 OCC_I_istAC_Netz_L1 0;
BA_ "Fehlerwert" SG_ 627 OCC_I_istAC_Netz_L1 511;
BA_ "GenSigSendType" SG_ 627 OCC_I_istAC_Netz_L2 0;
BA_ "GenSigStartValue" SG_ 627 OCC_I_istAC_Netz_L2 510;
BA_ "GenSigSwitchedByIgnition" SG_ 627 OCC_I_istAC_Netz_L2 0;
BA_ "Fehlerwert" SG_ 627 OCC_I_istAC_Netz_L2 511;
BA_ "GenSigSendType" SG_ 627 OCC_I_istAC_Netz_L3 0;
BA_ "GenSigStartValue" SG_ 627 OCC_I_istAC_Netz_L3 510;
BA_ "GenSigSwitchedByIgnition" SG_ 627 OCC_I_istAC_Netz_L3 0;
BA_ "Fehlerwert" SG_ 627 OCC_I_istAC_Netz_L3 511;
BA_ "GenSigSendType" SG_ 627 OCC_IstModus 0;
BA_ "GenSigStartValue" SG_ 627 OCC_IstModus 6;
BA_ "GenSigSwitchedByIgnition" SG_ 627 OCC_IstModus 0;
BA_ "Fehlerwert" SG_ 627 OCC_IstModus 7;
BA_ "GenSigSendType" SG_ 627 OCC_IstSpannung_HV 0;
BA_ "GenSigStartValue" SG_ 627 OCC_IstSpannung_HV 1022;
BA_ "GenSigSwitchedByIgnition" SG_ 627 OCC_IstSpannung_HV 0;
BA_ "Fehlerwert" SG_ 627 OCC_IstSpannung_HV 1023;
BA_ "GenSigSendType" SG_ 627 OCC_PP_Latchstatus_A 3;
BA_ "GenSigStartValue" SG_ 627 OCC_PP_Latchstatus_A 6;
BA_ "GenSigSwitchedByIgnition" SG_ 627 OCC_PP_Latchstatus_A 0;
BA_ "Fehlerwert" SG_ 627 OCC_PP_Latchstatus_A 7;
BA_ "GenSigSendType" SG_ 627 OCC_PP_Latchstatus_B 3;
BA_ "GenSigStartValue" SG_ 627 OCC_PP_Latchstatus_B 6;
BA_ "GenSigSwitchedByIgnition" SG_ 627 OCC_PP_Latchstatus_B 0;
BA_ "Fehlerwert" SG_ 627 OCC_PP_Latchstatus_B 7;
BA_ "GenSigSendType" SG_ 627 OCC_PP_Status_A 3;
BA_ "GenSigStartValue" SG_ 627 OCC_PP_Status_A 2;
BA_ "GenSigSwitchedByIgnition" SG_ 627 OCC_PP_Status_A 0;
BA_ "Fehlerwert" SG_ 627 OCC_PP_Status_A 3;
BA_ "GenSigSendType" SG_ 627 OCC_PP_Status_B 3;
BA_ "GenSigStartValue" SG_ 627 OCC_PP_Status_B 2;
BA_ "GenSigSwitchedByIgnition" SG_ 627 OCC_PP_Status_B 0;
BA_ "Fehlerwert" SG_ 627 OCC_PP_Status_B 3;
BA_ "GenSigSendType" SG_ 627 OCC_Status_EoHVL 0;
BA_ "GenSigSwitchedByIgnition" SG_ 627 OCC_Status_EoHVL 0;
BA_ "Fehlerwert" SG_ 627 OCC_Status_EoHVL 3;
BA_ "GenSigSendType" SG_ 627 OCC_Status_Spgfreiheit 0;
BA_ "GenSigSwitchedByIgnition" SG_ 627 OCC_Status_Spgfreiheit 0;
BA_ "Fehlerwert" SG_ 627 OCC_Status_Spgfreiheit 3;
BA_ "GenSigSendType" SG_ 627 OCC_Stecker_Status 0;
BA_ "GenSigSwitchedByIgnition" SG_ 627 OCC_Stecker_Status 0;
BA_ "Fehlerwert" SG_ 627 OCC_Stecker_Status 3;
BA_ "GenSigSendType" SG_ 627 OCC_Temp_Sensor_Fehlerstatus_AC 3;
BA_ "GenSigSwitchedByIgnition" SG_ 627 OCC_Temp_Sensor_Fehlerstatus_AC 0;
BA_ "GenSigSendType" SG_ 627 OCC_Temp_Sensor_Fehlerstatus_DC 3;
BA_ "GenSigSwitchedByIgnition" SG_ 627 OCC_Temp_Sensor_Fehlerstatus_DC 0;
BA_ "GenSigSendType" SG_ 627 OCC_Temp_Sensor_Status 0;
BA_ "GenSigSwitchedByIgnition" SG_ 627 OCC_Temp_Sensor_Status 0;
BA_ "GenSigSendType" SG_ 2463978709 OCC_CP_Fehlerstatus_A 3;
BA_ "GenSigStartValue" SG_ 2463978709 OCC_CP_Fehlerstatus_A 4;
BA_ "GenSigSwitchedByIgnition" SG_ 2463978709 OCC_CP_Fehlerstatus_A 0;
BA_ "GenSigSendType" SG_ 2463978709 OCC_CP_Fehlerstatus_B 3;
BA_ "GenSigStartValue" SG_ 2463978709 OCC_CP_Fehlerstatus_B 4;
BA_ "GenSigSwitchedByIgnition" SG_ 2463978709 OCC_CP_Fehlerstatus_B 0;
BA_ "GenSigSendType" SG_ 2463978709 OCC_CP_Frequenz_A 3;
BA_ "GenSigStartValue" SG_ 2463978709 OCC_CP_Frequenz_A 254;
BA_ "GenSigSwitchedByIgnition" SG_ 2463978709 OCC_CP_Frequenz_A 0;
BA_ "Fehlerwert" SG_ 2463978709 OCC_CP_Frequenz_A 255;
BA_ "GenSigSendType" SG_ 2463978709 OCC_CP_Frequenz_B 3;
BA_ "GenSigStartValue" SG_ 2463978709 OCC_CP_Frequenz_B 254;
BA_ "GenSigSwitchedByIgnition" SG_ 2463978709 OCC_CP_Frequenz_B 0;
BA_ "Fehlerwert" SG_ 2463978709 OCC_CP_Frequenz_B 255;
BA_ "GenSigSendType" SG_ 2463978709 OCC_CP_Spannung_A 3;
BA_ "GenSigStartValue" SG_ 2463978709 OCC_CP_Spannung_A 510;
BA_ "GenSigSwitchedByIgnition" SG_ 2463978709 OCC_CP_Spannung_A 0;
BA_ "Fehlerwert" SG_ 2463978709 OCC_CP_Spannung_A 511;
BA_ "GenSigSendType" SG_ 2463978709 OCC_CP_Spannung_B 3;
BA_ "GenSigStartValue" SG_ 2463978709 OCC_CP_Spannung_B 510;
BA_ "GenSigSwitchedByIgnition" SG_ 2463978709 OCC_CP_Spannung_B 0;
BA_ "Fehlerwert" SG_ 2463978709 OCC_CP_Spannung_B 511;
BA_ "GenSigSendType" SG_ 2463978709 OCC_CP_Tastgrad_A 3;
BA_ "GenSigStartValue" SG_ 2463978709 OCC_CP_Tastgrad_A 1022;
BA_ "GenSigSwitchedByIgnition" SG_ 2463978709 OCC_CP_Tastgrad_A 0;
BA_ "Fehlerwert" SG_ 2463978709 OCC_CP_Tastgrad_A 1023;
BA_ "GenSigSendType" SG_ 2463978709 OCC_CP_Tastgrad_B 3;
BA_ "GenSigStartValue" SG_ 2463978709 OCC_CP_Tastgrad_B 1022;
BA_ "GenSigSwitchedByIgnition" SG_ 2463978709 OCC_CP_Tastgrad_B 0;
BA_ "Fehlerwert" SG_ 2463978709 OCC_CP_Tastgrad_B 1023;
BA_ "GenSigSendType" SG_ 2463978709 OCC_DC_MaxStrom 3;
BA_ "GenSigStartValue" SG_ 2463978709 OCC_DC_MaxStrom 2046;
BA_ "GenSigSwitchedByIgnition" SG_ 2463978709 OCC_DC_MaxStrom 0;
BA_ "Fehlerwert" SG_ 2463978709 OCC_DC_MaxStrom 2047;
BA_ "GenSigSendType" SG_ 2463978709 OCC_Derating_Temperatur 0;
BA_ "GenSigSwitchedByIgnition" SG_ 2463978709 OCC_Derating_Temperatur 0;
BA_ "GenSigSendType" SG_ 2463978709 OCC_Fehlerzustand 0;
BA_ "GenSigSwitchedByIgnition" SG_ 2463978709 OCC_Fehlerzustand 0;
BA_ "GenSigSendType" SG_ 2463978709 OCC_Ist_Wirkungsgrad 0;
BA_ "GenSigStartValue" SG_ 2463978709 OCC_Ist_Wirkungsgrad 126;
BA_ "GenSigSwitchedByIgnition" SG_ 2463978709 OCC_Ist_Wirkungsgrad 0;
BA_ "Fehlerwert" SG_ 2463978709 OCC_Ist_Wirkungsgrad 127;
BA_ "GenSigSendType" SG_ 2463978709 OCC_Kuehltemperatur 0;
BA_ "GenSigStartValue" SG_ 2463978709 OCC_Kuehltemperatur 254;
BA_ "GenSigSwitchedByIgnition" SG_ 2463978709 OCC_Kuehltemperatur 0;
BA_ "Fehlerwert" SG_ 2463978709 OCC_Kuehltemperatur 255;
BA_ "GenSigSendType" SG_ 2463978709 OCC_Ladest_Entriegelungs_Verbot 3;
BA_ "GenSigStartValue" SG_ 2463978709 OCC_Ladest_Entriegelungs_Verbot 6;
BA_ "GenSigSwitchedByIgnition" SG_ 2463978709 OCC_Ladest_Entriegelungs_Verbot 0;
BA_ "Fehlerwert" SG_ 2463978709 OCC_Ladest_Entriegelungs_Verbot 7;
BA_ "GenSigSendType" SG_ 2463978709 OCC_Netzfrequenz_EVU 0;
BA_ "GenSigStartValue" SG_ 2463978709 OCC_Netzfrequenz_EVU 510;
BA_ "GenSigSwitchedByIgnition" SG_ 2463978709 OCC_Netzfrequenz_EVU 0;
BA_ "Fehlerwert" SG_ 2463978709 OCC_Netzfrequenz_EVU 511;
BA_ "GenSigSendType" SG_ 2463978709 OCC_PP_Fehlerstatus_A 3;
BA_ "GenSigStartValue" SG_ 2463978709 OCC_PP_Fehlerstatus_A 8;
BA_ "GenSigSwitchedByIgnition" SG_ 2463978709 OCC_PP_Fehlerstatus_A 0;
BA_ "GenSigSendType" SG_ 2463978709 OCC_PP_Fehlerstatus_B 3;
BA_ "GenSigStartValue" SG_ 2463978709 OCC_PP_Fehlerstatus_B 8;
BA_ "GenSigSwitchedByIgnition" SG_ 2463978709 OCC_PP_Fehlerstatus_B 0;
BA_ "GenSigSendType" SG_ 2463978709 OCC_PP_Max_Strom_A 3;
BA_ "GenSigStartValue" SG_ 2463978709 OCC_PP_Max_Strom_A 8;
BA_ "GenSigSwitchedByIgnition" SG_ 2463978709 OCC_PP_Max_Strom_A 0;
BA_ "Fehlerwert" SG_ 2463978709 OCC_PP_Max_Strom_A 9;
BA_ "GenSigSendType" SG_ 2463978709 OCC_PP_Max_Strom_B 3;
BA_ "GenSigStartValue" SG_ 2463978709 OCC_PP_Max_Strom_B 8;
BA_ "GenSigSwitchedByIgnition" SG_ 2463978709 OCC_PP_Max_Strom_B 0;
BA_ "Fehlerwert" SG_ 2463978709 OCC_PP_Max_Strom_B 9;
BA_ "GenSigSendType" SG_ 2463978709 OCC_RtmWarnLadeKommunikation 0;
BA_ "GenSigSwitchedByIgnition" SG_ 2463978709 OCC_RtmWarnLadeKommunikation 0;
BA_ "GenSigSendType" SG_ 2463978709 OCC_StatusVerEntriegelungAktor_A 3;
BA_ "GenSigStartValue" SG_ 2463978709 OCC_StatusVerEntriegelungAktor_A 6;
BA_ "GenSigSwitchedByIgnition" SG_ 2463978709 OCC_StatusVerEntriegelungAktor_A 0;
BA_ "Fehlerwert" SG_ 2463978709 OCC_StatusVerEntriegelungAktor_A 7;
BA_ "GenSigSendType" SG_ 2463978709 OCC_StatusVerEntriegelungAktor_B 3;
BA_ "GenSigStartValue" SG_ 2463978709 OCC_StatusVerEntriegelungAktor_B 6;
BA_ "GenSigSwitchedByIgnition" SG_ 2463978709 OCC_StatusVerEntriegelungAktor_B 0;
BA_ "Fehlerwert" SG_ 2463978709 OCC_StatusVerEntriegelungAktor_B 7;
BA_ "GenSigSendType" SG_ 2463978709 OCC_SteckerEntriegelung_Verbot_A 3;
BA_ "GenSigStartValue" SG_ 2463978709 OCC_SteckerEntriegelung_Verbot_A 3;
BA_ "GenSigSwitchedByIgnition" SG_ 2463978709 OCC_SteckerEntriegelung_Verbot_A 0;
BA_ "GenSigSendType" SG_ 2463978709 OCC_SteckerEntriegelung_Verbot_B 3;
BA_ "GenSigStartValue" SG_ 2463978709 OCC_SteckerEntriegelung_Verbot_B 3;
BA_ "GenSigSwitchedByIgnition" SG_ 2463978709 OCC_SteckerEntriegelung_Verbot_B 0;
BA_ "GenSigSendType" SG_ 2463978709 OCC_Temp_Ladedose_A_AC 0;
BA_ "GenSigStartValue" SG_ 2463978709 OCC_Temp_Ladedose_A_AC 254;
BA_ "GenSigSwitchedByIgnition" SG_ 2463978709 OCC_Temp_Ladedose_A_AC 0;
BA_ "Fehlerwert" SG_ 2463978709 OCC_Temp_Ladedose_A_AC 255;
BA_ "GenSigSendType" SG_ 2463978709 OCC_Temp_Ladedose_A_DC_minus 0;
BA_ "GenSigStartValue" SG_ 2463978709 OCC_Temp_Ladedose_A_DC_minus 254;
BA_ "GenSigSwitchedByIgnition" SG_ 2463978709 OCC_Temp_Ladedose_A_DC_minus 0;
BA_ "Fehlerwert" SG_ 2463978709 OCC_Temp_Ladedose_A_DC_minus 255;
BA_ "GenSigSendType" SG_ 2463978709 OCC_Temp_Ladedose_A_DC_plus 0;
BA_ "GenSigStartValue" SG_ 2463978709 OCC_Temp_Ladedose_A_DC_plus 254;
BA_ "GenSigSwitchedByIgnition" SG_ 2463978709 OCC_Temp_Ladedose_A_DC_plus 0;
BA_ "Fehlerwert" SG_ 2463978709 OCC_Temp_Ladedose_A_DC_plus 255;
BA_ "GenSigSendType" SG_ 2463978709 OCC_U_istAC_Netz_L1 0;
BA_ "GenSigStartValue" SG_ 2463978709 OCC_U_istAC_Netz_L1 510;
BA_ "GenSigSwitchedByIgnition" SG_ 2463978709 OCC_U_istAC_Netz_L1 0;
BA_ "Fehlerwert" SG_ 2463978709 OCC_U_istAC_Netz_L1 511;
BA_ "GenSigSendType" SG_ 2463978709 OCC_U_istAC_Netz_L2 0;
BA_ "GenSigStartValue" SG_ 2463978709 OCC_U_istAC_Netz_L2 510;
BA_ "GenSigSwitchedByIgnition" SG_ 2463978709 OCC_U_istAC_Netz_L2 0;
BA_ "Fehlerwert" SG_ 2463978709 OCC_U_istAC_Netz_L2 511;
BA_ "GenSigSendType" SG_ 2463978709 OCC_U_istAC_Netz_L3 0;
BA_ "GenSigStartValue" SG_ 2463978709 OCC_U_istAC_Netz_L3 510;
BA_ "GenSigSwitchedByIgnition" SG_ 2463978709 OCC_U_istAC_Netz_L3 0;
BA_ "Fehlerwert" SG_ 2463978709 OCC_U_istAC_Netz_L3 511;
BA_ "GenSigSendType" SG_ 2463978709 OCC_Verriegelung_Status_A 3;
BA_ "GenSigStartValue" SG_ 2463978709 OCC_Verriegelung_Status_A 6;
BA_ "GenSigSwitchedByIgnition" SG_ 2463978709 OCC_Verriegelung_Status_A 0;
BA_ "Fehlerwert" SG_ 2463978709 OCC_Verriegelung_Status_A 7;
BA_ "GenSigSendType" SG_ 2463978709 OCC_Verriegelung_Status_B 3;
BA_ "GenSigStartValue" SG_ 2463978709 OCC_Verriegelung_Status_B 6;
BA_ "GenSigSwitchedByIgnition" SG_ 2463978709 OCC_Verriegelung_Status_B 0;
BA_ "Fehlerwert" SG_ 2463978709 OCC_Verriegelung_Status_B 7;
BA_ "GenSigSendType" SG_ 2463978709 OCC_Warnzustand 0;
BA_ "GenSigSwitchedByIgnition" SG_ 2463978709 OCC_Warnzustand 0;
BA_ "GenSigSendType" SG_ 2589283656 ORU_EM_Anfrage_Flashdauer 3;
BA_ "GenSigSwitchedByIgnition" SG_ 2589283656 ORU_EM_Anfrage_Flashdauer 0;
BA_ "GenSigSendType" SG_ 2589283656 ORU_EM_Anfrage_freigegebeneNetze 3;
BA_ "GenSigSwitchedByIgnition" SG_ 2589283656 ORU_EM_Anfrage_freigegebeneNetze 0;
BA_ "GenSigSendType" SG_ 2589283656 ORU_EM_Anfrage_Stromaufnahme 3;
BA_ "GenSigSwitchedByIgnition" SG_ 2589283656 ORU_EM_Anfrage_Stromaufnahme 0;
BA_ "GenSigSendType" SG_ 2589283656 ORU_Status 3;
BA_ "GenSigSwitchedByIgnition" SG_ 2589283656 ORU_Status 0;
BA_ "GenSigSendType" SG_ 2589283656 ORU_Warnung 3;
BA_ "GenSigSwitchedByIgnition" SG_ 2589283656 ORU_Warnung 0;
BA_ "GenSigSendType" SG_ 2527679741 PAO_OFF_Status 0;
BA_ "GenSigSwitchedByIgnition" SG_ 2527679741 PAO_OFF_Status 0;
BA_ "GenSigSendType" SG_ 2527679741 PAO_ON_Status 0;
BA_ "GenSigSwitchedByIgnition" SG_ 2527679741 PAO_ON_Status 0;
BA_ "GenSigSendType" SG_ 2527679741 PAO_Status_01_BZ 0;
BA_ "GenSigFuncType" SG_ 2527679741 PAO_Status_01_BZ 1;
BA_ "GenSigSwitchedByIgnition" SG_ 2527679741 PAO_Status_01_BZ 0;
BA_ "GenSigSendType" SG_ 2527679741 PAO_Status_01_CRC 0;
BA_ "GenSigFuncType" SG_ 2527679741 PAO_Status_01_CRC 2;
BA_ "GenSigSwitchedByIgnition" SG_ 2527679741 PAO_Status_01_CRC 0;
BA_ "GenSigSendType" SG_ 2527679741 PAO_Status_Reserve_Byte3 0;
BA_ "GenSigSwitchedByIgnition" SG_ 2527679741 PAO_Status_Reserve_Byte3 0;
BA_ "GenSigSendType" SG_ 518 IPA_TPA_Abbruch 0;
BA_ "GenSigSwitchedByIgnition" SG_ 518 IPA_TPA_Abbruch 0;
BA_ "GenSigSendType" SG_ 518 IPA_TPA_Fehler 0;
BA_ "GenSigSwitchedByIgnition" SG_ 518 IPA_TPA_Fehler 0;
BA_ "GenSigSendType" SG_ 518 IPA_TPA_Remote 0;
BA_ "GenSigSwitchedByIgnition" SG_ 518 IPA_TPA_Remote 0;
BA_ "GenSigSendType" SG_ 518 IPA_TPA_Remote_Anf 0;
BA_ "GenSigSwitchedByIgnition" SG_ 518 IPA_TPA_Remote_Anf 0;
BA_ "GenSigSendType" SG_ 518 IPA_TPA_Status 0;
BA_ "GenSigStartValue" SG_ 518 IPA_TPA_Status 1;
BA_ "GenSigSwitchedByIgnition" SG_ 518 IPA_TPA_Status 0;
BA_ "GenSigSendType" SG_ 518 Parken_aktives_System 0;
BA_ "GenSigSendType" SG_ 518 Parken_Anforderung_HMS 0;
BA_ "GenSigSwitchedByIgnition" SG_ 518 Parken_Anforderung_HMS 0;
BA_ "GenSigSendType" SG_ 518 Parken_Anhalteweg_Anf 0;
BA_ "GenSigStartValue" SG_ 518 Parken_Anhalteweg_Anf 1022;
BA_ "GenSigSwitchedByIgnition" SG_ 518 Parken_Anhalteweg_Anf 0;
BA_ "Fehlerwert" SG_ 518 Parken_Anhalteweg_Anf 1023;
BA_ "GenSigSendType" SG_ 518 Parken_beibehalten 0;
BA_ "GenSigStartValue" SG_ 518 Parken_beibehalten 2;
BA_ "GenSigSwitchedByIgnition" SG_ 518 Parken_beibehalten 0;
BA_ "Fehlerwert" SG_ 518 Parken_beibehalten 3;
BA_ "GenSigSendType" SG_ 518 Parken_BKD_Anf 0;
BA_ "GenSigStartValue" SG_ 518 Parken_BKD_Anf 14;
BA_ "GenSigSwitchedByIgnition" SG_ 518 Parken_BKD_Anf 0;
BA_ "Fehlerwert" SG_ 518 Parken_BKD_Anf 15;
BA_ "GenSigSendType" SG_ 518 Parken_Blinker_li_Anf 0;
BA_ "GenSigSwitchedByIgnition" SG_ 518 Parken_Blinker_li_Anf 0;
BA_ "GenSigSendType" SG_ 518 Parken_Blinker_re_Anf 0;
BA_ "GenSigSwitchedByIgnition" SG_ 518 Parken_Blinker_re_Anf 0;
BA_ "GenSigSendType" SG_ 518 Parken_erhoehtes_Moment 0;
BA_ "GenSigSwitchedByIgnition" SG_ 518 Parken_erhoehtes_Moment 0;
BA_ "GenSigSendType" SG_ 518 Parken_Fahrstufenwunsch 0;
BA_ "GenSigSendType" SG_ 518 Parken_max_Beschleunigung 0;
BA_ "GenSigStartValue" SG_ 518 Parken_max_Beschleunigung 122;
BA_ "GenSigSwitchedByIgnition" SG_ 518 Parken_max_Beschleunigung 0;
BA_ "Fehlerwert" SG_ 518 Parken_max_Beschleunigung 127;
BA_ "GenSigSendType" SG_ 518 Parken_max_Geschwindigkeit 0;
BA_ "GenSigStartValue" SG_ 518 Parken_max_Geschwindigkeit 251;
BA_ "GenSigSwitchedByIgnition" SG_ 518 Parken_max_Geschwindigkeit 0;
BA_ "Fehlerwert" SG_ 518 Parken_max_Geschwindigkeit 255;
BA_ "GenSigSendType" SG_ 518 Parken_Notstopp_Anf 0;
BA_ "GenSigSwitchedByIgnition" SG_ 518 Parken_Notstopp_Anf 0;
BA_ "GenSigSendType" SG_ 518 Parken_Prefill_Anf 0;
BA_ "GenSigSwitchedByIgnition" SG_ 518 Parken_Prefill_Anf 0;
BA_ "GenSigSendType" SG_ 518 Parken_QFK_AnfStat 0;
BA_ "GenSigStartValue" SG_ 518 Parken_QFK_AnfStat 1;
BA_ "GenSigSendType" SG_ 518 Parken_QFK_Art1 0;
BA_ "GenSigSendType" SG_ 518 Parken_QFK_Art2 0;
BA_ "GenSigSendType" SG_ 518 Parken_QFK_KruemmSoll 0;
BA_ "GenSigSendType" SG_ 518 Parken_QFK_KruemmSoll_VZ 0;
BA_ "GenSigSendType" SG_ 518 Parken_QFK_Signal1 0;
BA_ "GenSigSendType" SG_ 518 Parken_QFK_Signal2 0;
BA_ "GenSigSendType" SG_ 518 Parken_QFK_Spuerb 0;
BA_ "GenSigSendType" SG_ 518 Parken_Soll_Anhalteweg_Anf 0;
BA_ "GenSigStartValue" SG_ 518 Parken_Soll_Anhalteweg_Anf 1022;
BA_ "GenSigSwitchedByIgnition" SG_ 518 Parken_Soll_Anhalteweg_Anf 0;
BA_ "Fehlerwert" SG_ 518 Parken_Soll_Anhalteweg_Anf 1023;
BA_ "GenSigSendType" SG_ 518 Parken_Sollbeschleunigung 0;
BA_ "GenSigSendType" SG_ 518 Parken_Status_IPA_TSK 0;
BA_ "GenSigStartValue" SG_ 518 Parken_Status_IPA_TSK 1;
BA_ "GenSigSwitchedByIgnition" SG_ 518 Parken_Status_IPA_TSK 0;
BA_ "GenSigSendType" SG_ 518 Parken_Verz_Anf 0;
BA_ "GenSigStartValue" SG_ 518 Parken_Verz_Anf 126;
BA_ "GenSigSwitchedByIgnition" SG_ 518 Parken_Verz_Anf 0;
BA_ "GenSigSendType" SG_ 518 Parken_Verz_Anf_ASIL 0;
BA_ "GenSigSwitchedByIgnition" SG_ 518 Parken_Verz_Anf_ASIL 0;
BA_ "GenSigSendType" SG_ 518 Parken_Warnruck_Anf 0;
BA_ "GenSigSwitchedByIgnition" SG_ 518 Parken_Warnruck_Anf 0;
BA_ "GenSigSendType" SG_ 518 Parken_Warnruckeln_Anf 0;
BA_ "GenSigSwitchedByIgnition" SG_ 518 Parken_Warnruckeln_Anf 0;
BA_ "GenSigSendType" SG_ 2527679685 PDC_ASM_Data_1 0;
BA_ "GenSigSendType" SG_ 2527679685 PDC_ASM_Data_2 0;
BA_ "GenSigSendType" SG_ 2527679685 PDC_ASM_Data_3 0;
BA_ "GenSigSendType" SG_ 2527679685 PDC_ASM_Data_4 0;
BA_ "GenSigSendType" SG_ 2527679685 PDC_ASM_Data_5 0;
BA_ "GenSigSendType" SG_ 2527679685 PDC_ASM_Data_6 0;
BA_ "GenSigSendType" SG_ 2527679685 PDC_ASM_Ereignis 3;
BA_ "GenSigSendType" SG_ 2527679685 PDC_ASM_Zeitstempel 3;
BA_ "GenSigStartValue" SG_ 2527679685 PDC_ASM_Zeitstempel 255;
BA_ "GenSigSendType" SG_ 319 PreCrash_Anforderung_AFR 3;
BA_ "GenSigStartValue" SG_ 319 PreCrash_Anforderung_AFR 7;
BA_ "GenSigSwitchedByIgnition" SG_ 319 PreCrash_Anforderung_AFR 0;
BA_ "GenSigSendType" SG_ 319 PreCrash_BFS_KSV_verfahren 3;
BA_ "GenSigSwitchedByIgnition" SG_ 319 PreCrash_BFS_KSV_verfahren 0;
BA_ "GenSigSendType" SG_ 319 PreCrash_BFS_Laengsverstellung 3;
BA_ "GenSigSwitchedByIgnition" SG_ 319 PreCrash_BFS_Laengsverstellung 0;
BA_ "GenSigSendType" SG_ 319 PreCrash_BFS_Pneumatik_ansteuern 3;
BA_ "GenSigSwitchedByIgnition" SG_ 319 PreCrash_BFS_Pneumatik_ansteuern 0;
BA_ "GenSigSendType" SG_ 319 PreCrash_BFS_Sitzlehne_verfahren 3;
BA_ "GenSigSwitchedByIgnition" SG_ 319 PreCrash_BFS_Sitzlehne_verfahren 0;
BA_ "GenSigSendType" SG_ 319 PreCrash_Blinken 3;
BA_ "GenSigSendType" SG_ 319 PreCrash_Charisma_FahrPr 0;
BA_ "GenSigSendType" SG_ 319 PreCrash_Charisma_Status 0;
BA_ "GenSigSendType" SG_ 319 PreCrash_Fenster_schliessen 3;
BA_ "GenSigSendType" SG_ 319 PreCrash_Fo_KSV_verfahren 3;
BA_ "GenSigSwitchedByIgnition" SG_ 319 PreCrash_Fo_KSV_verfahren 0;
BA_ "GenSigSendType" SG_ 319 PreCrash_Fo_Pneumatik_ansteuern 3;
BA_ "GenSigSwitchedByIgnition" SG_ 319 PreCrash_Fo_Pneumatik_ansteuern 0;
BA_ "GenSigSendType" SG_ 319 PreCrash_Fo_Sitzlehne_verfahren 3;
BA_ "GenSigSwitchedByIgnition" SG_ 319 PreCrash_Fo_Sitzlehne_verfahren 0;
BA_ "GenSigSendType" SG_ 319 PreCrash_FS_KSV_verfahren 3;
BA_ "GenSigSwitchedByIgnition" SG_ 319 PreCrash_FS_KSV_verfahren 0;
BA_ "GenSigSendType" SG_ 319 PreCrash_FS_Laengsverstellung 3;
BA_ "GenSigSwitchedByIgnition" SG_ 319 PreCrash_FS_Laengsverstellung 0;
BA_ "GenSigSendType" SG_ 319 PreCrash_FS_Pneumatik_ansteuern 3;
BA_ "GenSigSwitchedByIgnition" SG_ 319 PreCrash_FS_Pneumatik_ansteuern 0;
BA_ "GenSigSendType" SG_ 319 PreCrash_FS_Sitzlehne_verfahren 3;
BA_ "GenSigSwitchedByIgnition" SG_ 319 PreCrash_FS_Sitzlehne_verfahren 0;
BA_ "GenSigSendType" SG_ 319 PreCrash_Schiebedach_schliessen 3;
BA_ "GenSigSendType" SG_ 319 PreCrash_Tueren_Verriegeln 3;
BA_ "GenSigSwitchedByIgnition" SG_ 319 PreCrash_Tueren_Verriegeln 0;
BA_ "GenSigSendType" SG_ 319 SC_PreCrash_LED 3;
BA_ "GenSigSwitchedByIgnition" SG_ 319 SC_PreCrash_LED 0;
BA_ "GenSigSendType" SG_ 319 SC_PreCrash_Texte 3;
BA_ "GenSigSwitchedByIgnition" SG_ 319 SC_PreCrash_Texte 0;
BA_ "GenSigSendType" SG_ 319 SC_PreCrash_Warnung 3;
BA_ "GenSigSwitchedByIgnition" SG_ 319 SC_PreCrash_Warnung 0;
BA_ "GenSigSendType" SG_ 319 SC_PreSense_FCWP 3;
BA_ "GenSigSwitchedByIgnition" SG_ 319 SC_PreSense_FCWP 0;
BA_ "GenSigSendType" SG_ 1122 PSD_Abzweigerichtung 0;
BA_ "GenSigSwitchedByIgnition" SG_ 1122 PSD_Abzweigerichtung 0;
BA_ "GenSigSendType" SG_ 1122 PSD_Abzweigewinkel 0;
BA_ "GenSigSwitchedByIgnition" SG_ 1122 PSD_Abzweigewinkel 0;
BA_ "GenSigSendType" SG_ 1122 PSD_ADAS_Qualitaet 0;
BA_ "GenSigSendType" SG_ 1122 PSD_Anfangskruemmung 0;
BA_ "GenSigSwitchedByIgnition" SG_ 1122 PSD_Anfangskruemmung 0;
BA_ "GenSigSendType" SG_ 1122 PSD_Anfangskruemmung_Vorz 0;
BA_ "GenSigSwitchedByIgnition" SG_ 1122 PSD_Anfangskruemmung_Vorz 0;
BA_ "GenSigSendType" SG_ 1122 PSD_Bebauung 0;
BA_ "GenSigSendType" SG_ 1122 PSD_Endkruemmung 0;
BA_ "GenSigSendType" SG_ 1122 PSD_Endkruemmung_Vorz 0;
BA_ "GenSigSendType" SG_ 1122 PSD_Fahrspuren_Anzahl 0;
BA_ "GenSigStartValue" SG_ 1122 PSD_Fahrspuren_Anzahl 1;
BA_ "GenSigSwitchedByIgnition" SG_ 1122 PSD_Fahrspuren_Anzahl 0;
BA_ "GenSigSendType" SG_ 1122 PSD_Geradester_Pfad 0;
BA_ "GenSigSendType" SG_ 1122 PSD_Idenditaets_ID 0;
BA_ "Fehlerwert" SG_ 1122 PSD_Idenditaets_ID 1;
BA_ "GenSigSendType" SG_ 1122 PSD_Rampe 0;
BA_ "GenSigSendType" SG_ 1122 PSD_Segment_ID 0;
BA_ "GenSigSendType" SG_ 1122 PSD_Segment_Komplett 0;
BA_ "GenSigSwitchedByIgnition" SG_ 1122 PSD_Segment_Komplett 0;
BA_ "GenSigSendType" SG_ 1122 PSD_Segmentlaenge 0;
BA_ "GenSigSendType" SG_ 1122 PSD_Strassenkategorie 0;
BA_ "GenSigStartValue" SG_ 1122 PSD_Strassenkategorie 7;
BA_ "GenSigSwitchedByIgnition" SG_ 1122 PSD_Strassenkategorie 0;
BA_ "GenSigSendType" SG_ 1122 PSD_Vorgaenger_Segment_ID 0;
BA_ "GenSigSendType" SG_ 1122 PSD_wahrscheinlichster_Pfad 0;
BA_ "GenSigSendType" SG_ 1123 PSD_Attribut_1_ID 0;
BA_ "GenSigSendType" SG_ 1123 PSD_Attribut_1_Offset 0;
BA_ "GenSigSendType" SG_ 1123 PSD_Attribut_1_Wert 0;
BA_ "GenSigSendType" SG_ 1123 PSD_Attribut_2_ID 0;
BA_ "GenSigSendType" SG_ 1123 PSD_Attribut_2_Offset 0;
BA_ "GenSigSendType" SG_ 1123 PSD_Attribut_2_Wert 0;
BA_ "GenSigSendType" SG_ 1123 PSD_Attribut_Segment_ID_05 0;
BA_ "Fehlerwert" SG_ 1123 PSD_Attribut_Segment_ID_05 1;
BA_ "GenSigSendType" SG_ 1123 PSD_Attribute_Komplett_05 0;
BA_ "GenSigSendType" SG_ 1123 PSD_Pos_Fahrspur 0;
BA_ "GenSigSendType" SG_ 1123 PSD_Pos_Fehler_Laengsrichtung 0;
BA_ "GenSigSendType" SG_ 1123 PSD_Pos_Inhibitzeit 0;
BA_ "GenSigSendType" SG_ 1123 PSD_Pos_Segment_ID 0;
BA_ "GenSigSendType" SG_ 1123 PSD_Pos_Segmentlaenge 0;
BA_ "GenSigSendType" SG_ 1123 PSD_Pos_Standort_Eindeutig 0;
BA_ "GenSigSwitchedByIgnition" SG_ 1123 PSD_Pos_Standort_Eindeutig 0;
BA_ "GenSigSendType" SG_ 1124 PSD_06_Mux 0;
BA_ "NWM-WakeupAllowed" SG_ 1124 PSD_06_Mux 1;
BA_ "GenSigSwitchedByIgnition" SG_ 1124 PSD_06_Mux 0;
BA_ "Fehlerwert" SG_ 1124 PSD_Attribut_Segment_ID 1;
BA_ "GenSigSwitchedByIgnition" SG_ 1124 PSD_Attribute_Komplett_06 0;
BA_ "GenSigStartValue" SG_ 1124 PSD_Ges_Typ 3;
BA_ "GenSigSwitchedByIgnition" SG_ 1124 PSD_Ges_Typ 0;
BA_ "GenSigSwitchedByIgnition" SG_ 1124 PSD_Steigung_1_Attribute_kompl 0;
BA_ "Fehlerwert" SG_ 1124 PSD_Steigung_1_Segment_ID 1;
BA_ "GenSigSwitchedByIgnition" SG_ 1124 PSD_Steigung_2_Attribute_kompl 0;
BA_ "Fehlerwert" SG_ 1124 PSD_Steigung_2_Segment_ID 1;
BA_ "GenSigSendType" SG_ 591 RDR1_Blindheit_erkannt 0;
BA_ "GenSigSendType" SG_ 591 RDR1_Obj_01_ax_StdA 0;
BA_ "GenSigStartValue" SG_ 591 RDR1_Obj_01_ax_StdA 63;
BA_ "GenSigSwitchedByIgnition" SG_ 591 RDR1_Obj_01_ax_StdA 0;
BA_ "GenSigSendType" SG_ 591 RDR1_Obj_01_ax_v 0;
BA_ "GenSigStartValue" SG_ 591 RDR1_Obj_01_ax_v 255;
BA_ "GenSigSwitchedByIgnition" SG_ 591 RDR1_Obj_01_ax_v 0;
BA_ "GenSigSendType" SG_ 591 RDR1_Obj_01_dx_StdA 0;
BA_ "GenSigStartValue" SG_ 591 RDR1_Obj_01_dx_StdA 127;
BA_ "GenSigSwitchedByIgnition" SG_ 591 RDR1_Obj_01_dx_StdA 0;
BA_ "GenSigSendType" SG_ 591 RDR1_Obj_01_dx_v 0;
BA_ "GenSigSendType" SG_ 591 RDR1_Obj_01_dy_StdA 0;
BA_ "GenSigStartValue" SG_ 591 RDR1_Obj_01_dy_StdA 127;
BA_ "GenSigSendType" SG_ 591 RDR1_Obj_01_dy_v 0;
BA_ "GenSigStartValue" SG_ 591 RDR1_Obj_01_dy_v 512;
BA_ "GenSigSendType" SG_ 591 RDR1_Obj_01_Nummer 0;
BA_ "GenSigSendType" SG_ 591 RDR1_Obj_01_vx_StdA 0;
BA_ "GenSigStartValue" SG_ 591 RDR1_Obj_01_vx_StdA 127;
BA_ "GenSigSwitchedByIgnition" SG_ 591 RDR1_Obj_01_vx_StdA 0;
BA_ "GenSigSendType" SG_ 591 RDR1_Obj_01_vx_v 0;
BA_ "GenSigStartValue" SG_ 591 RDR1_Obj_01_vx_v 512;
BA_ "GenSigSendType" SG_ 591 RDR1_Obj_02_dx_v 0;
BA_ "GenSigSendType" SG_ 591 RDR1_Obj_02_dy_v 0;
BA_ "GenSigStartValue" SG_ 591 RDR1_Obj_02_dy_v 512;
BA_ "GenSigSendType" SG_ 591 RDR1_Obj_02_Nummer 0;
BA_ "GenSigSendType" SG_ 591 RDR1_Obj_02_vx_v 0;
BA_ "GenSigStartValue" SG_ 591 RDR1_Obj_02_vx_v 512;
BA_ "GenSigSendType" SG_ 591 RDR1_Obj_03_dx_v 0;
BA_ "GenSigSendType" SG_ 591 RDR1_Obj_03_dy_v 0;
BA_ "GenSigStartValue" SG_ 591 RDR1_Obj_03_dy_v 512;
BA_ "GenSigSendType" SG_ 591 RDR1_Obj_03_Nummer 0;
BA_ "GenSigSendType" SG_ 591 RDR1_Obj_03_vx_v 0;
BA_ "GenSigStartValue" SG_ 591 RDR1_Obj_03_vx_v 512;
BA_ "GenSigSendType" SG_ 591 RDR1_Obj_04_dx_v 0;
BA_ "GenSigSendType" SG_ 591 RDR1_Obj_04_dy_v 0;
BA_ "GenSigStartValue" SG_ 591 RDR1_Obj_04_dy_v 512;
BA_ "GenSigSendType" SG_ 591 RDR1_Obj_04_Nummer 0;
BA_ "GenSigSendType" SG_ 591 RDR1_Obj_04_vx_v 0;
BA_ "GenSigStartValue" SG_ 591 RDR1_Obj_04_vx_v 512;
BA_ "GenSigSendType" SG_ 591 RDR1_Obj_05_dx_v 0;
BA_ "GenSigSendType" SG_ 591 RDR1_Obj_05_dy_v 0;
BA_ "GenSigStartValue" SG_ 591 RDR1_Obj_05_dy_v 512;
BA_ "GenSigSendType" SG_ 591 RDR1_Obj_05_Nummer 0;
BA_ "GenSigSendType" SG_ 591 RDR1_Obj_05_vx_v 0;
BA_ "GenSigStartValue" SG_ 591 RDR1_Obj_05_vx_v 512;
BA_ "GenSigSendType" SG_ 591 RDR1_Obj_06_dx_v 0;
BA_ "GenSigSendType" SG_ 591 RDR1_Obj_06_dy_v 0;
BA_ "GenSigStartValue" SG_ 591 RDR1_Obj_06_dy_v 512;
BA_ "GenSigSendType" SG_ 591 RDR1_Obj_06_Nummer 0;
BA_ "GenSigSendType" SG_ 591 RDR1_Obj_06_vx_v 0;
BA_ "GenSigStartValue" SG_ 591 RDR1_Obj_06_vx_v 512;
BA_ "GenSigSendType" SG_ 591 RDR1_Objekte_02_Datenalter 0;
BA_ "GenSigSendType" SG_ 591 RDR1_relev_Nichtverfuegbarkeit 0;
BA_ "GenSigSendType" SG_ 591 RDR1_relevanter_Fehler 0;
BA_ "GenSigSendType" SG_ 591 RDR1_Verkehrssinn 0;
BA_REL_ "GenSigTimeoutTime" BU_SG_REL_ Airbag SG_ 2527679686 MRR_HR_ASM_Ereignis 5000;
BA_REL_ "GenSigTimeoutTime" BU_SG_REL_ Airbag SG_ 2527679686 MRR_HR_ASM_Zeitstempel 5000;
BA_REL_ "GenSigTimeoutTime" BU_SG_REL_ Airbag SG_ 2527679686 MRR_HR_ASM_Data_1 5000;
BA_REL_ "GenSigTimeoutTime" BU_SG_REL_ Airbag SG_ 2527679686 MRR_HR_ASM_Data_2 5000;
BA_REL_ "GenSigTimeoutTime" BU_SG_REL_ Airbag SG_ 2527679686 MRR_HR_ASM_Data_3 5000;
BA_REL_ "GenSigTimeoutTime" BU_SG_REL_ Airbag SG_ 2527679686 MRR_HR_ASM_Data_4 5000;
BA_REL_ "GenSigTimeoutTime" BU_SG_REL_ Airbag SG_ 2527679686 MRR_HR_ASM_Data_5 5000;
BA_REL_ "GenSigTimeoutTime" BU_SG_REL_ Airbag SG_ 2527679686 MRR_HR_ASM_Data_6 5000;
BA_REL_ "GenSigTimeoutTime" BU_SG_REL_ Airbag SG_ 2600468604 NM_EMotor_01_NM_State 2000;
BA_REL_ "GenSigTimeoutTime" BU_SG_REL_ Airbag SG_ 2600468496 NM_Gateway_NM_State 2000;
BA_REL_ "GenSigTimeoutTime" BU_SG_REL_ Airbag SG_ 2600468664 NM_LE2_NM_State 2000;
BA_REL_ "GenSigTimeoutTime" BU_SG_REL_ Airbag SG_ 2600468598 NM_MO_01_NM_State 2000;
BA_REL_ "GenSigTimeoutTime" BU_SG_REL_ Airbag SG_ 2600468733 NM_Waehlhebel_NM_State 2000;
BA_REL_ "GenSigTimeoutTime" BU_SG_REL_ Airbag SG_ 2589283656 ORU_Status 5000;
BA_REL_ "GenSigTimeoutTime" BU_SG_REL_ Airbag SG_ 2527679741 PAO_Status_01_CRC 2400;
BA_REL_ "GenSigTimeoutTime" BU_SG_REL_ Airbag SG_ 2527679741 PAO_Status_01_BZ 2400;
BA_REL_ "GenSigTimeoutTime" BU_SG_REL_ Airbag SG_ 2527679741 PAO_ON_Status 2400;
BA_REL_ "GenSigTimeoutTime" BU_SG_REL_ Airbag SG_ 2527679741 PAO_OFF_Status 2400;
BA_REL_ "GenSigTimeoutTime" BU_SG_REL_ Airbag SG_ 2527679685 PDC_ASM_Ereignis 5000;
BA_REL_ "GenSigTimeoutTime" BU_SG_REL_ Airbag SG_ 2527679685 PDC_ASM_Zeitstempel 5000;
BA_REL_ "GenSigTimeoutTime" BU_SG_REL_ Airbag SG_ 2527679685 PDC_ASM_Data_1 5000;
BA_REL_ "GenSigTimeoutTime" BU_SG_REL_ Airbag SG_ 2527679685 PDC_ASM_Data_2 5000;
BA_REL_ "GenSigTimeoutTime" BU_SG_REL_ Airbag SG_ 2527679685 PDC_ASM_Data_3 5000;
BA_REL_ "GenSigTimeoutTime" BU_SG_REL_ Airbag SG_ 2527679685 PDC_ASM_Data_4 5000;
BA_REL_ "GenSigTimeoutTime" BU_SG_REL_ Airbag SG_ 2527679685 PDC_ASM_Data_5 5000;
BA_REL_ "GenSigTimeoutTime" BU_SG_REL_ Airbag SG_ 2527679685 PDC_ASM_Data_6 5000;
BA_REL_ "GenSigTimeoutTime" BU_SG_REL_ ICAS1_Gateway SG_ 1601 MO_Faktor_Momente_02 5000;
BA_REL_ "GenSigTimeoutTime" BU_SG_REL_ ICAS1_Gateway SG_ 1601 MO_Hybridfahrzeug 5000;
BA_REL_ "GenSigTimeoutTime" BU_SG_REL_ ICAS1_Gateway SG_ 1601 MO_Kraftstoffart 5000;
BA_REL_ "GenSigTimeoutTime" BU_SG_REL_ ICAS1_Gateway SG_ 339 MO_HVEM_Eskalation 2000;
BA_REL_ "GenSigTimeoutTime" BU_SG_REL_ ICAS1_Gateway SG_ 339 MO_HVEM_MaxLeistung 2000;
BA_REL_ "GenSigTimeoutTime" BU_SG_REL_ ICAS1_Gateway SG_ 2600468501 NM_Airbag_01_CBV_AWB 2000;
BA_REL_ "GenSigTimeoutTime" BU_SG_REL_ ICAS1_Gateway SG_ 2600468501 NM_Airbag_01_CBV_CRI 2000;
BA_REL_ "GenSigTimeoutTime" BU_SG_REL_ ICAS1_Gateway SG_ 2600468501 NM_Airbag_01_Car_Wakeup 2000;
BA_REL_ "GenSigTimeoutTime" BU_SG_REL_ ICAS1_Gateway SG_ 2600468501 NM_Airbag_01_CAB_V10 2000;
BA_REL_ "GenSigTimeoutTime" BU_SG_REL_ ICAS1_Gateway SG_ 2600468604 NM_EMotor_01_CBV_AWB 2000;
BA_REL_ "GenSigTimeoutTime" BU_SG_REL_ ICAS1_Gateway SG_ 2600468604 NM_EMotor_01_CBV_CRI 2000;
BA_REL_ "GenSigTimeoutTime" BU_SG_REL_ ICAS1_Gateway SG_ 2600468604 NM_EMotor_01_Car_Wakeup 2000;
BA_REL_ "GenSigTimeoutTime" BU_SG_REL_ ICAS1_Gateway SG_ 2600468604 NM_EMotor_01_CAB_V10 2000;
BA_REL_ "GenSigTimeoutTime" BU_SG_REL_ ICAS1_Gateway SG_ 2600468664 NM_LE2_CBV_AWB 2000;
BA_REL_ "GenSigTimeoutTime" BU_SG_REL_ ICAS1_Gateway SG_ 2600468664 NM_LE2_CBV_CRI 2000;
BA_REL_ "GenSigTimeoutTime" BU_SG_REL_ ICAS1_Gateway SG_ 2600468664 NM_LE2_Car_Wakeup 2000;
BA_REL_ "GenSigTimeoutTime" BU_SG_REL_ ICAS1_Gateway SG_ 2600468664 NM_LE2_CAB_V10 2000;
BA_REL_ "GenSigTimeoutTime" BU_SG_REL_ ICAS1_Gateway SG_ 2600468598 NM_MO_01_CBV_AWB 2000;
BA_REL_ "GenSigTimeoutTime" BU_SG_REL_ ICAS1_Gateway SG_ 2600468598 NM_MO_01_CBV_CRI 2000;
BA_REL_ "GenSigTimeoutTime" BU_SG_REL_ ICAS1_Gateway SG_ 2600468598 NM_MO_01_Car_Wakeup 2000;
BA_REL_ "GenSigTimeoutTime" BU_SG_REL_ ICAS1_Gateway SG_ 2600468598 NM_MO_01_CAB_V10 2000;
BA_REL_ "GenSigTimeoutTime" BU_SG_REL_ ICAS1_Gateway SG_ 2600468733 NM_Waehlhebel_CBV_AWB 2000;
BA_REL_ "GenSigTimeoutTime" BU_SG_REL_ ICAS1_Gateway SG_ 2600468733 NM_Waehlhebel_CBV_CRI 2000;
BA_REL_ "GenSigTimeoutTime" BU_SG_REL_ ICAS1_Gateway SG_ 2600468733 NM_Waehlhebel_Car_Wakeup 2000;
BA_REL_ "GenSigTimeoutTime" BU_SG_REL_ ICAS1_Gateway SG_ 2600468733 NM_Waehlhebel_CAB_V10 2000;
BA_REL_ "GenSigTimeoutTime" BU_SG_REL_ ICAS1_Gateway SG_ 319 PreCrash_Blinken 2000;
BA_REL_ "GenSigTimeoutTime" BU_SG_REL_ ICAS1_KommunikationsServer SG_ 1601 MO_Kraftstoffart 5000;
BA_REL_ "GenSigTimeoutTime" BU_SG_REL_ ICAS1_KommunikationsServer SG_ 1155 Mo_Powermeter_Grenze 5000;
BA_REL_ "GenSigTimeoutTime" BU_SG_REL_ ICAS1_KommunikationsServer SG_ 1155 MO_Text_Aktivierung_Antrieb 5000;
BA_REL_ "GenSigTimeoutTime" BU_SG_REL_ ICAS1_KommunikationsServer SG_ 1155 MO_Powermeter_Charge_Grenze 5000;
BA_REL_ "GenSigTimeoutTime" BU_SG_REL_ ICAS1_KommunikationsServer SG_ 1155 MO_Powermeter_Grenze_strategisch 5000;
BA_REL_ "GenSigTimeoutTime" BU_SG_REL_ ICAS1_KommunikationsServer SG_ 319 SC_PreCrash_Warnung 2000;
BA_REL_ "GenSigTimeoutTime" BU_SG_REL_ ICAS1_KommunikationsServer SG_ 319 SC_PreCrash_Texte 2000;
BA_REL_ "GenSigTimeoutTime" BU_SG_REL_ LE1 SG_ 339 MO_ErwGrenzen_Anf 2000;
BA_REL_ "GenSigTimeoutTime" BU_SG_REL_ LE1 SG_ 2600468501 NM_Airbag_01_NM_State 2000;
BA_REL_ "GenSigTimeoutTime" BU_SG_REL_ LE1 SG_ 2600468496 NM_Gateway_NM_State 2000;
BA_REL_ "GenSigTimeoutTime" BU_SG_REL_ LE1 SG_ 2600468664 NM_LE2_NM_State 2000;
BA_REL_ "GenSigTimeoutTime" BU_SG_REL_ LE1 SG_ 2600468598 NM_MO_01_NM_State 2000;
BA_REL_ "GenSigTimeoutTime" BU_SG_REL_ LE1 SG_ 2600468733 NM_Waehlhebel_NM_State 2000;
BA_REL_ "GenSigTimeoutTime" BU_SG_REL_ LE1 SG_ 2589283656 ORU_Status 5000;
BA_REL_ "GenSigTimeoutTime" BU_SG_REL_ LE2 SG_ 339 MO_ErwGrenzen_Anf 2000;
BA_REL_ "GenSigTimeoutTime" BU_SG_REL_ LE2 SG_ 2600468501 NM_Airbag_01_NM_State 2000;
BA_REL_ "GenSigTimeoutTime" BU_SG_REL_ LE2 SG_ 2600468604 NM_EMotor_01_NM_State 2000;
BA_REL_ "GenSigTimeoutTime" BU_SG_REL_ LE2 SG_ 2600468496 NM_Gateway_NM_State 2000;
BA_REL_ "GenSigTimeoutTime" BU_SG_REL_ LE2 SG_ 2600468598 NM_MO_01_NM_State 2000;
BA_REL_ "GenSigTimeoutTime" BU_SG_REL_ LE2 SG_ 2600468733 NM_Waehlhebel_NM_State 2000;
BA_REL_ "GenSigTimeoutTime" BU_SG_REL_ LE2 SG_ 2589283656 ORU_Status 5000;
BA_REL_ "GenSigTimeoutTime" BU_SG_REL_ Motor_BEV SG_ 2600468501 NM_Airbag_01_NM_State 2000;
BA_REL_ "GenSigTimeoutTime" BU_SG_REL_ Motor_BEV SG_ 2600468604 NM_EMotor_01_NM_State 2000;
BA_REL_ "GenSigTimeoutTime" BU_SG_REL_ Motor_BEV SG_ 2600468496 NM_Gateway_NM_State 2000;
BA_REL_ "GenSigTimeoutTime" BU_SG_REL_ Motor_BEV SG_ 2600468664 NM_LE2_NM_State 2000;
BA_REL_ "GenSigTimeoutTime" BU_SG_REL_ Motor_BEV SG_ 2600468733 NM_Waehlhebel_NM_State 2000;
BA_REL_ "GenSigTimeoutTime" BU_SG_REL_ Motor_BEV SG_ 627 OCC_Status_Spgfreiheit 1000;
BA_REL_ "GenSigTimeoutTime" BU_SG_REL_ Motor_BEV SG_ 627 OCC_Status_EoHVL 1000;
BA_REL_ "GenSigTimeoutTime" BU_SG_REL_ Motor_BEV SG_ 627 OCC_IstModus 1000;
BA_REL_ "GenSigTimeoutTime" BU_SG_REL_ Motor_BEV SG_ 2463978709 OCC_Kuehltemperatur 5000;
BA_REL_ "GenSigTimeoutTime" BU_SG_REL_ Motor_BEV SG_ 2589283656 ORU_Status 5000;
BA_REL_ "GenSigTimeoutTime" BU_SG_REL_ Motor_BEV SG_ 518 Parken_aktives_System 500;
BA_REL_ "GenSigTimeoutTime" BU_SG_REL_ Motor_BEV SG_ 518 Parken_max_Beschleunigung 500;
BA_REL_ "GenSigTimeoutTime" BU_SG_REL_ Motor_BEV SG_ 518 Parken_Sollbeschleunigung 500;
BA_REL_ "GenSigTimeoutTime" BU_SG_REL_ Motor_BEV SG_ 518 Parken_Status_IPA_TSK 500;
BA_REL_ "GenSigTimeoutTime" BU_SG_REL_ Motor_BEV SG_ 518 Parken_erhoehtes_Moment 500;
BA_REL_ "GenSigTimeoutTime" BU_SG_REL_ Motor_BEV SG_ 518 Parken_max_Geschwindigkeit 500;
BA_REL_ "GenSigTimeoutTime" BU_SG_REL_ Motor_BEV SG_ 518 Parken_Fahrstufenwunsch 500;
BA_REL_ "GenSigTimeoutTime" BU_SG_REL_ Motor_BEV SG_ 1122 PSD_Segment_ID 1500;
BA_REL_ "GenSigTimeoutTime" BU_SG_REL_ Motor_BEV SG_ 1122 PSD_Vorgaenger_Segment_ID 1500;
BA_REL_ "GenSigTimeoutTime" BU_SG_REL_ Motor_BEV SG_ 1122 PSD_Segmentlaenge 1500;
BA_REL_ "GenSigTimeoutTime" BU_SG_REL_ Motor_BEV SG_ 1122 PSD_Strassenkategorie 1500;
BA_REL_ "GenSigTimeoutTime" BU_SG_REL_ Motor_BEV SG_ 1122 PSD_Endkruemmung 1500;
BA_REL_ "GenSigTimeoutTime" BU_SG_REL_ Motor_BEV SG_ 1122 PSD_Endkruemmung_Vorz 1500;
BA_REL_ "GenSigTimeoutTime" BU_SG_REL_ Motor_BEV SG_ 1122 PSD_ADAS_Qualitaet 1500;
BA_REL_ "GenSigTimeoutTime" BU_SG_REL_ Motor_BEV SG_ 1122 PSD_wahrscheinlichster_Pfad 1500;
BA_REL_ "GenSigTimeoutTime" BU_SG_REL_ Motor_BEV SG_ 1122 PSD_Geradester_Pfad 1500;
BA_REL_ "GenSigTimeoutTime" BU_SG_REL_ Motor_BEV SG_ 1122 PSD_Fahrspuren_Anzahl 1500;
BA_REL_ "GenSigTimeoutTime" BU_SG_REL_ Motor_BEV SG_ 1122 PSD_Bebauung 1500;
BA_REL_ "GenSigTimeoutTime" BU_SG_REL_ Motor_BEV SG_ 1122 PSD_Segment_Komplett 1500;
BA_REL_ "GenSigTimeoutTime" BU_SG_REL_ Motor_BEV SG_ 1122 PSD_Rampe 1500;
BA_REL_ "GenSigTimeoutTime" BU_SG_REL_ Motor_BEV SG_ 1122 PSD_Anfangskruemmung 1500;
BA_REL_ "GenSigTimeoutTime" BU_SG_REL_ Motor_BEV SG_ 1122 PSD_Anfangskruemmung_Vorz 1500;
BA_REL_ "GenSigTimeoutTime" BU_SG_REL_ Motor_BEV SG_ 1122 PSD_Abzweigerichtung 1500;
BA_REL_ "GenSigTimeoutTime" BU_SG_REL_ Motor_BEV SG_ 1122 PSD_Abzweigewinkel 1500;
BA_REL_ "GenSigTimeoutTime" BU_SG_REL_ Motor_BEV SG_ 1123 PSD_Pos_Segment_ID 1500;
BA_REL_ "GenSigTimeoutTime" BU_SG_REL_ Motor_BEV SG_ 1123 PSD_Pos_Segmentlaenge 1500;
BA_REL_ "GenSigTimeoutTime" BU_SG_REL_ Motor_BEV SG_ 1123 PSD_Pos_Inhibitzeit 1500;
BA_REL_ "GenSigTimeoutTime" BU_SG_REL_ Motor_BEV SG_ 1123 PSD_Pos_Standort_Eindeutig 1500;
BA_REL_ "GenSigTimeoutTime" BU_SG_REL_ Motor_BEV SG_ 1123 PSD_Pos_Fehler_Laengsrichtung 1500;
BA_REL_ "GenSigTimeoutTime" BU_SG_REL_ Motor_BEV SG_ 1123 PSD_Pos_Fahrspur 1500;
BA_REL_ "GenSigTimeoutTime" BU_SG_REL_ Motor_BEV SG_ 1123 PSD_Attribut_Segment_ID_05 1500;
BA_REL_ "GenSigTimeoutTime" BU_SG_REL_ Motor_BEV SG_ 1123 PSD_Attribut_1_ID 1500;
BA_REL_ "GenSigTimeoutTime" BU_SG_REL_ Motor_BEV SG_ 1123 PSD_Attribut_1_Wert 1500;
BA_REL_ "GenSigTimeoutTime" BU_SG_REL_ Motor_BEV SG_ 1123 PSD_Attribut_1_Offset 1500;
BA_REL_ "GenSigTimeoutTime" BU_SG_REL_ Motor_BEV SG_ 1123 PSD_Attribut_2_ID 1500;
BA_REL_ "GenSigTimeoutTime" BU_SG_REL_ Motor_BEV SG_ 1123 PSD_Attribut_2_Wert 1500;
BA_REL_ "GenSigTimeoutTime" BU_SG_REL_ Motor_BEV SG_ 1123 PSD_Attribut_2_Offset 1500;
BA_REL_ "GenSigTimeoutTime" BU_SG_REL_ Motor_BEV SG_ 1123 PSD_Attribute_Komplett_05 1500;
BA_REL_ "GenSigTimeoutTime" BU_SG_REL_ Motor_BEV SG_ 1124 PSD_06_Mux 1500;
BA_REL_ "GenSigTimeoutTime" BU_SG_REL_ Motor_BEV SG_ 1124 PSD_Sys_Segment_ID 1500;
BA_REL_ "GenSigTimeoutTime" BU_SG_REL_ Motor_BEV SG_ 1124 PSD_Attribut_Segment_ID 1500;
BA_REL_ "GenSigTimeoutTime" BU_SG_REL_ Motor_BEV SG_ 1124 PSD_Ges_Segment_ID 1500;
BA_REL_ "GenSigTimeoutTime" BU_SG_REL_ Motor_BEV SG_ 1124 PSD_Baum_Laenge_VZ 1500;
BA_REL_ "GenSigTimeoutTime" BU_SG_REL_ Motor_BEV SG_ 1124 PSD_Steigung_1_Segment_ID 1500;
BA_REL_ "GenSigTimeoutTime" BU_SG_REL_ Motor_BEV SG_ 1124 PSD_Baum_Laenge 1500;
BA_REL_ "GenSigTimeoutTime" BU_SG_REL_ Motor_BEV SG_ 1124 PSD_Sys_Laendercode 1500;
BA_REL_ "GenSigTimeoutTime" BU_SG_REL_ Motor_BEV SG_ 1124 PSD_Attribut_3_ID 1500;
BA_REL_ "GenSigTimeoutTime" BU_SG_REL_ Motor_BEV SG_ 1124 PSD_Ges_Offset 1500;
BA_REL_ "GenSigTimeoutTime" BU_SG_REL_ Motor_BEV SG_ 1124 PSD_Steigung_1_A_Steigung 1500;
BA_REL_ "GenSigTimeoutTime" BU_SG_REL_ Motor_BEV SG_ 1124 PSD_Attribut_3_Offset 1500;
BA_REL_ "GenSigTimeoutTime" BU_SG_REL_ Motor_BEV SG_ 1124 PSD_Ges_Geschwindigkeit 1500;
BA_REL_ "GenSigTimeoutTime" BU_SG_REL_ Motor_BEV SG_ 1124 PSD_Steigung_1_A_Vorz 1500;
BA_REL_ "GenSigTimeoutTime" BU_SG_REL_ Motor_BEV SG_ 1124 PSD_Sys_Geschwindigkeit_Einheit 1500;
BA_REL_ "GenSigTimeoutTime" BU_SG_REL_ Motor_BEV SG_ 1124 PSD_Steigung_1_A_Offset 1500;
BA_REL_ "GenSigTimeoutTime" BU_SG_REL_ Motor_BEV SG_ 1124 PSD_Sys_Verkehrsrichtung 1500;
BA_REL_ "GenSigTimeoutTime" BU_SG_REL_ Motor_BEV SG_ 1124 PSD_Sys_Geometrieguete 1500;
BA_REL_ "GenSigTimeoutTime" BU_SG_REL_ Motor_BEV SG_ 1124 PSD_Sys_Mapmatchingguete 1500;
BA_REL_ "GenSigTimeoutTime" BU_SG_REL_ Motor_BEV SG_ 1124 PSD_Attribut_3_Wert 1500;
BA_REL_ "GenSigTimeoutTime" BU_SG_REL_ Motor_BEV SG_ 1124 PSD_Ges_Typ 1500;
BA_REL_ "GenSigTimeoutTime" BU_SG_REL_ Motor_BEV SG_ 1124 PSD_Sys_Alter_Karte 1500;
BA_REL_ "GenSigTimeoutTime" BU_SG_REL_ Motor_BEV SG_ 1124 PSD_Ges_Spur_Geschw_Begrenzung 1500;
BA_REL_ "GenSigTimeoutTime" BU_SG_REL_ Motor_BEV SG_ 1124 PSD_Steigung_1_B_Steigung 1500;
BA_REL_ "GenSigTimeoutTime" BU_SG_REL_ Motor_BEV SG_ 1124 PSD_Attribut_4_ID 1500;
BA_REL_ "GenSigTimeoutTime" BU_SG_REL_ Motor_BEV SG_ 1124 PSD_Sys_Zielfuehrung 1500;
BA_REL_ "GenSigTimeoutTime" BU_SG_REL_ Motor_BEV SG_ 1124 PSD_Sys_US_State 1500;
BA_REL_ "GenSigTimeoutTime" BU_SG_REL_ Motor_BEV SG_ 1124 PSD_Ges_Geschwindigkeit_Gespann 1500;
BA_REL_ "GenSigTimeoutTime" BU_SG_REL_ Motor_BEV SG_ 1124 PSD_Baum_Breite_VZ 1500;
BA_REL_ "GenSigTimeoutTime" BU_SG_REL_ Motor_BEV SG_ 1124 PSD_Attribut_4_Wert 1500;
BA_REL_ "GenSigTimeoutTime" BU_SG_REL_ Motor_BEV SG_ 1124 PSD_Baum_Breite 1500;
BA_REL_ "GenSigTimeoutTime" BU_SG_REL_ Motor_BEV SG_ 1124 PSD_Ges_Geschwindigkeit_Witter 1500;
BA_REL_ "GenSigTimeoutTime" BU_SG_REL_ Motor_BEV SG_ 1124 PSD_Steigung_1_B_Vorz 1500;
BA_REL_ "GenSigTimeoutTime" BU_SG_REL_ Motor_BEV SG_ 1124 PSD_Steigung_1_B_Offset 1500;
BA_REL_ "GenSigTimeoutTime" BU_SG_REL_ Motor_BEV SG_ 1124 PSD_Ges_Geschwindigkeit_Tag_Anf 1500;
BA_REL_ "GenSigTimeoutTime" BU_SG_REL_ Motor_BEV SG_ 1124 PSD_Attribut_4_Offset 1500;
BA_REL_ "GenSigTimeoutTime" BU_SG_REL_ Motor_BEV SG_ 1124 PSD_Ges_Geschwindigkeit_Tag_Ende 1500;
BA_REL_ "GenSigTimeoutTime" BU_SG_REL_ Motor_BEV SG_ 1124 PSD_Sys_Zielfuehrung_geaendert 1500;
BA_REL_ "GenSigTimeoutTime" BU_SG_REL_ Motor_BEV SG_ 1124 PSD_Ges_Geschwindigkeit_Std_Anf 1500;
BA_REL_ "GenSigTimeoutTime" BU_SG_REL_ Motor_BEV SG_ 1124 PSD_Steigung_1_Attribute_kompl 1500;
BA_REL_ "GenSigTimeoutTime" BU_SG_REL_ Motor_BEV SG_ 1124 PSD_Steigung_2_Segment_ID 1500;
BA_REL_ "GenSigTimeoutTime" BU_SG_REL_ Motor_BEV SG_ 1124 PSD_Attribut_5_ID 1500;
BA_REL_ "GenSigTimeoutTime" BU_SG_REL_ Motor_BEV SG_ 1124 PSD_Ges_Geschwindigkeit_Std_Ende 1500;
BA_REL_ "GenSigTimeoutTime" BU_SG_REL_ Motor_BEV SG_ 1124 PSD_Attribut_5_Offset 1500;
BA_REL_ "GenSigTimeoutTime" BU_SG_REL_ Motor_BEV SG_ 1124 PSD_Steigung_2_Steigung 1500;
BA_REL_ "GenSigTimeoutTime" BU_SG_REL_ Motor_BEV SG_ 1124 PSD_Attribut_5_Wert 1500;
BA_REL_ "GenSigTimeoutTime" BU_SG_REL_ Motor_BEV SG_ 1124 PSD_Steigung_2_Vorz 1500;
BA_REL_ "GenSigTimeoutTime" BU_SG_REL_ Motor_BEV SG_ 1124 PSD_Steigung_2_Offset 1500;
BA_REL_ "GenSigTimeoutTime" BU_SG_REL_ Motor_BEV SG_ 1124 PSD_Ges_Gesetzlich_Kategorie 1500;
BA_REL_ "GenSigTimeoutTime" BU_SG_REL_ Motor_BEV SG_ 1124 PSD_Attribute_Komplett_06 1500;
BA_REL_ "GenSigTimeoutTime" BU_SG_REL_ Motor_BEV SG_ 1124 PSD_Ges_Gesetzlich_Zusatz 1500;
BA_REL_ "GenSigTimeoutTime" BU_SG_REL_ Motor_BEV SG_ 1124 PSD_Ges_Verkehrszeichen_Quelle 1500;
BA_REL_ "GenSigTimeoutTime" BU_SG_REL_ Motor_BEV SG_ 1124 PSD_Steigung_2_Attribute_kompl 1500;
BA_REL_ "GenSigTimeoutTime" BU_SG_REL_ Motor_BEV SG_ 1124 PSD_Ges_Attribute_Komplett 1500;
BA_REL_ "GenSigTimeoutTime" BU_SG_REL_ Motor_BEV SG_ 591 RDR1_relevanter_Fehler 500;
BA_REL_ "GenSigTimeoutTime" BU_SG_REL_ Motor_BEV SG_ 591 RDR1_Blindheit_erkannt 500;
BA_REL_ "GenSigTimeoutTime" BU_SG_REL_ Motor_BEV SG_ 591 RDR1_relev_Nichtverfuegbarkeit 500;
BA_REL_ "GenSigTimeoutTime" BU_SG_REL_ Motor_BEV SG_ 591 RDR1_Obj_01_dx_v 500;
BA_REL_ "GenSigTimeoutTime" BU_SG_REL_ Motor_BEV SG_ 591 RDR1_Obj_01_dy_v 500;
BA_REL_ "GenSigTimeoutTime" BU_SG_REL_ Motor_BEV SG_ 591 RDR1_Obj_01_vx_v 500;
BA_REL_ "GenSigTimeoutTime" BU_SG_REL_ Motor_BEV SG_ 591 RDR1_Obj_04_dx_v 500;
BA_REL_ "GenSigTimeoutTime" BU_SG_REL_ Motor_BEV SG_ 591 RDR1_Obj_04_vx_v 500;
BA_REL_ "GenSigTimeoutTime" BU_SG_REL_ Motor_BEV SG_ 591 RDR1_Obj_01_ax_v 500;
BA_REL_ "GenSigTimeoutTime" BU_SG_REL_ Motor_BEV SG_ 591 RDR1_Obj_01_ax_StdA 500;
BA_REL_ "GenSigTimeoutTime" BU_SG_REL_ Motor_BEV SG_ 591 RDR1_Obj_01_vx_StdA 500;
BA_REL_ "GenSigTimeoutTime" BU_SG_REL_ Motor_BEV SG_ 591 RDR1_Obj_01_dx_StdA 500;
BA_REL_ "GenSigTimeoutTime" BU_SG_REL_ Motor_BEV SG_ 591 RDR1_Obj_01_dy_StdA 500;
BA_REL_ "GenSigTimeoutTime" BU_SG_REL_ Schaltbetaetigung SG_ 2600468501 NM_Airbag_01_NM_State 2000;
BA_REL_ "GenSigTimeoutTime" BU_SG_REL_ Schaltbetaetigung SG_ 2600468604 NM_EMotor_01_NM_State 2000;
BA_REL_ "GenSigTimeoutTime" BU_SG_REL_ Schaltbetaetigung SG_ 2600468496 NM_Gateway_NM_State 2000;
BA_REL_ "GenSigTimeoutTime" BU_SG_REL_ Schaltbetaetigung SG_ 2600468664 NM_LE2_NM_State 2000;
BA_REL_ "GenSigTimeoutTime" BU_SG_REL_ Schaltbetaetigung SG_ 2600468598 NM_MO_01_NM_State 2000;
VAL_ 1601 MO_Faktor_Momente_02 0 "nicht_belegt" ;
VAL_ 1601 MO_Hybridfahrzeug 0 "kein_Hybridfahrzeug" 1 "Mild_Hybrid" 2 "Full_Hybrid" 3 "PlugIn_Hybrid" ;
VAL_ 1601 MO_Getriebe_Code 0 "Init" 2 "DL501" 3 "DL800" 4 "VL381" 5 "DL382_Front" 6 "DL382_Allrad" 7 "DL702" 8 "AL552_Allrad" 9 "AL552_Front" 10 "AL651" 11 "AL551__AL951__AL1000_8A" 12 "PDK_PAG" 13 "AL551_Hybrid" 15 "Handschalter_konventionell" 16 "AQ250_160" 17 "AQ450" 18 "DQ200" 19 "DQ250" 20 "DQ500" 21 "SQ100" 22 "SQ200" 23 "DQ400E" 24 "DQ381" 25 "AL550" 26 "AQ300" 31 "DL800E" 32 "Single_Gear__ohne_GSG_WH_am_MSG" 33 "EQ550_2P" ;
VAL_ 1601 MO_StartStopp_Codiert 0 "Start_Stopp_nicht_verbaut" 1 "Start_Stopp_verbaut" ;
VAL_ 1601 MO_Anzeige_StSt_gueltig 0 "MO_Text_Motorstart_gueltig" 1 "Signale_MO_Anzeige_StSt_gueltig" ;
VAL_ 1601 MO_Anzahl_Zyl 0 "kein_Zylinder" 1 "1_Zylinder" 2 "2_Zylinder" 3 "3_Zylinder" 4 "4_Zylinder" 5 "5_Zylinder" 6 "6_Zylinder" 7 "7_Zylinder" 8 "8_Zylinder" 9 "9_Zylinder" 10 "10_Zylinder" 11 "11_Zylinder" 12 "12_Zylinder" 13 "15_Zylinder" 14 "16_Zylinder" 15 "18_Zylinder" ;
VAL_ 1601 MO_Kraftstoffart 0 "Diesel" 1 "Benzin_inkl_E25_E85" 2 "CNG" 3 "LPG" 4 "Wasserstoff" 5 "E100_Ethanol" 15 "kein_Verbrennungskraftstoff" ;
VAL_ 1601 MO_Ansaugsystem 0 "Turbo" 1 "Sauger" ;
VAL_ 1601 MO_OBD_Typ 0 "NoOBD_RdW" 1 "EOBD" 2 "US_OBD" 3 "reserviert" ;
VAL_ 1601 MO_DPF_verbaut 0 "kein_DPF_verbaut" 1 "DPF_verbaut" ;
VAL_ 1601 TSK_Codierung 0 "kein_Fahrgeschwindigkeitsregler" 1 "GRA" 2 "GRA_Plus" 3 "Basis_ACC" 4 "ACC_Follow_to_Stop" 5 "ACC_Stop_and_Go" 7 "Codierung_in_Plausibilisierungsphase" ;
VAL_ 1155 Mo_Powermeter_Grenze 4093 "OFF" ;
VAL_ 1155 MO_Text_Aktivierung_Antrieb 0 "keine_Anzeige" 1 "Ladestecker_nicht_fahrbereit" 2 "erneute_Aktivierung_erforderlich" 3 "Warten_Antrieb_wird_aktiviert" 4 "zum_Fahren_Bremse_und_Fahrstufe" 15 "Init" ;
VAL_ 1155 MO_Powermeter_Inszenierung_aktiv 0 "keine_Anzeige" 1 "Inszenierung_aktiv" ;
VAL_ 1155 MO_Powermeter_Charge_Grenze 1022 "Init" 1023 "Fehler" ;
VAL_ 1155 MO_Powermeter_Grenze_strategisch 4094 "Init" 4095 "Fehler" ;
VAL_ 1155 MO_Powermeter_untere_E_Grenze 4094 "Init" 4095 "Fehler" ;
VAL_ 1155 MO_Powermeter_obere_E_Grenze 4094 "Init" 4095 "Fehler" ;
VAL_ 2527679686 MRR_HR_ASM_Ereignis 0 "No_Event" 255 "ASM_Trigger" ;
VAL_ 2527679686 MRR_HR_ASM_Zeitstempel 255 "Init" ;
VAL_ 339 MO_HVEM_Eskalation 0 "keine_Eskalation_HVEM" 1 "Eskalation_HVEM" ;
VAL_ 339 MO_ErwGrenzen_Anf 0 "normal" 1 "erweitert" ;
VAL_ 339 MO_Fehler_Notentladung_Anf 0 "Init" ;
VAL_ 339 MO_HVEM_MaxLeistung 510 "Init" ;
VAL_ 339 MO_HVK_EmIstzustand 0 "HvOff" 1 "HvStbyReq" 2 "HvStbyOk" 3 "HvBattOnReq" 4 "HvBattOnOk" 10 "HvOnIdle" 18 "HvOnDrvReq" 19 "HvOnDrvOk" 20 "HvOnDrvRdy" 28 "HvStepUpReq" 29 "HvStepUpOk" 30 "HvStepUp" 38 "HvStepDownReq" 39 "HvStepDownOk" 40 "HvStepDown" 46 "HvAcChPreReq" 47 "HvAcChPreOk" 48 "HvAcChReq" 49 "HvAcChOk" 50 "HvAcCh" 56 "HvDcChPreReq" 57 "HvDcChPreOk" 58 "HvDcChReq" 59 "HvDcChOk" 60 "HvDcCh" 67 "HvChOffReq" 68 "HvChOffOk" 69 "HvOnIdleReq" 70 "HvOnIdleOk" 96 "HvCpntOffReq" 97 "HvCpntOffOk" 98 "HvBattOffReq" 99 "HvBattOffOk" 109 "HvDcDcFailOffReq" 110 "HvDcDcFail" 119 "HvElmOffReq" 120 "HvElmOff" 126 "HvFailCpntOffReq" 127 "HvFailCpntOffOk" 128 "HvFailBattOffReq" 129 "HvFailBattOffOk" 130 "HvFailBattOff" 138 "HvFailUCtlReq" 139 "HvFailUCtlOk" 140 "HvFailUCtl" 150 "HvEmgcyOff" 255 "Init" ;
VAL_ 339 MO_HVK_AntriebFehlerstatus 0 "Komponente_IO" 6 "Keine_Komponentenfunktion" 7 "Init" ;
VAL_ 339 MO_MVK_Bordnetz_Anf 0 "keine_Anforderung" 1 "Bordnetzaktivitaet_gefordert" ;
VAL_ 339 MO_HVK_AntriebZustand 0 "Antrieb_AUS" 1 "Antrieb_Startphase" 2 "E_Fahren" 3 "Hybrid_Fahren" 7 "Init" ;
VAL_ 339 MO_HVK_EmFehlerstatus 0 "Komponente_IO" 1 "Eingeschr_KompFkt_Teilbetrieb" 3 "Eingeschr_KompFkt_Interlock" 6 "Keine_Komponentenfunktion" 7 "Init" ;
VAL_ 339 MO_MVK_AntriebFehlerstatus 0 "Komponente_IO" 6 "Keine_Komponentenfunktion" 7 "Init" ;
VAL_ 339 MO_MVK_AntriebZustand 0 "Antrieb_AUS" 1 "Antrieb_Startphase" 2 "FreilaufMotorAus" 7 "Init" ;
VAL_ 339 MO_MVK_EmFehlerstatus 0 "Komponente_IO" 1 "Eingeschr_KompFkt_Teilbetrieb" 6 "Keine_Komponentenfunktion" 7 "Init" ;
VAL_ 339 MO_MVK_EmIstzustand 0 "MvOff" 1 "MvStbyReq" 2 "MvStbyOk" 3 "MvBattOnReq" 4 "MvBattOnOk" 10 "MvOnIdle" 18 "MvOnDrvReq" 19 "MvOnDrvOk" 20 "MvOnDrv" 28 "MvStepUpReq" 29 "MvStepUpOk" 30 "MvStepUp" 38 "MvStepDownReq" 39 "MvStepDownOk" 40 "MvStepDown" 96 "MvCpntOffReq" 97 "MvCpntOffOk" 98 "MvBattOffReq" 99 "MvBattOffOk" 109 "MvDcDcFailOffReq" 110 "MvDcDcFail" 119 "MvElmFailOffReq" 120 "MvElmFail" 126 "MvFailCpntOffReq" 127 "MvFailCpntOffOk" 128 "MvFailBattOffReq" 129 "MvFailBattOffOk" 130 "MvFailBattOff" 138 "MvFailUCtlReq" 139 "MvFailUCtlOk" 140 "MvFailUCtl" 150 "MvEmgcyOff" 255 "Init" ;
VAL_ 2600468501 NM_Airbag_01_CBV_AWB 0 "Passiver_WakeUp" 1 "Aktiver_WakeUp" ;
VAL_ 2600468501 NM_Airbag_01_CBV_CRI 0 "Standard_Layout" 1 "TNB_Layout" ;
VAL_ 2600468501 NM_Airbag_01_NM_State 1 "NM_RM_aus_BSM" 2 "NM_RM_aus_PBSM" 4 "NM_NO_aus_RM" 8 "NM_NO_aus_RS" ;
VAL_ 2600468501 NM_Airbag_01_Car_Wakeup 0 "Inaktiv" 1 "Car_Wakeup" ;
VAL_ 2600468501 NM_Airbag_01_UDS_CC 0 "Init" 1 "CC_aktiv" ;
VAL_ 2600468501 NM_Airbag_01_NM_aktiv_KL15 0 "Inaktiv" 1 "KL15_EIN" ;
VAL_ 2600468501 NM_Airbag_01_NM_aktiv_Diagnose 0 "Init" 1 "Diagnose_aktiv" ;
VAL_ 2600468501 NM_Airbag_01_NM_aktiv_Tmin 0 "Inaktiv" 1 "Mindestaktivzeit" ;
VAL_ 2600468501 NM_Airbag_01_CAB_V10 0 "Init" 1 "CAB_01_Antrieb" 2 "CAB_02_Hybrid_Laden" 4 "CAB_03_Fahrwerk" 8 "CAB_04_Fahrerassistenz" 16 "CAB_05_Komfort" 32 "CAB_06_Anzeige" 64 "CAB_07_Connect" 128 "CAB_08_MIB" 256 "CAB_09_Standheizung" 1024 "CAB_11_VLAN_Fahrerassistenz" 4096 "CAB_13_VLAN_Connect" 8192 "CAB_14_VLAN_Infotainment" 16384 "CAB_15_Laden" 32768 "CAB_16_Licht" ;
VAL_ 2600468604 NM_EMotor_01_CBV_AWB 0 "Passiver_WakeUp" 1 "Aktiver_WakeUp" ;
VAL_ 2600468604 NM_EMotor_01_CBV_CRI 0 "Standard_Layout" 1 "TNB_Layout" ;
VAL_ 2600468604 NM_EMotor_01_NM_State 1 "NM_RM_aus_BSM" 2 "NM_RM_aus_PBSM" 4 "NM_NO_aus_RM" 8 "NM_NO_aus_RS" ;
VAL_ 2600468604 NM_EMotor_01_Car_Wakeup 0 "Inaktiv" 1 "Car_Wakeup" ;
VAL_ 2600468604 NM_EMotor_01_UDS_CC 0 "Init" 1 "CC_aktiv" ;
VAL_ 2600468604 NM_EMotor_01_NM_aktiv_KL15 0 "Inaktiv" 1 "KL15_EIN" ;
VAL_ 2600468604 NM_EMotor_01_NM_aktiv_Diagnose 0 "Init" 1 "Diagnose_aktiv" ;
VAL_ 2600468604 NM_EMotor_01_NM_aktiv_Tmin 0 "Inaktiv" 1 "Mindestaktivzeit" ;
VAL_ 2600468604 NM_EMotor_01_keine_HV_Entl 1 "keine_HV_Entladung_moeglich" ;
VAL_ 2600468604 NM_EMotor_01_CAB_V10 0 "Init" 1 "CAB_01_Antrieb" 2 "CAB_02_Hybrid_Laden" 4 "CAB_03_Fahrwerk" 8 "CAB_04_Fahrerassistenz" 16 "CAB_05_Komfort" 32 "CAB_06_Anzeige" 64 "CAB_07_Connect" 128 "CAB_08_MIB" 256 "CAB_09_Standheizung" 1024 "CAB_11_VLAN_Fahrerassistenz" 4096 "CAB_13_VLAN_Connect" 8192 "CAB_14_VLAN_Infotainment" 16384 "CAB_15_Laden" 32768 "CAB_16_Licht" ;
VAL_ 2600468496 NM_Gateway_CBV_AWB 0 "Passiver_WakeUp" 1 "Aktiver_WakeUp" ;
VAL_ 2600468496 NM_Gateway_CBV_CRI 0 "Standard_Layout" 1 "TNB_Layout" ;
VAL_ 2600468496 NM_Gateway_NM_State 1 "NM_RM_aus_BSM" 2 "NM_RM_aus_PBSM" 4 "NM_NO_aus_RM" 8 "NM_NO_aus_RS" 16 "NM_RM_aus_RS" 32 "NM_RM_aus_NO" ;
VAL_ 2600468496 NM_Gateway_Car_Wakeup 0 "Inaktiv" 1 "Car_Wakeup" ;
VAL_ 2600468496 NM_Gateway_UDS_CC 0 "Init" 1 "CC_aktiv" ;
VAL_ 2600468496 NM_Gateway_NM_aktiv_KL15 0 "Inaktiv" 1 "KL15_EIN" ;
VAL_ 2600468496 NM_Gateway_NM_aktiv_Diagnose 0 "Init" 1 "Diagnose_aktiv" ;
VAL_ 2600468496 NM_Gateway_NM_aktiv_Tmin 0 "Inaktiv" 1 "Mindestaktivzeit" ;
VAL_ 2600468496 NM_Gateway_CAB_V10 0 "Init" 1 "CAB_01_Antrieb" 2 "CAB_02_Hybrid_Laden" 4 "CAB_03_Fahrwerk" 8 "CAB_04_Fahrerassistenz" 16 "CAB_05_Komfort" 32 "CAB_06_Anzeige" 64 "CAB_07_Connect" 128 "CAB_08_MIB" 256 "CAB_09_Standheizung" 1024 "CAB_11_VLAN_Fahrerassistenz" 4096 "CAB_13_VLAN_Connect" 8192 "CAB_14_VLAN_Infotainment" 16384 "CAB_15_Laden" 32768 "CAB_16_Licht" ;
VAL_ 2600468664 NM_LE2_CBV_AWB 0 "Passiver_WakeUp" 1 "Aktiver_WakeUp" ;
VAL_ 2600468664 NM_LE2_CBV_CRI 0 "Standard_Layout" 1 "TNB_Layout" ;
VAL_ 2600468664 NM_LE2_NM_State 1 "NM_RM_aus_BSM" 2 "NM_RM_aus_PBSM" 4 "NM_NO_aus_RM" 8 "NM_NO_aus_RS" 16 "NM_RM_aus_RS" 32 "NM_RM_aus_NO" ;
VAL_ 2600468664 NM_LE2_Car_Wakeup 0 "Inaktiv" 1 "Car_Wakeup" ;
VAL_ 2600468664 NM_LE2_UDS_CC 0 "Init" 1 "CC_aktiv" ;
VAL_ 2600468664 NM_LE2_NM_aktiv_KL15 0 "Inaktiv" 1 "KL15_EIN" ;
VAL_ 2600468664 NM_LE2_NM_aktiv_Diagnose 0 "Init" 1 "Diagnose_aktiv" ;
VAL_ 2600468664 NM_LE2_NM_aktiv_Tmin 0 "Inaktiv" 1 "Mindestaktivzeit" ;
VAL_ 2600468664 NM_LE2_keine_HV_entl 0 "Inaktiv" 1 "keine_HV_Entladung_moeglich" ;
VAL_ 2600468664 NM_LE2_CAB_V10 0 "Init" 1 "CAB_01_Antrieb" 2 "CAB_02_Hybrid_Laden" 4 "CAB_03_Fahrwerk" 8 "CAB_04_Fahrerassistenz" 16 "CAB_05_Komfort" 32 "CAB_06_Anzeige" 64 "CAB_07_Connect" 128 "CAB_08_MIB" 256 "CAB_09_Standheizung" 1024 "CAB_11_VLAN_Fahrerassistenz" 4096 "CAB_13_VLAN_Connect" 8192 "CAB_14_VLAN_Infotainment" 16384 "CAB_15_Laden" 32768 "CAB_16_Licht" ;
VAL_ 2600468598 NM_MO_01_CBV_AWB 0 "Passiver_WakeUp" 1 "Aktiver_WakeUp" ;
VAL_ 2600468598 NM_MO_01_CBV_CRI 0 "Standard_Layout" 1 "TNB_Layout" ;
VAL_ 2600468598 NM_MO_01_NM_State 1 "NM_RM_aus_BSM" 2 "NM_RM_aus_PBSM" 4 "NM_NO_aus_RM" 8 "NM_NO_aus_RS" 16 "NM_RM_aus_RS" 32 "NM_RM_aus_NO" ;
VAL_ 2600468598 NM_MO_01_Car_Wakeup 0 "Inaktiv" 1 "Car_Wakeup" ;
VAL_ 2600468598 NM_MO_01_UDS_CC 0 "Init" 1 "CC_aktiv" ;
VAL_ 2600468598 NM_MO_01_NM_aktiv_KL15 0 "Inaktiv" 1 "KL15_EIN" ;
VAL_ 2600468598 NM_MO_01_NM_aktiv_Diagnose 0 "Init" 1 "Diagnose_aktiv" ;
VAL_ 2600468598 NM_MO_01_NM_aktiv_Tmin 0 "Inaktiv" 1 "Mindestaktivzeit" ;
VAL_ 2600468598 NM_MO_01_NM_aktiv_Betankung 0 "kein_Nachlauf" 1 "Betankung_Drucktank" ;
VAL_ 2600468598 NM_MO_01_NM_aktiv_Waehlhebel 0 "kein_Nachlauf" 1 "Kommunikation_Waehlhebel" ;
VAL_ 2600468598 NM_MO_01_NM_aktiv_HV_Abschaltung 0 "kein_Nachlauf" 1 "Abschaltung_aktiv" ;
VAL_ 2600468598 NM_MO_01_NM_aktiv_Hochvolt 0 "kein_Nachlauf" 1 "Hochvolt_aktiv" ;
VAL_ 2600468598 NM_MO_01_CAB_V10 0 "Init" 1 "CAB_01_Antrieb" 2 "CAB_02_Hybrid_Laden" 4 "CAB_03_Fahrwerk" 8 "CAB_04_Fahrerassistenz" 16 "CAB_05_Komfort" 32 "CAB_06_Anzeige" 64 "CAB_07_Connect" 128 "CAB_08_MIB" 256 "CAB_09_Standheizung" 1024 "CAB_11_VLAN_Fahrerassistenz" 4096 "CAB_13_VLAN_Connect" 8192 "CAB_14_VLAN_Infotainment" 16384 "CAB_15_Laden" 32768 "CAB_16_Licht" ;
VAL_ 2600468733 NM_Waehlhebel_CBV_AWB 0 "Passiver_WakeUp" 1 "Aktiver_WakeUp" ;
VAL_ 2600468733 NM_Waehlhebel_CBV_CRI 0 "Standard_Layout" 1 "TNB_Layout" ;
VAL_ 2600468733 NM_Waehlhebel_NM_State 0 "Init" 1 "NM_RM_aus_BSM" 2 "NM_RM_aus_PBSM" 4 "NM_NO_aus_RM" 8 "NM_NO_aus_RS" 16 "NM_RM_aus_RS" 32 "NM_RM_aus_NO" ;
VAL_ 2600468733 NM_Waehlhebel_Car_Wakeup 0 "Inaktiv" 1 "Car_Wakeup" ;
VAL_ 2600468733 NM_Waehlhebel_UDS_CC 0 "Init" 1 "CC_aktiv" ;
VAL_ 2600468733 NM_Waehlhebel_NM_aktiv_KL15 0 "Inaktiv" 1 "KL15_EIN" ;
VAL_ 2600468733 NM_Waehlhebel_NM_aktiv_Diagnose 0 "Init" 1 "Diagnose_aktiv" ;
VAL_ 2600468733 NM_Waehlhebel_NM_aktiv_Tmin 0 "Inaktiv" 1 "Mindestaktivzeit" ;
VAL_ 2600468733 NM_Waehlhebel_CAB_V10 0 "Init" 1 "CAB_01_Antrieb" 2 "CAB_02_Hybrid_Laden" 4 "CAB_03_Fahrwerk" 8 "CAB_04_Fahrerassistenz" 16 "CAB_05_Komfort" 32 "CAB_06_Anzeige" 64 "CAB_07_Connect" 128 "CAB_08_MIB" 256 "CAB_09_Standheizung" 1024 "CAB_11_VLAN_Fahrerassistenz" 4096 "CAB_13_VLAN_Connect" 8192 "CAB_14_VLAN_Infotainment" 16384 "CAB_15_Laden" 32768 "CAB_16_Licht" ;
VAL_ 627 OCC_Stecker_Status 0 "Init" 1 "kein_Stecker_erkannt" 2 "Stecker_erkannt" 3 "Fehler" ;
VAL_ 627 OCC_Status_Spgfreiheit 0 "Init__ohne_Funktion" 1 "HV_Komponente_Spannungsfrei" 2 "HV_Komponente_nichtSpannungsfrei" 3 "Fehler" ;
VAL_ 627 OCC_DC_IstStrom 2046 "Init" 2047 "Fehler" ;
VAL_ 627 OCC_CC_Latchstatus_DC_GBT 0 "nicht_betaetigt" 1 "betaetigt" 2 "nicht_vorhanden" 6 "Init" 7 "Fehler" ;
VAL_ 627 OCC_Status_EoHVL 0 "Init" 1 "Keine_offene_HV_Leitung_erkannt" 2 "offene_HV_Leitung_erkannt" 3 "Fehler" ;
VAL_ 627 OCC_I_istAC_Netz_L1 510 "Init" 511 "Fehler" ;
VAL_ 627 OCC_PP_Latchstatus_A 0 "nicht_betaetigt" 1 "betaetigt" 2 "nicht_vorhanden" 6 "Init" 7 "Fehler" ;
VAL_ 627 OCC_PP_Latchstatus_B 0 "nicht_betaetigt" 1 "betaetigt" 2 "nicht_vorhanden" 6 "Init" 7 "Fehler" ;
VAL_ 627 OCC_I_istAC_Netz_L2 510 "Init" 511 "Fehler" ;
VAL_ 627 OCC_I_istAC_Netz_L3 509 "nicht_vorhanden" 510 "Init" 511 "Fehler" ;
VAL_ 627 OCC_IstModus 0 "Standby" 1 "Netzladung_aktiv" 2 "Rueckspeisung_aktiv" 3 "reserve" 4 "reserve" 5 "reserve" 6 "Init" 7 "Fehler" ;
VAL_ 627 OCC_CP_Status_A 0 "CP_nicht_erkannt" 1 "CP_erkannt" 2 "Init" 3 "Fehler" ;
VAL_ 627 OCC_CP_Status_B 0 "CP_nicht_erkannt" 1 "CP_erkannt" 2 "Init" 3 "Fehler" ;
VAL_ 627 OCC_IstSpannung_HV 1022 "Init" 1023 "Fehler" ;
VAL_ 627 OCC_PP_Status_A 0 "nicht_erkannt" 1 "erkannt" 2 "Init" 3 "Fehler" ;
VAL_ 627 OCC_PP_Status_B 0 "nicht_erkannt" 1 "erkannt" 2 "Init" 3 "Fehler" ;
VAL_ 627 OCC_CC_Status_DC_GBT 0 "nicht_erkannt" 1 "erkannt" 2 "Init" 3 "Fehler" ;
VAL_ 627 OCC_CC_Fehlerstatus_DC_GBT 0 "Init" 1 "kein_Fehler" 2 "Aktiv_Kurzschluss_nach_Masse" 3 "Aktiv_Kurzschluss_nach_12V" 4 "Fehler_in_Hardwarschaltung" 5 "Fehler_Ladedose" 6 "Fehler_Ladestecker" 7 "keine_GBT_DC_Ladedose" 8 "Fehler_Zwischenbereich_erkannt" ;
VAL_ 627 OCC_Temp_Sensor_Fehlerstatus_DC 0 "Init" 1 "Fehler_Sensor_defekt" 2 "kein_Fehler" ;
VAL_ 627 OCC_Temp_Sensor_Fehlerstatus_AC 0 "Init" 1 "Fehler_Kurzschluss" 2 "Warnung" 3 "kein_Fehler" ;
VAL_ 627 OCC_Temp_Sensor_Status 0 "Init" 1 "kein_Fehler" 2 "DC_Plus_Fehler" 3 "DC_Minus_Fehler" 4 "DC_Plus_und_DC_Minus_Fehler" 5 "Reserve" 6 "Reserve" ;
VAL_ 2463978709 OCC_CP_Tastgrad_A 1022 "Init" 1023 "Fehler" ;
VAL_ 2463978709 OCC_CP_Tastgrad_B 1022 "Init" 1023 "Fehler" ;
VAL_ 2463978709 OCC_CP_Frequenz_A 253 "keine_Frequenz_erkannt" 254 "Init" 255 "Fehler" ;
VAL_ 2463978709 OCC_CP_Frequenz_B 253 "keine_Frequenz_erkannt" 254 "Init" 255 "Fehler" ;
VAL_ 2463978709 OCC_CP_Spannung_A 510 "Init" 511 "Fehler" ;
VAL_ 2463978709 OCC_CP_Spannung_B 510 "Init" 511 "Fehler" ;
VAL_ 2463978709 OCC_CP_Fehlerstatus_A 0 "Messsystem_niO" 1 "Spannung_niO" 2 "Frequenz_niO" 3 "Tastgrad_niO" 4 "Init" 5 "Kein_Fehler" 6 "keine_CP_Ladedose" ;
VAL_ 2463978709 OCC_CP_Fehlerstatus_B 0 "Messsystem_niO" 1 "Spannung_niO" 2 "Frequenz_niO" 3 "Tastgrad_niO" 4 "Init" 5 "kein_Fehler" 6 "keine_CP_Ladedose" ;
VAL_ 2463978709 OCC_Temp_Ladedose_A_AC 254 "Init" 255 "Fehler" ;
VAL_ 2463978709 OCC_Temp_Ladedose_A_DC_minus 254 "Init" 255 "Fehler" ;
VAL_ 2463978709 OCC_Temp_Ladedose_A_DC_plus 254 "Init" 255 "Fehler" ;
VAL_ 2463978709 OCC_U_istAC_Netz_L1 510 "Init" 511 "Fehler" ;
VAL_ 2463978709 OCC_U_istAC_Netz_L2 510 "Init" 511 "Fehler" ;
VAL_ 2463978709 OCC_U_istAC_Netz_L3 509 "nicht_vorhanden" 510 "Init" 511 "Fehler" ;
VAL_ 2463978709 OCC_StatusVerEntriegelungAktor_A 0 "keine_Ansteuerung" 1 "entriegeln_wird_angesteuert" 2 "verriegeln_wird_angesteuert" 3 "maximale_WdhVersuche_erreicht" 4 "reserve" 5 "reserve" 6 "Init" 7 "Fehler" ;
VAL_ 2463978709 OCC_SteckerEntriegelung_Verbot_A 0 "kein_Verbot" 1 "Entriegelungsverbot_des_Steckers" 2 "reserve" 3 "Init" ;
VAL_ 2463978709 OCC_StatusVerEntriegelungAktor_B 0 "keine_Ansteuerung" 1 "entriegeln_wird_angesteuert" 2 "verriegeln_wird_angesteuert" 3 "maximale_WdhVersuche_erreicht" 4 "reserve" 5 "reserve" 6 "Init" 7 "Fehler" ;
VAL_ 2463978709 OCC_SteckerEntriegelung_Verbot_B 0 "kein_Verbot" 1 "Entriegelungsverbot_des_Steckers" 2 "reserve" 3 "Init" ;
VAL_ 2463978709 OCC_Verriegelung_Status_A 0 "entriegelt" 1 "verriegelt" 2 "zu_weit_gefahren_erkannt" 3 "verklemmt_erkannt" 4 "reserve" 5 "reserve" 6 "Init" 7 "Fehler" ;
VAL_ 2463978709 OCC_Verriegelung_Status_B 0 "entriegelt" 1 "verriegelt" 2 "zu_weit_gefahren_erkannt" 3 "verklemmt_erkannt" 4 "reserve" 5 "reserve" 6 "Init" 7 "Fehler" ;
VAL_ 2463978709 OCC_RtmWarnLadeKommunikation 0 "kein_Fehler" 1 "Fehler_Stufe_1" 2 "Fehler_Stufe_2" 3 "Fehler_Stufe_3" 4 "reserviert" 5 "reserviert" 6 "reserviert" 7 "reserviert" ;
VAL_ 2463978709 OCC_Ist_Wirkungsgrad 126 "Init" 127 "Fehler" ;
VAL_ 2463978709 OCC_PP_Max_Strom_A 0 "nicht_vorhanden" 1 "Wert_10A" 2 "Wert_13A" 3 "Wert_16A" 4 "Wert_20A" 5 "Wert_32A" 6 "Wert_63A" 7 "reserve" 8 "Init" 9 "Fehler" ;
VAL_ 2463978709 OCC_PP_Max_Strom_B 0 "nicht_vorhanden" 1 "Wert_10A" 2 "Wert_13A" 3 "Wert_16A" 4 "Wert_20A" 5 "Wert_32A" 6 "Wert_63A" 7 "reserve" 8 "Init" 9 "Fehler" ;
VAL_ 2463978709 OCC_DC_MaxStrom 2046 "Init" 2047 "Fehler" ;
VAL_ 2463978709 OCC_Derating_Temperatur 0 "kein_Derating_aktiv" 1 "Derating_aktiv" ;
VAL_ 2463978709 OCC_Fehlerzustand 0 "kein_Fehler_aktiv" 1 "Fehler_aktiv_Laden_beendet" ;
VAL_ 2463978709 OCC_Ladest_Entriegelungs_Verbot 0 "kein_Entriegelungsverbot" 1 "Entriegelungsverbot_Ladedose_A" 2 "Entriegelungsverbot_Ladedose_B" 3 "Entriegelungsverbot_beide_Ladedo" 4 "reserve" 5 "reserve" 6 "Init" 7 "Fehler" ;
VAL_ 2463978709 OCC_Netzfrequenz_EVU 509 "kein_Frequenz_erkannt" 510 "Init" 511 "Fehler" ;
VAL_ 2463978709 OCC_Warnzustand 0 "keine_Warnung" 1 "Warnung_aktiv" ;
VAL_ 2463978709 OCC_Kuehltemperatur 254 "Init" 255 "Fehler" ;
VAL_ 2463978709 OCC_PP_Fehlerstatus_A 0 "keinen_Fehler" 1 "Fehler_Zwischenbereich_erkannt" 2 "Aktiv_Kurzschluss_nach_Masse" 3 "Aktiv_Kurzschluss_nach_12V" 4 "Fehler_in_Hardwareschaltung" 5 "Fehler_Ladedose" 6 "Fehler_Ladestecker" 7 "keine_PP_Ladedose" 8 "Init" ;
VAL_ 2463978709 OCC_PP_Fehlerstatus_B 0 "kein_Fehler" 1 "Fehler_Zwischenbereich_erkannt" 2 "Aktiv_Kurzschluss_nach_Masse" 3 "Aktiv_Kurzschluss_nach_12V" 4 "Fehler_in_Hardwareschaltung" 5 "Fehler_Ladedose" 6 "Fehler_Ladestecker" 7 "keine_PP_Ladedose" 8 "Init" ;
VAL_ 2589283656 ORU_EM_Anfrage_freigegebeneNetze 0 "only_12V" 1 "networks_48V_and_12V" 2 "networks_HV_and_12V" 3 "networks_HV_and_48V_and_12V" ;
VAL_ 2589283656 ORU_Warnung 0 "keine_Anzeige" 1 "Update_unvollstaendig_Prio1" 2 "reserviert" 3 "reserviert" ;
VAL_ 2589283656 ORU_Status 0 "IDLE" 1 "PENDING" 2 "PREPARATION" 3 "PREPARATION_HV" 4 "RUNNING" 5 "RUNNING_HV" 6 "PENDING_NOTREADY" ;
VAL_ 2527679741 PAO_ON_Status 0 "LED_aus" 1 "LED_an" 2 "LED_blinkt" 3 "LED_defekt" ;
VAL_ 2527679741 PAO_OFF_Status 0 "LED_aus" 1 "LED_an" 2 "LED_blinkt" 3 "LED_defekt" ;
VAL_ 518 Parken_BKD_Anf 14 "Neutralwert" 15 "Fehler" ;
VAL_ 518 Parken_Verz_Anf 126 "Neutralwert" 127 "reserved" ;
VAL_ 518 Parken_Prefill_Anf 0 "keine_Anforderung" 1 "Prefill_Anforderung" ;
VAL_ 518 Parken_Warnruck_Anf 0 "Keine_Anforderung" 1 "schwacher_Warnruck" 2 "mittlerer_Warnruck" 3 "starker_Warnruck" ;
VAL_ 518 Parken_Verz_Anf_ASIL 0 "ASIL_QM" 1 "ASIL_A" 2 "ASIL_B" 3 "ASIL_C" ;
VAL_ 518 Parken_Warnruckeln_Anf 0 "keine_Anforderung" 1 "schwaches_Warnruckeln" 2 "mittleres_Warnruckeln" 3 "starkes_Warnruckeln" ;
VAL_ 518 Parken_beibehalten 0 "Parken_nicht_beibehalten" 1 "Parken_beibehalten" 2 "Init" 3 "Fehler" ;
VAL_ 518 Parken_Anforderung_HMS 0 "keine_Anforderung" 1 "Halten" 2 "Parken" 3 "Halten_standby" 4 "Anfahren" 5 "Loesen_ueber_Rampe" 6 "Parken_mit_P" 7 "reserviert" ;
VAL_ 518 Parken_Notstopp_Anf 0 "Ueberwachung_aus" 1 "Ueberwachung_ein" 2 "Notstopp_ausloesen" ;
VAL_ 518 Parken_Anhalteweg_Anf 1022 "Neutralwert" 1023 "Fehler" ;
VAL_ 518 Parken_aktives_System 0 "kein_aktives_System" 1 "Manoevrierassistent_Ueberwachung" 2 "IPA" 3 "fernbedientes_Parken" 4 "Manoevrierassistent" 5 "Manoevrierassistent_quer" 6 "Anhaengerrangierassistent" 7 "fernbedienter_Anhaengerrangierassistent" ;
VAL_ 518 Parken_max_Beschleunigung 0 "Inaktiv" 122 "Init" 127 "Fehler" ;
VAL_ 518 Parken_Blinker_li_Anf 0 "keine_Anforderung" 1 "Blinker_links_aktivieren" ;
VAL_ 518 Parken_QFK_KruemmSoll_VZ 0 "positiv" 1 "negativ" ;
VAL_ 518 Parken_QFK_AnfStat 1 "Init" 2 "Bereit" 4 "Eingriff" ;
VAL_ 518 Parken_Sollbeschleunigung 0 "Neutralwert" ;
VAL_ 518 Parken_Blinker_re_Anf 0 "keine_Anforderung" 1 "Blinker_rechts_aktivieren" ;
VAL_ 518 Parken_Status_IPA_TSK 1 "IPA_TSK_Init" 2 "IPA_TSK_Fehler" 4 "IPA_TSK_aktivierbar" 5 "IPA_TSK_pausiert" 6 "IPA_TSK_aktiv" 8 "IPA_TSK_funktionsbereit" ;
VAL_ 518 Parken_erhoehtes_Moment 0 "keine_Anforderung" 1 "Anforderung_Rampe1" 2 "Anforderung_Rampe2" 3 "Anforderung_Rampe3" 4 "Anforderung_Rampe4" 5 "Anforderung_Rampe5" 6 "Anforderung_Rampe6" 7 "Anforderung_Rampe7" 8 "Anforderung_Rampe8" 9 "Anforderung_Rampe9" 10 "Anforderung_Rampe10" 11 "Anforderung_Rampe11" 12 "Anforderung_Rampe12" 13 "Anforderung_Rampe13" 14 "Anforderung_Rampe14" 15 "Anforderung_Rampe15" ;
VAL_ 518 Parken_max_Geschwindigkeit 0 "Inaktiv" 251 "Init" 255 "Fehler" ;
VAL_ 518 Parken_Soll_Anhalteweg_Anf 1022 "Neutralwert" 1023 "Fehler" ;
VAL_ 518 Parken_Fahrstufenwunsch 0 "Init" 1 "Fahrstufe_beibehalten" 2 "Position_R" 3 "Position_D" 4 "Position_N" ;
VAL_ 518 IPA_TPA_Remote 0 "nicht_aktiv" 1 "aktiv" 2 "Uebergabe" 3 "Uebernahme" ;
VAL_ 518 IPA_TPA_Remote_Anf 0 "keine_Anforderung" 1 "Remote_Anforderung" ;
VAL_ 518 IPA_TPA_Fehler 0 "Init" 1 "ESC_Fehler" 2 "PPF_Fehler" 3 "VMM_Fehler" 4 "sonstiger_Fehler" 5 "temporaerer_Fehler" ;
VAL_ 518 IPA_TPA_Abbruch 0 "Init" 1 "ESC_Fehler" 2 "PPF_Fehler" 3 "VMM_Fehler" 4 "sonstiger_Fehler" 5 "temporaerer_Fehler" 7 "Hindernis" 8 "Ueberschreitung_vMax" 9 "Lenkeingriff_Fahrer" 10 "Tuer_offen" 11 "MH_HD_offen" ;
VAL_ 518 IPA_TPA_Status 0 "deaktiv" 1 "Init" 4 "startbereit" 6 "Regelung_aktiv" 7 "Parkvorgang_abgeschlossen" 8 "funktionsbereit" 10 "Abbruch" 15 "Error" ;
VAL_ 2527679685 PDC_ASM_Ereignis 0 "No_Event" 255 "ASM_Trigger" ;
VAL_ 2527679685 PDC_ASM_Zeitstempel 255 "Init" ;
VAL_ 319 PreCrash_Charisma_FahrPr 0 "keine_Funktion" 1 "Programm_1" 2 "Programm_2" 3 "Programm_3" 4 "Programm_4" 5 "Programm_5" 6 "Programm_6" 7 "Programm_7" 8 "Programm_8" 9 "Programm_9" 10 "Programm_10" 11 "Programm_11" 12 "Programm_12" 13 "Programm_13" 14 "Programm_14" 15 "Programm_15" ;
VAL_ 319 PreCrash_Charisma_Status 0 "Init" 1 "verfuegbar" 2 "nicht_verfuegbar" 3 "asynchron_durch_Fahrerwunsch" ;
VAL_ 319 PreCrash_Schiebedach_schliessen 0 "keine_Schliessung" 1 "Schliessung_angefordert" ;
VAL_ 319 PreCrash_Fenster_schliessen 0 "keine_Schliessung" 1 "Schliessung_angefordert" ;
VAL_ 319 PreCrash_Blinken 0 "keine_Blinkanforderung" 1 "Warnblinken" 2 "RECAS_Blinken" 3 "Notbremsblinken" ;
VAL_ 319 SC_PreSense_FCWP 0 "Warnung_gilt_fuer_Objekte" 1 "Warnung_gitl_fuer_Fussgaenger" ;
VAL_ 319 PreCrash_Tueren_Verriegeln 0 "keine_Anforderung" 1 "Tueren_Verriegeln" ;
VAL_ 319 PreCrash_FS_Laengsverstellung 0 "nicht_angefordert" 1 "angefordert" ;
VAL_ 319 PreCrash_Anforderung_AFR 0 "keine_Anforderung" 1 "linke_Seite" 2 "rechte_Seite" 3 "Vorderachse" 4 "Hinterachse" 5 "Vorwarnung" 7 "Init" ;
VAL_ 319 SC_PreCrash_LED 0 "keine_Anzeige" 1 "Stufe_1_glimmen" 2 "Stufe_2_leuchten" 3 "Stufe_3_blinken" ;
VAL_ 319 PreCrash_FS_Pneumatik_ansteuern 0 "keine_Anforderung" 1 "Pneumatik_ansteuern" ;
VAL_ 319 PreCrash_BFS_Pneumatik_ansteuern 0 "keine_Anforderung" 1 "Pneumatik_ansteuern" ;
VAL_ 319 PreCrash_Fo_Pneumatik_ansteuern 0 "keine_Anforderung" 1 "Pneumatik_ansteuern" ;
VAL_ 319 PreCrash_FS_Sitzlehne_verfahren 0 "keine_Anforderung" 1 "Sitzlehne_in_pos_x-Richtung_verfahren(vor)" 2 "Sitzlehne_in_neg_x-Richtung_verfahren(zurueck)" 3 "Sitzlehnenkopf_in_pos_x-Richtung_verfahren(vor)" 4 "Sitzlehnenkopf_in_neg_x-Richtung_verfahren(zurueck)" 6 "Lehnenverstellung_ansteuern" 7 "Lehnenkopfverstellung_ansteuern" ;
VAL_ 319 PreCrash_BFS_Sitzlehne_verfahren 0 "keine_Anforderung" 1 "Sitzlehne_in_pos_x-Richtung_verfahren(vor)" 2 "Sitzlehne_in_neg_x-Richtung_verfahren(zurueck)" 3 "Sitzlehnenkopf_in_pos_x-Richtung_verfahren(vor)" 4 "Sitzlehnenkopf_in_neg_x-Richtung_verfahren(zurueck)" 6 "Lehnenverstellung_ansteuern" 7 "Lehnenkopfverstellung_ansteuern" ;
VAL_ 319 PreCrash_Fo_Sitzlehne_verfahren 0 "keine_Anforderung" 1 "Sitzlehne_in_pos_x-Richtung_verfahren(vor)" 2 "Sitzlehne_in_neg_x-Richtung_verfahren(zurueck)" 3 "Sitzlehnenkopf_in_pos_x-Richtung_verfahren(vor)" 4 "Sitzlehnenkopf_in_neg_x-Richtung_verfahren(zurueck)" ;
VAL_ 319 PreCrash_FS_KSV_verfahren 0 "keine_Anforderung" 1 "in_pos_x-Richtung_verfahren" 2 "in_neg_x-Richung_verfahren" 3 "in_pos_z-Richtung_verfahren" 4 "in_neg_z-Richtung_verfahren" 5 "in_pos_x-Richtung_und_neg_z-Richtung_verfahren" 6 "in_pos_x_Richtung_und_pos_z-Richtung_verfahren" 7 "in_neg_x-Richtung_und_neg_z-Richtung_verfahren" 8 "in_neg_x-Richtung_und_pos_z-Richtung_verfahren" 9 "Kopfstuetze_ansteuern" ;
VAL_ 319 PreCrash_BFS_KSV_verfahren 0 "keine_Anforderung" 1 "in_pos_x-Richtung_verfahren" 2 "in_neg_x-Richung_verfahren" 3 "in_pos_z-Richtung_verfahren" 4 "in_neg_z-Richtung_verfahren" 5 "in_pos_x-Richtung_und_neg_z-Richtung_verfahren" 6 "in_pos_x_Richtung_und_pos_z-Richtung_verfahren" 7 "in_neg_x-Richtung_und_neg_z-Richtung_verfahren" 8 "in_neg_x-Richtung_und_pos_z-Richtung_verfahren" 9 "Kopfstuetze_ansteuern" ;
VAL_ 319 PreCrash_Fo_KSV_verfahren 0 "keine_Anforderung" 1 "in_pos_x-Richtung_verfahren" 2 "in_neg_x-Richung_verfahren" 3 "in_pos_z-Richtung_verfahren" 4 "in_neg_z-Richtung_verfahren" 5 "in_pos_x-Richtung_und_neg_z-Richtung_verfahren" 6 "in_pos_x_Richtung_und_pos_z-Richtung_verfahren" 7 "in_neg_x-Richtung_und_neg_z-Richtung_verfahren" 8 "in_neg_x-Richtung_und_pos_z-Richtung_verfahren" ;
VAL_ 319 PreCrash_BFS_Laengsverstellung 0 "nicht_angefordert" 1 "angefordert" ;
VAL_ 319 SC_PreCrash_Warnung 0 "keine_Anzeige" 1 "latente_Vorwarnung" 2 "Vorwarnung" 3 "Akutwarnung" 4 "Eingriff" 5 "Fahreruebernahmeaufforderung" 6 "Abbiegewarnung" 7 "Basiseingriff" 8 "Heckeingriff" ;
VAL_ 319 SC_PreCrash_Texte 0 "keine_Anzeige" 1 "Systemstoerung" 2 "keine_Sensorsicht" 3 "Demomodus" 4 "System_aus" 5 "Anhaengerbetrieb" 6 "ESC_aus" 7 "zurzeit_eingeschraenkt" 8 "zurzeit_eingeschraenkt_ESP_Aus" 9 "Initialisierung" ;
VAL_ 1122 PSD_Segment_ID 0 "keine Segmentinformationen vorhanden" 1 "Fehlerwert" ;
VAL_ 1122 PSD_Vorgaenger_Segment_ID 0 "keine Segmentinformation vorhanden" 1 "Fehlerwert" ;
VAL_ 1122 PSD_Strassenkategorie 0 "Rest_Feldweg_Schotterweg_Privatweg" 1 "Ortsstraße" 2 "Kreisstraße" 3 "Landstraße" 4 "Bundesstraße" 5 "Autobahn" 7 "Init" ;
VAL_ 1122 PSD_Endkruemmung 255 "Gerade" ;
VAL_ 1122 PSD_Endkruemmung_Vorz 0 "Kruemmung_positiv" 1 "Kruemmung_negativ" ;
VAL_ 1122 PSD_Idenditaets_ID 0 "keine_Segment_Informationen_vorhanden" 1 "Fehler" ;
VAL_ 1122 PSD_ADAS_Qualitaet 0 "keine_ADAS_Qualitaet" 1 "ADAS_Qualitaet" ;
VAL_ 1122 PSD_wahrscheinlichster_Pfad 0 "Pfad_mit_geringer_Wahrscheinlichkeit" 1 "wahrscheinlichster_Pfad" ;
VAL_ 1122 PSD_Geradester_Pfad 0 "nicht_geradester_PFad" 1 "geradester_Pfad" ;
VAL_ 1122 PSD_Fahrspuren_Anzahl 0 "Einbahnstrasse_in_falsche_Richtung" 1 "eine_Fahrspur" 2 "zwei_Fahrspuren" 3 "drei_Fahrspuren" 4 "vier_Fahrspuren" 5 "fuenf_Fahrspuren" 6 "sechs_Fahrspuren" 7 "mehr_als_sechs_Fahrspuren" ;
VAL_ 1122 PSD_Bebauung 0 "ausserhalb_bebauten_Gebietes" 1 "innerhalb_bebauten_Gebietes" ;
VAL_ 1122 PSD_Segment_Komplett 0 "Segment_Attribute_nicht_komplett" 1 "Segment_Attribute_komplett" ;
VAL_ 1122 PSD_Rampe 0 "Strasse_mit_Gegenverkehr" 1 "Auffahrt_Einbahnstr" 2 "Abfahrt_Einbahnstr" 3 "Einbahnstrasse" ;
VAL_ 1122 PSD_Anfangskruemmung 255 "Gerade" ;
VAL_ 1122 PSD_Anfangskruemmung_Vorz 0 "positiv" 1 "negativ" ;
VAL_ 1122 PSD_Abzweigerichtung 0 "rects_abzweigende_Strasse" 1 "links_abzweigende_Strasse" ;
VAL_ 1123 PSD_Pos_Segment_ID 0 "keine Position gegeben" 1 "Fehlerwert" ;
VAL_ 1123 PSD_Pos_Standort_Eindeutig 0 "mehrdeutiger_Standort" 1 "eindeutiger_Standort" ;
VAL_ 1123 PSD_Pos_Fehler_Laengsrichtung 0 "Init" 1 "< 2m" 2 "< 5m" 3 "< 10m" 4 "< 20m" 5 "< 50m" 6 "> 50m" 7 "Off-Road" ;
VAL_ 1123 PSD_Pos_Fahrspur 0 "unbekannt" 1 "Erste_Spur_von_rechts" 2 "Zweite_Spur_von_rechts" 3 "Dritte_Spur_von_rechts" 4 "Vierte_Spur_von_rechts" 5 "Fuenfte_Spur_von_rechts" 6 "Sechte_Spur_von_rechts" 7 "Siebte_oder_weitere_Spur_von_rechts" ;
VAL_ 1123 PSD_Attribut_Segment_ID_05 0 "keine_Segment_Information" 1 "Fehler" ;
VAL_ 1123 PSD_Attribut_1_ID 0 "keine_Information" ;
VAL_ 1123 PSD_Attribut_2_ID 0 "keine_Information" ;
VAL_ 1123 PSD_Attribute_Komplett_05 0 "Attribute_nicht_komplett" 1 "Attribute_komplett" ;
VAL_ 1124 PSD_06_Mux 0 "Init" ;
VAL_ 1124 PSD_Sys_Segment_ID 0 "keine Segmentinformationen vorhanden" 1 "nicht zulaessig" ;
VAL_ 1124 PSD_Attribut_Segment_ID 0 "keine_Segment_Information_vorhanden" 1 "Fehler" ;
VAL_ 1124 PSD_Ges_Segment_ID 0 "keine Segmentinformationen vorhanden" 1 "nicht zulaessig" ;
VAL_ 1124 PSD_Baum_Laenge_VZ 0 "Ost" 1 "West" ;
VAL_ 1124 PSD_Steigung_1_Segment_ID 0 "keine_Segment_Information_vorhanden" 1 "Fehler" ;
VAL_ 1124 PSD_Baum_Laenge 33554431 "keine_GPS_Information" ;
VAL_ 1124 PSD_Attribut_3_ID 0 "keine_Information" ;
VAL_ 1124 PSD_Steigung_1_A_Steigung 126 "mehr_als_15_Prozent" 127 "Steigung_unbekannt" ;
VAL_ 1124 PSD_Ges_Geschwindigkeit 0 "Kein Geschwindigkeitsgebot" 1 "0 km/h < v_max <  5 km/h" 2 "5 km/h < v_max < 10km/h" 3 "10 km/h < v_max < 15 km/h" 4 "15 km/h < v_max < 20 km/h" 5 "20 km/h < v_max < 25 km/h" 6 "25 km/h < v_max < 30 km/h" 7 "30 km/h < v_max < 35 km/h" 8 "35 km/h < v_max < 40 km/h" 9 "40 km/h < v_max < 45 km/h" 10 "45 km/h < v_max < 50 km/h" 11 "50 km/h < v_max < 60 km/h" 12 "60 km/h < v_max < 70 km/h" 13 "70 km/h < v_max < 80 km/h" 14 "80 km/h < v_max < 90 km/h" 15 "90 km/h < v_max < 100 km/h" 16 "100 km/h < v_max < 110 km/h" 17 "110 km/h < v_max < 120 km/h" 18 " 120 km/h < v_max < 130 km/h" 19 "130 km/h < v_max < 140 km/h" 20 "140 km/h < v_max < 150 km/h" 21 "150 km/h < v_max < 160 km/h" 22 "160 km/h < v_max" 23 "Geschwindigkeitsgebot aufgehoben" 24 "..0x1F ungültig" ;
VAL_ 1124 PSD_Steigung_1_A_Vorz 0 "Gefaelle" 1 "Steigung" ;
VAL_ 1124 PSD_Sys_Geschwindigkeit_Einheit 0 "km/h" 1 "mph" ;
VAL_ 1124 PSD_Sys_Verkehrsrichtung 0 "Rechtsverkehr" 1 "Linksverkehr" ;
VAL_ 1124 PSD_Sys_Geometrieguete 0 "Geringe_Guete" 1 "tbd" 2 "tbd" 3 "Hohe_Guete" ;
VAL_ 1124 PSD_Sys_Mapmatchingguete 0 "geringe_Guete" 1 "res" 2 "res" 3 "hohe_Guete" ;
VAL_ 1124 PSD_Ges_Typ 0 "Geschw_Klasse_des_Kartendatensuppliers" 1 "Explizit_abgeleiteten_Begrenzung" 2 "Durch_Gesetzg_vorgeg_allgem_Gebot_fuer_uebertr_Rahmenbed" 3 "Init" ;
VAL_ 1124 PSD_Sys_Alter_Karte 0 "kleiner_1_Jahr" 1 "1_Jahr" 2 "2_Jahre" 3 "3_Jahre" 4 "4_Jahre" 5 "5_Jahre" 6 "6_Jahre" 7 "groesser_7_Jahre" ;
VAL_ 1124 PSD_Ges_Spur_Geschw_Begrenzung 0 "Gebot_fuer_alle_spuren_gueltig" ;
VAL_ 1124 PSD_Steigung_1_B_Steigung 126 "mehr_als_15_Prozent" 127 "Steigung_unbekannt" ;
VAL_ 1124 PSD_Attribut_4_ID 0 "keine_Information" ;
VAL_ 1124 PSD_Sys_Zielfuehrung 0 "Zielfuehrung nicht aktiv" 1 "Zielfuehrung aktiv" ;
VAL_ 1124 PSD_Sys_US_State 0 "kein_US_State" 1 "Alabama" 2 "Alaska" 3 "Arkansas" 4 "Arizona" 5 "California" 6 "Colorado" 7 "Conneticut" 8 "District_of_Columbia" 9 "Delaware" 10 "Florida" 11 "Georgia" 12 "Hawaii" 13 "Idaho" 14 "Illinois" 15 "Iowa" 16 "Indiana" 17 "Kansas" 18 "Kentucky" 19 "Louisiana" 20 "Massachusetts" 21 "Maryland" 22 "Maine" 23 "Michigan" 24 "Minnesota" 25 "Missouri" 26 "Mississippi" 27 "Montana" 28 "North_Carolina" 29 "North_Dakota" 30 "Nebraska" 31 "Nevada" 32 "New_Hampshire" 33 "New_Jersey" 34 "New_Mexico" 35 "New_York" 36 "Ohio" 37 "Oklahoma" 38 "Oregon" 39 "Pennsylvania" 40 "Puerto_Rico" 41 "Rhode_Island" 42 "South_Carolina" 43 "South_Dakota" 44 "Tennessee" 45 "Texas" 46 "Utah" 47 "Virginia" 48 "Virgin_Islands" 49 "Vermont" 50 "Washington" 51 "Wisconsin" 52 "West_Virginia" 53 "Wyoming" ;
VAL_ 1124 PSD_Ges_Geschwindigkeit_Gespann 0 "alle Fahrzeuge" 1 "PKW mit Gespann" 2 "LKW, Busse, etc." ;
VAL_ 1124 PSD_Baum_Breite_VZ 0 "Nord" 1 "Sued" ;
VAL_ 1124 PSD_Ges_Geschwindigkeit_Witter 0 "Witterungsunabhängig" 1 "Nässe, Regen, Niederschlag" 2 "Glätte" 3 "Nebel" ;
VAL_ 1124 PSD_Steigung_1_B_Vorz 0 "Gefaelle" 1 "Steigung" ;
VAL_ 1124 PSD_Ges_Geschwindigkeit_Tag_Anf 0 "kein Beginn definiert" 1 "Montag" 2 "Dienstag" 3 "Mittwoch" 4 "Donnerstag" 5 "Freitag" 6 "Samstag" 7 "Sonntag" ;
VAL_ 1124 PSD_Ges_Geschwindigkeit_Tag_Ende 0 "kein Ende definiert" 1 "Montag" 2 "Dienstag" 3 "Mittwoch" 4 "Donnerstag" 5 "Freitag" 6 "Samstag" 7 "Sonntag" ;
VAL_ 1124 PSD_Sys_Quali_verfuegbar 0 "Qualitaetskriterien_nicht_verfuegbar" 1 "Qualitaetskriterien_verfuegbar" ;
VAL_ 1124 PSD_Sys_Zielfuehrung_geaendert 0 "Zielfuehrung_nicht_geaendert" 1 "Zielfuehrung_geaendert" ;
VAL_ 1124 PSD_Ges_Geschwindigkeit_Std_Anf 25 "kein Beginn für stundenweise Einschränkungen" ;
VAL_ 1124 PSD_Steigung_1_Attribute_kompl 0 "Steigungen_nicht_komplett" 1 "Steigungen_komplett" ;
VAL_ 1124 PSD_Sys_Geometrieguete_erweitert 0 "Init" ;
VAL_ 1124 PSD_Steigung_2_Segment_ID 0 "keine_Segment_Information_vorhanden" 1 "Fehler" ;
VAL_ 1124 PSD_Attribut_5_ID 0 "keine_Information" ;
VAL_ 1124 PSD_Ges_Geschwindigkeit_Std_Ende 25 "kein Ende für stundenweise Einschränkungen" ;
VAL_ 1124 PSD_Steigung_2_Steigung 126 "mehr_als_15_Prozent" 127 "Steigung_unbekannt" ;
VAL_ 1124 PSD_Ges_Ueberholverbot 0 "kein Überholverbot" 1 "alle Fahrzeuge" 2 "Überholverbot für PKW mit Gespann" 3 "Überholverbot für LKW, Busse, etc." ;
VAL_ 1124 PSD_Ges_Wechselverkehrszeichen 0 "Kein Wechselverkehrszeichen" 1 "Wechselverkehrszeichen links" 2 "Wechselverkehrszeichen rechts" 3 "Wechselverkehrszeichen links und rechts" 4 "Wechselverkerhszeichen über der Fahrbahn" ;
VAL_ 1124 PSD_Steigung_2_Vorz 0 "Gefaelle" 1 "Steigung" ;
VAL_ 1124 PSD_Wechselverkehrszeichen_Typ 0 "kein_Wechselverkehrszeichen" 1 "LED_Wechselverkehrszeichen" 2 "nicht_LED_Wechselverkehrszeichen" ;
VAL_ 1124 PSD_Ges_Gesetzlich_Kategorie 0 "kein_legales_Verbot" 1 "innerorts" 2 "ausserorts" 3 "Autobahn" ;
VAL_ 1124 PSD_Attribute_Komplett_06 0 "Attribute_nicht_komplett" 1 "Attribute_komplett" ;
VAL_ 1124 PSD_Ges_Gesetzlich_Zusatz 0 "kein_Zusatz_zu_legalem_Gebot" 1 "Anhaenger_Klasse_1" 2 "Anhaenger_Klasse_2" ;
VAL_ 1124 PSD_Ges_Verkehrszeichen_Quelle 0 "VZA_kein_Onlinedienst" 1 "nur_VZA" 2 "nur_VZO" 3 "VZA_und_VZO" ;
VAL_ 1124 PSD_Steigung_2_Attribute_kompl 0 "Steigungen_nicht_komplett" 1 "Steigungen_komplett" ;
VAL_ 1124 PSD_Ges_Attribute_Komplett 0 "Attribute_nicht_komplett" 1 "Attribute_komplett" ;
VAL_ 591 RDR1_relevanter_Fehler 0 "kein_relevanter_Fehler" 1 "relevanter_Fehler" ;
VAL_ 591 RDR1_Blindheit_erkannt 0 "keine_Blindheit_erkannt" 1 "Blindheit_erkannt" ;
VAL_ 591 RDR1_relev_Nichtverfuegbarkeit 0 "verfuegbar" 1 "nicht_verfuegbar" ;
VAL_ 591 RDR1_Verkehrssinn 0 "init" 1 "Linksverkehr" 2 "Rechtsverkehr" 3 "Unbekannt" ;
VAL_ 591 RDR1_Objekte_02_Datenalter 1023 "Daten_aelter_als_Maximum" ;
VAL_ 591 RDR1_Obj_01_ax_v 255 "Init" ;
VAL_ 591 RDR1_Obj_01_ax_StdA 63 "Init" ;
VAL_ 591 RDR1_Obj_01_vx_StdA 127 "Init" ;
VAL_ 591 RDR1_Obj_01_dx_StdA 127 "Init" ;
VAL_ 591 RDR1_Obj_01_dy_StdA 127 "Init" ;
